VERSION ""

NS_ :

BS_:

BU_:

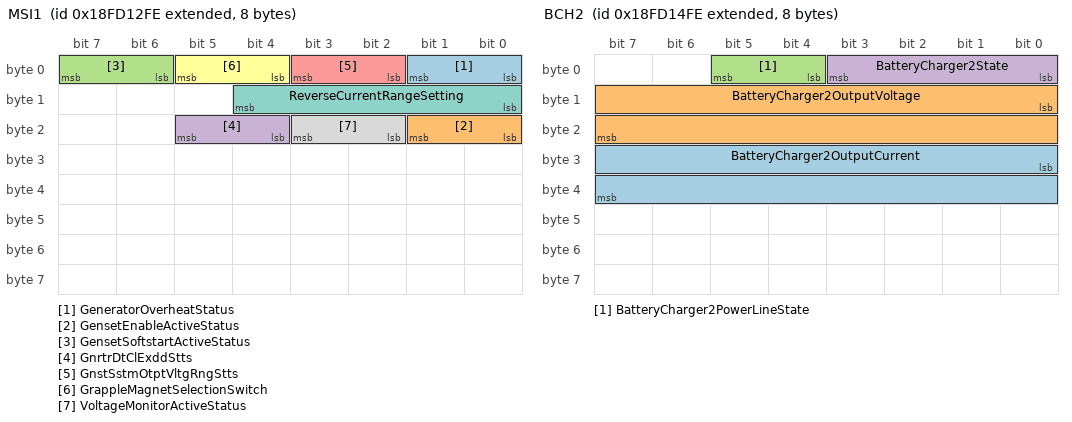
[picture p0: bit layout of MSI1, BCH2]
BO_ 2566722302 MSI1: 8 Vector__XXX
 SG_ GeneratorOverheatStatus : 0|2@1+ (1,0) [0|3] "" Vector__XXX
 SG_ GensetEnableActiveStatus : 16|2@1+ (1,0) [0|3] "" Vector__XXX
 SG_ GensetSoftstartActiveStatus : 6|2@1+ (1,0) [0|3] "" Vector__XXX
 SG_ GnrtrDtClExddStts : 20|2@1+ (1,0) [0|3] "" Vector__XXX
 SG_ GnstSstmOtptVltgRngStts : 2|2@1+ (1,0) [0|3] "" Vector__XXX
 SG_ GrappleMagnetSelectionSwitch : 4|2@1+ (1,0) [0|3] "" Vector__XXX
 SG_ ReverseCurrentRangeSetting : 8|5@1+ (1,0) [0|31] "" Vector__XXX
 SG_ VoltageMonitorActiveStatus : 18|2@1+ (1,0) [0|3] "" Vector__XXX

BO_ 2566722558 MSCI: 8 Vector__XXX
 SG_ MagnetBoostTime : 0|8@1+ (0.25,0) [0|62.5] "s" Vector__XXX
 SG_ MagnetRatedPower : 8|16@1+ (0.5,0) [0|32127.5] "kW" Vector__XXX

BO_ 2566722814 BCH2: 8 Vector__XXX
 SG_ BatteryCharger2OutputCurrent : 24|16@1+ (0.05,-1600) [-1600|1612.75] "A" Vector__XXX
 SG_ BatteryCharger2OutputVoltage : 8|16@1+ (0.05,0) [0|3212.75] "V" Vector__XXX
 SG_ BatteryCharger2PowerLineState : 4|2@1+ (1,0) [0|3] "" Vector__XXX
 SG_ BatteryCharger2State : 0|4@1+ (1,0) [0|15] "" Vector__XXX

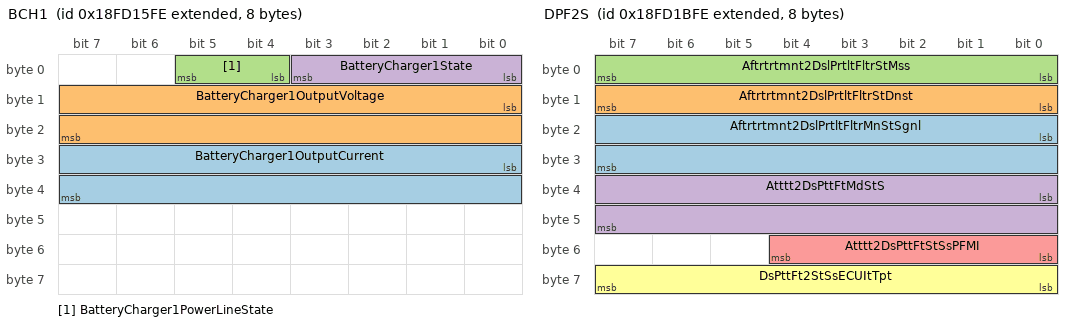
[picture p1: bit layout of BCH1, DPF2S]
BO_ 2566723070 BCH1: 8 Vector__XXX
 SG_ BatteryCharger1OutputCurrent : 24|16@1+ (0.05,-1600) [-1600|1612.75] "A" Vector__XXX
 SG_ BatteryCharger1OutputVoltage : 8|16@1+ (0.05,0) [0|3212.75] "V" Vector__XXX
 SG_ BatteryCharger1PowerLineState : 4|2@1+ (1,0) [0|3] "" Vector__XXX
 SG_ BatteryCharger1State : 0|4@1+ (1,0) [0|15] "" Vector__XXX

BO_ 2566724350 AT1WUDOC: 8 Vector__XXX
 SG_ Atttt1WUpDsOxdtCtstItTpt : 0|16@1+ (0.03125,-273) [-273|1734.96875] "degC" Vector__XXX
 SG_ Atttt1WUpDsOxdtCtstOttTpt : 16|16@1+ (0.03125,-273) [-273|1734.96875] "degC" Vector__XXX

BO_ 2566724606 DPF2S: 8 Vector__XXX
 SG_ Aftrtrtmnt2DslPrtltFltrMnStSgnl : 16|16@1+ (0.0025,0) [0|160.6375] "%" Vector__XXX
 SG_ Aftrtrtmnt2DslPrtltFltrStDnst : 8|8@1+ (0.08,0) [0|20] "g/L" Vector__XXX
 SG_ Aftrtrtmnt2DslPrtltFltrStMss : 0|8@1+ (4,0) [0|1000] "g" Vector__XXX
 SG_ Atttt2DsPttFtMdStS : 32|16@1+ (0.0025,0) [0|160.6375] "%" Vector__XXX
 SG_ Atttt2DsPttFtStSsPFMI : 48|5@1+ (1,0) [0|31] "binary" Vector__XXX
 SG_ DsPttFt2StSsECUItTpt : 56|8@1+ (1,-40) [-40|210] "degC" Vector__XXX

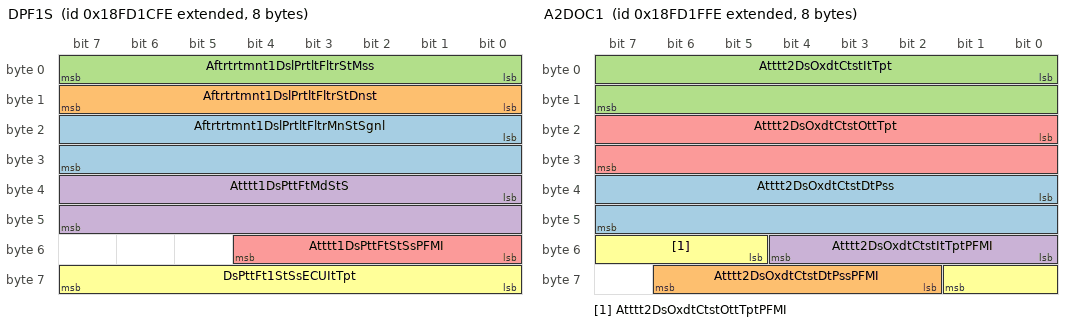
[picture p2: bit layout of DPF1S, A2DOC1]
BO_ 2566724862 DPF1S: 8 Vector__XXX
 SG_ Aftrtrtmnt1DslPrtltFltrMnStSgnl : 16|16@1+ (0.0025,0) [0|160.6375] "%" Vector__XXX
 SG_ Aftrtrtmnt1DslPrtltFltrStDnst : 8|8@1+ (0.08,0) [0|20] "g/L" Vector__XXX
 SG_ Aftrtrtmnt1DslPrtltFltrStMss : 0|8@1+ (4,0) [0|1000] "g" Vector__XXX
 SG_ Atttt1DsPttFtMdStS : 32|16@1+ (0.0025,0) [0|160.6375] "%" Vector__XXX
 SG_ Atttt1DsPttFtStSsPFMI : 48|5@1+ (1,0) [0|31] "binary" Vector__XXX
 SG_ DsPttFt1StSsECUItTpt : 56|8@1+ (1,-40) [-40|210] "degC" Vector__XXX

BO_ 2566725118 ATDT2: 8 Vector__XXX
 SG_ Atttt1TWCtstDtTpt : 0|16@1+ (0.03125,-273) [-273|1734.96875] "degC" Vector__XXX
 SG_ Atttt2TWCtstDtTpt : 16|16@1+ (0.03125,-273) [-273|1734.96875] "degC" Vector__XXX

BO_ 2566725374 ATDT1: 8 Vector__XXX
 SG_ Atttt1GsOxdtCtstDtTpt : 0|16@1+ (0.03125,-273) [-273|1734.96875] "degC" Vector__XXX
 SG_ Atttt2GsOxdtCtstDtTpt : 16|16@1+ (0.03125,-273) [-273|1734.96875] "degC" Vector__XXX

BO_ 2566725630 A2DOC1: 8 Vector__XXX
 SG_ Atttt2DsOxdtCtstDtPss : 32|16@1+ (0.5,0) [0|32127.5] "kPa" Vector__XXX
 SG_ Atttt2DsOxdtCtstDtPssPFMI : 58|5@1+ (1,0) [0|31] "binary" Vector__XXX
 SG_ Atttt2DsOxdtCtstItTpt : 0|16@1+ (0.03125,-273) [-273|1734.96875] "degC" Vector__XXX
 SG_ Atttt2DsOxdtCtstItTptPFMI : 48|5@1+ (1,0) [0|31] "binary" Vector__XXX
 SG_ Atttt2DsOxdtCtstOttTpt : 16|16@1+ (0.03125,-273) [-273|1734.96875] "degC" Vector__XXX
 SG_ Atttt2DsOxdtCtstOttTptPFMI : 53|5@1+ (1,0) [0|31] "binary" Vector__XXX

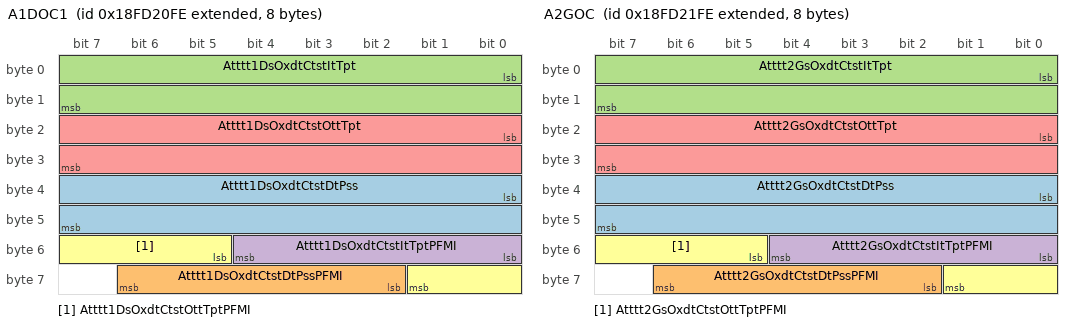
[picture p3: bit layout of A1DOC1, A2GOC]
BO_ 2566725886 A1DOC1: 8 Vector__XXX
 SG_ Atttt1DsOxdtCtstDtPss : 32|16@1+ (0.1,0) [0|6425.5] "kPa" Vector__XXX
 SG_ Atttt1DsOxdtCtstDtPssPFMI : 58|5@1+ (1,0) [0|31] "binary" Vector__XXX
 SG_ Atttt1DsOxdtCtstItTpt : 0|16@1+ (0.03125,-273) [-273|1734.96875] "degC" Vector__XXX
 SG_ Atttt1DsOxdtCtstItTptPFMI : 48|5@1+ (1,0) [0|31] "binary" Vector__XXX
 SG_ Atttt1DsOxdtCtstOttTpt : 16|16@1+ (0.03125,-273) [-273|1734.96875] "degC" Vector__XXX
 SG_ Atttt1DsOxdtCtstOttTptPFMI : 53|5@1+ (1,0) [0|31] "binary" Vector__XXX

BO_ 2566726142 A2GOC: 8 Vector__XXX
 SG_ Atttt2GsOxdtCtstDtPss : 32|16@1+ (0.1,0) [0|6425.5] "kPa" Vector__XXX
 SG_ Atttt2GsOxdtCtstDtPssPFMI : 58|5@1+ (1,0) [0|31] "binary" Vector__XXX
 SG_ Atttt2GsOxdtCtstItTpt : 0|16@1+ (0.03125,-273) [-273|1734.96875] "degC" Vector__XXX
 SG_ Atttt2GsOxdtCtstItTptPFMI : 48|5@1+ (1,0) [0|31] "binary" Vector__XXX
 SG_ Atttt2GsOxdtCtstOttTpt : 16|16@1+ (0.03125,-273) [-273|1734.96875] "degC" Vector__XXX
 SG_ Atttt2GsOxdtCtstOttTptPFMI : 53|5@1+ (1,0) [0|31] "binary" Vector__XXX

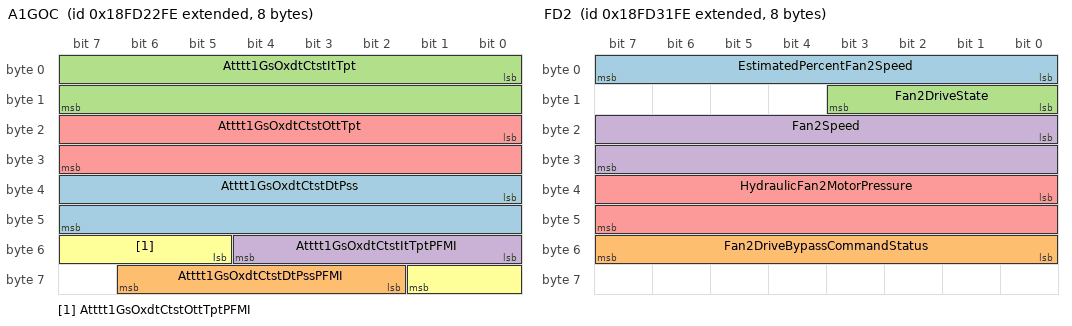
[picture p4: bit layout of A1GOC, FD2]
BO_ 2566726398 A1GOC: 8 Vector__XXX
 SG_ Atttt1GsOxdtCtstDtPss : 32|16@1+ (0.1,0) [0|6425.5] "kPa" Vector__XXX
 SG_ Atttt1GsOxdtCtstDtPssPFMI : 58|5@1+ (1,0) [0|31] "binary" Vector__XXX
 SG_ Atttt1GsOxdtCtstItTpt : 0|16@1+ (0.03125,-273) [-273|1734.96875] "degC" Vector__XXX
 SG_ Atttt1GsOxdtCtstItTptPFMI : 48|5@1+ (1,0) [0|31] "binary" Vector__XXX
 SG_ Atttt1GsOxdtCtstOttTpt : 16|16@1+ (0.03125,-273) [-273|1734.96875] "degC" Vector__XXX
 SG_ Atttt1GsOxdtCtstOttTptPFMI : 53|5@1+ (1,0) [0|31] "binary" Vector__XXX

BO_ 2566730238 FD2: 8 Vector__XXX
 SG_ EstimatedPercentFan2Speed : 0|8@1+ (0.4,0) [0|100] "%" Vector__XXX
 SG_ Fan2DriveBypassCommandStatus : 48|8@1+ (0.4,0) [0|100] "%" Vector__XXX
 SG_ Fan2DriveState : 8|4@1+ (1,0) [0|15] "" Vector__XXX
 SG_ Fan2Speed : 16|16@1+ (0.125,0) [0|8031.875] "rpm" Vector__XXX
 SG_ HydraulicFan2MotorPressure : 32|16@1+ (0.5,0) [0|32127.5] "kPa" Vector__XXX

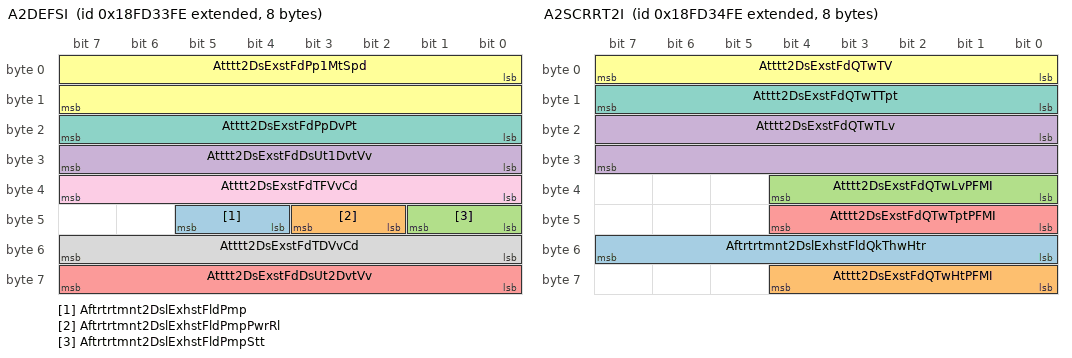
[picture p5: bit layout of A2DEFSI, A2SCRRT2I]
BO_ 2566730750 A2DEFSI: 8 Vector__XXX
 SG_ Aftrtrtmnt2DslExhstFldPmp : 44|2@1+ (1,0) [0|3] "" Vector__XXX
 SG_ Aftrtrtmnt2DslExhstFldPmpPwrRl : 42|2@1+ (1,0) [0|3] "" Vector__XXX
 SG_ Aftrtrtmnt2DslExhstFldPmpStt : 40|2@1+ (1,0) [0|3] "" Vector__XXX
 SG_ Atttt2DsExstFdDsUt1DvtVv : 24|8@1+ (0.4,0) [0|100] "%" Vector__XXX
 SG_ Atttt2DsExstFdDsUt2DvtVv : 56|8@1+ (0.4,0) [0|100] "%" Vector__XXX
 SG_ Atttt2DsExstFdPp1MtSpd : 0|16@1+ (0.5,0) [0|32127.5] "rpm" Vector__XXX
 SG_ Atttt2DsExstFdPpDvPt : 16|8@1+ (0.4,0) [0|100] "%" Vector__XXX
 SG_ Atttt2DsExstFdTDVvCd : 48|8@1+ (0.4,0) [0|100] "%" Vector__XXX
 SG_ Atttt2DsExstFdTFVvCd : 32|8@1+ (0.4,0) [0|100] "%" Vector__XXX

BO_ 2566731006 A2SCRRT2I: 8 Vector__XXX
 SG_ Aftrtrtmnt2DslExhstFldQkThwHtr : 48|8@1+ (0.4,0) [0|100] "%" Vector__XXX
 SG_ Atttt2DsExstFdQTwHtPFMI : 56|5@1+ (1,0) [0|31] "binary" Vector__XXX
 SG_ Atttt2DsExstFdQTwLvPFMI : 32|5@1+ (1,0) [0|31] "binary" Vector__XXX
 SG_ Atttt2DsExstFdQTwTLv : 16|16@1+ (0.1,0) [0|6425.5] "mm" Vector__XXX
 SG_ Atttt2DsExstFdQTwTptPFMI : 40|5@1+ (1,0) [0|31] "binary" Vector__XXX
 SG_ Atttt2DsExstFdQTwTV : 0|8@1+ (0.4,0) [0|100] "%" Vector__XXX
 SG_ Atttt2DsExstFdQTwTTpt : 8|8@1+ (1,-40) [-40|210] "degC" Vector__XXX

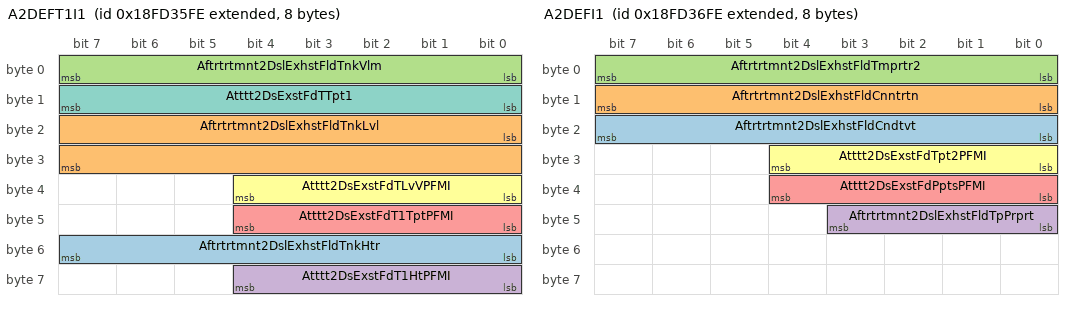
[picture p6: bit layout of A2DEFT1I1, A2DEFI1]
BO_ 2566731262 A2DEFT1I1: 8 Vector__XXX
 SG_ Aftrtrtmnt2DslExhstFldTnkHtr : 48|8@1+ (0.4,0) [0|100] "%" Vector__XXX
 SG_ Aftrtrtmnt2DslExhstFldTnkLvl : 16|16@1+ (0.1,0) [0|6425.5] "mm" Vector__XXX
 SG_ Aftrtrtmnt2DslExhstFldTnkVlm : 0|8@1+ (0.4,0) [0|100] "%" Vector__XXX
 SG_ Atttt2DsExstFdT1HtPFMI : 56|5@1+ (1,0) [0|31] "binary" Vector__XXX
 SG_ Atttt2DsExstFdT1TptPFMI : 40|5@1+ (1,0) [0|31] "binary" Vector__XXX
 SG_ Atttt2DsExstFdTLvVPFMI : 32|5@1+ (1,0) [0|31] "binary" Vector__XXX
 SG_ Atttt2DsExstFdTTpt1 : 8|8@1+ (1,-40) [-40|210] "degC" Vector__XXX

BO_ 2566731518 A2DEFI1: 8 Vector__XXX
 SG_ Aftrtrtmnt2DslExhstFldCndtvt : 16|8@1+ (5,0) [0|1250] "µSiemens/mm" Vector__XXX
 SG_ Aftrtrtmnt2DslExhstFldCnntrtn : 8|8@1+ (0.25,0) [0|62.5] "%" Vector__XXX
 SG_ Aftrtrtmnt2DslExhstFldTmprtr2 : 0|8@1+ (1,-40) [-40|210] "degC" Vector__XXX
 SG_ Aftrtrtmnt2DslExhstFldTpPrprt : 40|4@1+ (1,0) [0|15] "" Vector__XXX
 SG_ Atttt2DsExstFdPptsPFMI : 32|5@1+ (1,0) [0|31] "binary" Vector__XXX
 SG_ Atttt2DsExstFdTpt2PFMI : 24|5@1+ (1,0) [0|31] "binary" Vector__XXX

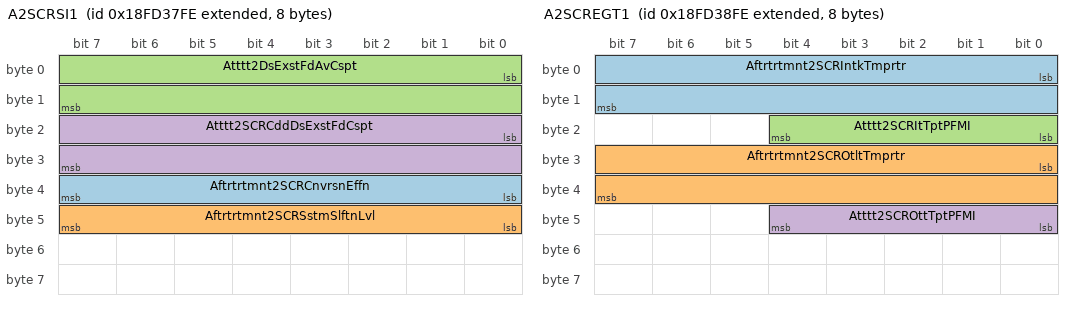
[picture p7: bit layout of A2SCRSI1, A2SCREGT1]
BO_ 2566731774 A2SCRSI1: 8 Vector__XXX
 SG_ Aftrtrtmnt2SCRCnvrsnEffn : 32|8@1+ (0.4,0) [0|100] "%" Vector__XXX
 SG_ Aftrtrtmnt2SCRSstmSlftnLvl : 40|8@1+ (1,0) [0|250] "%" Vector__XXX
 SG_ Atttt2DsExstFdAvCspt : 0|16@1+ (0.05,0) [0|3212.75] "l/h" Vector__XXX
 SG_ Atttt2SCRCddDsExstFdCspt : 16|16@1+ (0.05,0) [0|3212.75] "l/h" Vector__XXX

BO_ 2566732030 A2SCREGT1: 8 Vector__XXX
 SG_ Aftrtrtmnt2SCRIntkTmprtr : 0|16@1+ (0.03125,-273) [-273|1734.96875] "degC" Vector__XXX
 SG_ Aftrtrtmnt2SCROtltTmprtr : 24|16@1+ (0.03125,-273) [-273|1734.96875] "degC" Vector__XXX
 SG_ Atttt2SCRItTptPFMI : 16|5@1+ (1,0) [0|31] "" Vector__XXX
 SG_ Atttt2SCROttTptPFMI : 40|5@1+ (1,0) [0|31] "" Vector__XXX

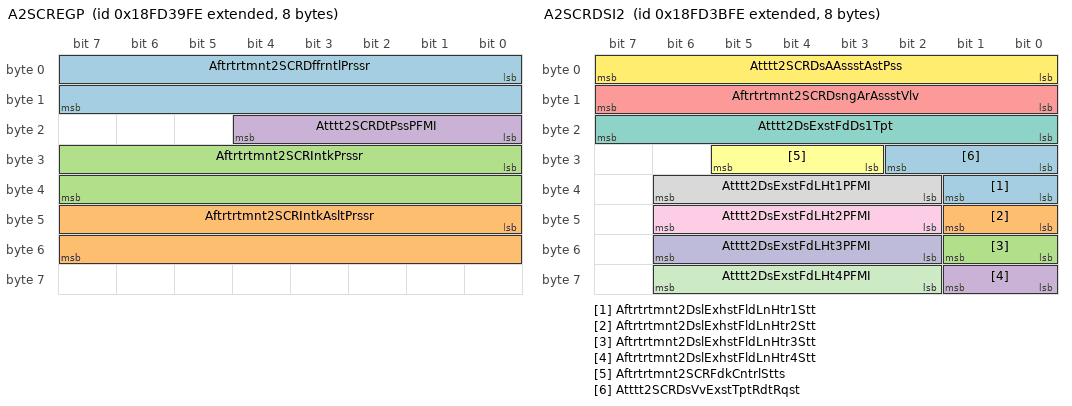
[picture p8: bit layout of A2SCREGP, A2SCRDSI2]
BO_ 2566732286 A2SCREGP: 8 Vector__XXX
 SG_ Aftrtrtmnt2SCRDffrntlPrssr : 0|16@1+ (0.1,0) [0|6425.5] "kPa" Vector__XXX
 SG_ Aftrtrtmnt2SCRIntkAsltPrssr : 40|16@1+ (0.1,0) [0|6425.5] "kPa" Vector__XXX
 SG_ Aftrtrtmnt2SCRIntkPrssr : 24|16@1+ (0.1,-3212.7) [-3212.7|3212.8] "kPa" Vector__XXX
 SG_ Atttt2SCRDtPssPFMI : 16|5@1+ (1,0) [0|31] "" Vector__XXX

BO_ 2566732542 A2SCRDSR2: 8 Vector__XXX
 SG_ Aftrtrtmnt2DslExhstFldLnHtr1 : 8|2@1+ (1,0) [0|3] "" Vector__XXX
 SG_ Aftrtrtmnt2DslExhstFldLnHtr10 : 48|2@1+ (1,0) [0|3] "" Vector__XXX
 SG_ Aftrtrtmnt2DslExhstFldLnHtr2 : 10|2@1+ (1,0) [0|3] "" Vector__XXX
 SG_ Aftrtrtmnt2DslExhstFldLnHtr3 : 12|2@1+ (1,0) [0|3] "" Vector__XXX
 SG_ Aftrtrtmnt2DslExhstFldLnHtr4 : 14|2@1+ (1,0) [0|3] "" Vector__XXX
 SG_ Aftrtrtmnt2DslExhstFldLnHtr5 : 38|2@1+ (1,0) [0|3] "" Vector__XXX
 SG_ Aftrtrtmnt2DslExhstFldLnHtr6 : 40|2@1+ (1,0) [0|3] "" Vector__XXX
 SG_ Aftrtrtmnt2DslExhstFldLnHtr7 : 42|2@1+ (1,0) [0|3] "" Vector__XXX
 SG_ Aftrtrtmnt2DslExhstFldLnHtr8 : 44|2@1+ (1,0) [0|3] "" Vector__XXX
 SG_ Aftrtrtmnt2DslExhstFldLnHtr9 : 46|2@1+ (1,0) [0|3] "" Vector__XXX
 SG_ Aftrtrtmnt2DslExhstFldLnHtrRl1 : 32|2@1+ (1,0) [0|3] "" Vector__XXX
 SG_ Aftrtrtmnt2DslExhstFldLnHtrRl2 : 34|2@1+ (1,0) [0|3] "" Vector__XXX
 SG_ Aftrtrtmnt2DslExhstFldLnHtrRl3 : 36|2@1+ (1,0) [0|3] "" Vector__XXX
 SG_ Atttt2DsExstFdDsFtSppssRqst : 2|2@1+ (1,0) [0|3] "" Vector__XXX
 SG_ Atttt2DsExstFdDsHtMdRqst : 4|3@1+ (1,0) [0|7] "" Vector__XXX
 SG_ Atttt2DsExstFdQTwHtCd : 24|8@1+ (0.4,0) [0|100] "%" Vector__XXX
 SG_ Atttt2DsExstFdTHtCd : 16|8@1+ (0.4,0) [0|100] "%" Vector__XXX

BO_ 2566732798 A2SCRDSI2: 8 Vector__XXX
 SG_ Aftrtrtmnt2DslExhstFldLnHtr1Stt : 32|2@1+ (1,0) [0|3] "" Vector__XXX
 SG_ Aftrtrtmnt2DslExhstFldLnHtr2Stt : 40|2@1+ (1,0) [0|3] "" Vector__XXX
 SG_ Aftrtrtmnt2DslExhstFldLnHtr3Stt : 48|2@1+ (1,0) [0|3] "" Vector__XXX
 SG_ Aftrtrtmnt2DslExhstFldLnHtr4Stt : 56|2@1+ (1,0) [0|3] "" Vector__XXX
 SG_ Aftrtrtmnt2SCRDsngArAssstVlv : 8|8@1+ (0.4,0) [0|100] "%" Vector__XXX
 SG_ Aftrtrtmnt2SCRFdkCntrlStts : 27|3@1+ (1,0) [0|7] "" Vector__XXX
 SG_ Atttt2DsExstFdDs1Tpt : 16|8@1+ (1,-40) [-40|210] "degC" Vector__XXX
 SG_ Atttt2DsExstFdLHt1PFMI : 34|5@1+ (1,0) [0|31] "binary" Vector__XXX
 SG_ Atttt2DsExstFdLHt2PFMI : 42|5@1+ (1,0) [0|31] "binary" Vector__XXX
 SG_ Atttt2DsExstFdLHt3PFMI : 50|5@1+ (1,0) [0|31] "binary" Vector__XXX
 SG_ Atttt2DsExstFdLHt4PFMI : 58|5@1+ (1,0) [0|31] "binary" Vector__XXX
 SG_ Atttt2SCRDsAAssstAstPss : 0|8@1+ (8,0) [0|2000] "kPa" Vector__XXX
 SG_ Atttt2SCRDsVvExstTptRdtRqst : 24|3@1+ (1,0) [0|7] "" Vector__XXX

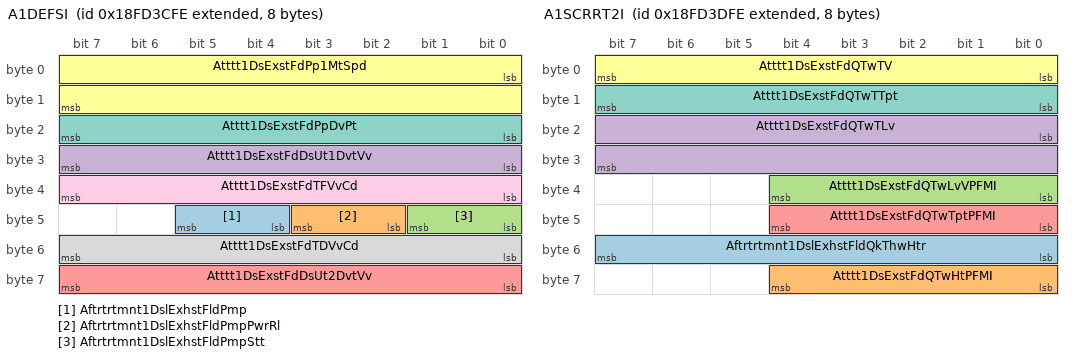
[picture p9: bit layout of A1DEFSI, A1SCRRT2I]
BO_ 2566733054 A1DEFSI: 8 Vector__XXX
 SG_ Aftrtrtmnt1DslExhstFldPmp : 44|2@1+ (1,0) [0|3] "" Vector__XXX
 SG_ Aftrtrtmnt1DslExhstFldPmpPwrRl : 42|2@1+ (1,0) [0|3] "" Vector__XXX
 SG_ Aftrtrtmnt1DslExhstFldPmpStt : 40|2@1+ (1,0) [0|3] "" Vector__XXX
 SG_ Atttt1DsExstFdDsUt1DvtVv : 24|8@1+ (0.4,0) [0|100] "%" Vector__XXX
 SG_ Atttt1DsExstFdDsUt2DvtVv : 56|8@1+ (0.4,0) [0|100] "%" Vector__XXX
 SG_ Atttt1DsExstFdPp1MtSpd : 0|16@1+ (0.5,0) [0|32127.5] "rpm" Vector__XXX
 SG_ Atttt1DsExstFdPpDvPt : 16|8@1+ (0.4,0) [0|100] "%" Vector__XXX
 SG_ Atttt1DsExstFdTDVvCd : 48|8@1+ (0.4,0) [0|100] "%" Vector__XXX
 SG_ Atttt1DsExstFdTFVvCd : 32|8@1+ (0.4,0) [0|100] "%" Vector__XXX

BO_ 2566733310 A1SCRRT2I: 8 Vector__XXX
 SG_ Aftrtrtmnt1DslExhstFldQkThwHtr : 48|8@1+ (0.4,0) [0|100] "%" Vector__XXX
 SG_ Atttt1DsExstFdQTwHtPFMI : 56|5@1+ (1,0) [0|31] "binary" Vector__XXX
 SG_ Atttt1DsExstFdQTwLvVPFMI : 32|5@1+ (1,0) [0|31] "binary" Vector__XXX
 SG_ Atttt1DsExstFdQTwTLv : 16|16@1+ (0.1,0) [0|6425.5] "mm" Vector__XXX
 SG_ Atttt1DsExstFdQTwTptPFMI : 40|5@1+ (1,0) [0|31] "binary" Vector__XXX
 SG_ Atttt1DsExstFdQTwTV : 0|8@1+ (0.4,0) [0|100] "%" Vector__XXX
 SG_ Atttt1DsExstFdQTwTTpt : 8|8@1+ (1,-40) [-40|210] "degC" Vector__XXX

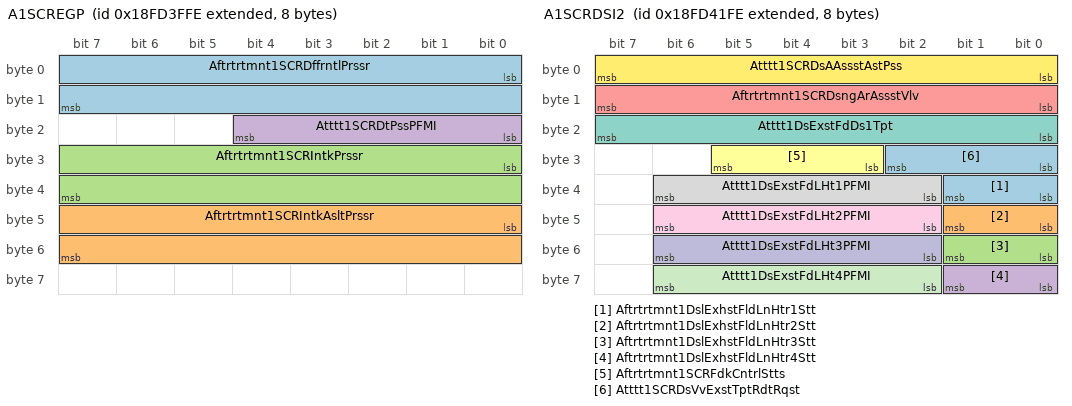
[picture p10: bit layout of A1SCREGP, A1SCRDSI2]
BO_ 2566733822 A1SCREGP: 8 Vector__XXX
 SG_ Aftrtrtmnt1SCRDffrntlPrssr : 0|16@1+ (0.1,0) [0|6425.5] "kPa" Vector__XXX
 SG_ Aftrtrtmnt1SCRIntkAsltPrssr : 40|16@1+ (0.1,0) [0|6425.5] "kPa" Vector__XXX
 SG_ Aftrtrtmnt1SCRIntkPrssr : 24|16@1+ (0.1,-3212.7) [-3212.7|3212.8] "kPa" Vector__XXX
 SG_ Atttt1SCRDtPssPFMI : 16|5@1+ (1,0) [0|31] "" Vector__XXX

BO_ 2566734078 A1SCRDSR2: 8 Vector__XXX
 SG_ Aftrtrtmnt1DslExhstFldLnHtr1 : 8|2@1+ (1,0) [0|3] "" Vector__XXX
 SG_ Aftrtrtmnt1DslExhstFldLnHtr10 : 56|2@1+ (1,0) [0|3] "" Vector__XXX
 SG_ Aftrtrtmnt1DslExhstFldLnHtr2 : 10|2@1+ (1,0) [0|3] "" Vector__XXX
 SG_ Aftrtrtmnt1DslExhstFldLnHtr3 : 12|2@1+ (1,0) [0|3] "" Vector__XXX
 SG_ Aftrtrtmnt1DslExhstFldLnHtr4 : 14|2@1+ (1,0) [0|3] "" Vector__XXX
 SG_ Aftrtrtmnt1DslExhstFldLnHtr5 : 46|2@1+ (1,0) [0|3] "" Vector__XXX
 SG_ Aftrtrtmnt1DslExhstFldLnHtr6 : 48|2@1+ (1,0) [0|3] "" Vector__XXX
 SG_ Aftrtrtmnt1DslExhstFldLnHtr7 : 50|2@1+ (1,0) [0|3] "" Vector__XXX
 SG_ Aftrtrtmnt1DslExhstFldLnHtr8 : 52|2@1+ (1,0) [0|3] "" Vector__XXX
 SG_ Aftrtrtmnt1DslExhstFldLnHtr9 : 54|2@1+ (1,0) [0|3] "" Vector__XXX
 SG_ Aftrtrtmnt1DslExhstFldLnHtrRl1 : 40|2@1+ (1,0) [0|3] "" Vector__XXX
 SG_ Aftrtrtmnt1DslExhstFldLnHtrRl2 : 42|2@1+ (1,0) [0|3] "" Vector__XXX
 SG_ Aftrtrtmnt1DslExhstFldLnHtrRl3 : 44|2@1+ (1,0) [0|3] "" Vector__XXX
 SG_ Atttt1DsExstFdDsFtSppssRqst : 2|2@1+ (1,0) [0|3] "" Vector__XXX
 SG_ Atttt1DsExstFdDsHtMdRqst : 4|3@1+ (1,0) [0|7] "" Vector__XXX
 SG_ Atttt1DsExstFdPpHtCd : 32|8@1+ (0.4,0) [0|100] "%" Vector__XXX
 SG_ Atttt1DsExstFdQTwHtCd : 24|8@1+ (0.4,0) [0|100] "%" Vector__XXX
 SG_ Atttt1DsExstFdTHtCd : 16|8@1+ (0.4,0) [0|100] "%" Vector__XXX

BO_ 2566734334 A1SCRDSI2: 8 Vector__XXX
 SG_ Aftrtrtmnt1DslExhstFldLnHtr1Stt : 32|2@1+ (1,0) [0|3] "" Vector__XXX
 SG_ Aftrtrtmnt1DslExhstFldLnHtr2Stt : 40|2@1+ (1,0) [0|3] "" Vector__XXX
 SG_ Aftrtrtmnt1DslExhstFldLnHtr3Stt : 48|2@1+ (1,0) [0|3] "" Vector__XXX
 SG_ Aftrtrtmnt1DslExhstFldLnHtr4Stt : 56|2@1+ (1,0) [0|3] "" Vector__XXX
 SG_ Aftrtrtmnt1SCRDsngArAssstVlv : 8|8@1+ (0.4,0) [0|100] "%" Vector__XXX
 SG_ Aftrtrtmnt1SCRFdkCntrlStts : 27|3@1+ (1,0) [0|7] "" Vector__XXX
 SG_ Atttt1DsExstFdDs1Tpt : 16|8@1+ (1,-40) [-40|210] "degC" Vector__XXX
 SG_ Atttt1DsExstFdLHt1PFMI : 34|5@1+ (1,0) [0|31] "binary" Vector__XXX
 SG_ Atttt1DsExstFdLHt2PFMI : 42|5@1+ (1,0) [0|31] "binary" Vector__XXX
 SG_ Atttt1DsExstFdLHt3PFMI : 50|5@1+ (1,0) [0|31] "binary" Vector__XXX
 SG_ Atttt1DsExstFdLHt4PFMI : 58|5@1+ (1,0) [0|31] "binary" Vector__XXX
 SG_ Atttt1SCRDsAAssstAstPss : 0|8@1+ (8,0) [0|2000] "kPa" Vector__XXX
 SG_ Atttt1SCRDsVvExstTptRdtRqst : 24|3@1+ (1,0) [0|7] "" Vector__XXX

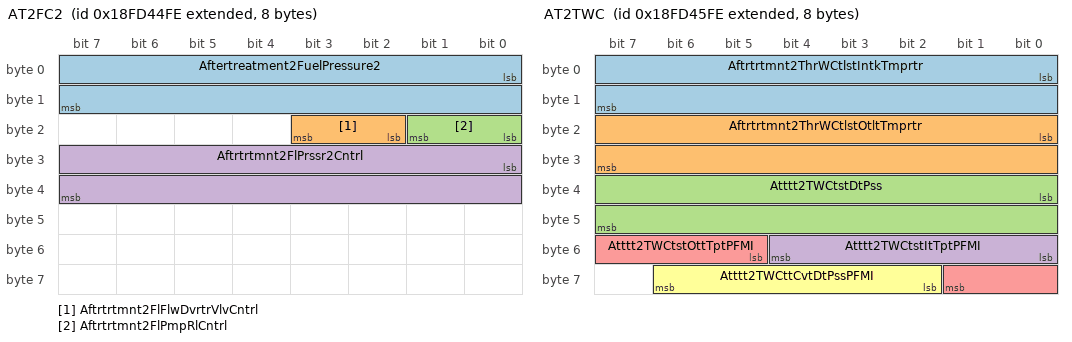
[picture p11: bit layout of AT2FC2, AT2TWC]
BO_ 2566735102 AT2FC2: 8 Vector__XXX
 SG_ Aftertreatment2FuelPressure2 : 0|16@1+ (0.1,0) [0|6425.5] "kPa" Vector__XXX
 SG_ Aftrtrtmnt2FlFlwDvrtrVlvCntrl : 18|2@1+ (1,0) [0|3] "" Vector__XXX
 SG_ Aftrtrtmnt2FlPmpRlCntrl : 16|2@1+ (1,0) [0|3] "" Vector__XXX
 SG_ Aftrtrtmnt2FlPrssr2Cntrl : 24|16@1+ (0.0025,0) [0|160.6375] "%" Vector__XXX

BO_ 2566735358 AT2TWC: 8 Vector__XXX
 SG_ Aftrtrtmnt2ThrWCtlstIntkTmprtr : 0|16@1+ (0.03125,-273) [-273|1734.96875] "degC" Vector__XXX
 SG_ Aftrtrtmnt2ThrWCtlstOtltTmprtr : 16|16@1+ (0.03125,-273) [-273|1734.96875] "degC" Vector__XXX
 SG_ Atttt2TWCtstDtPss : 32|16@1+ (0.1,0) [0|6425.5] "kPa" Vector__XXX
 SG_ Atttt2TWCtstItTptPFMI : 48|5@1+ (1,0) [0|31] "binary" Vector__XXX
 SG_ Atttt2TWCtstOttTptPFMI : 53|5@1+ (1,0) [0|31] "binary" Vector__XXX
 SG_ Atttt2TWCttCvtDtPssPFMI : 58|5@1+ (1,0) [0|31] "binary" Vector__XXX

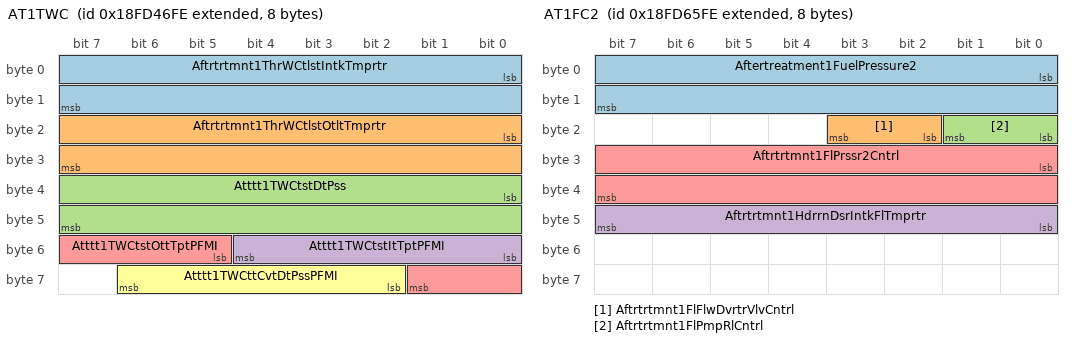
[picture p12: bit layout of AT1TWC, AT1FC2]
BO_ 2566735614 AT1TWC: 8 Vector__XXX
 SG_ Aftrtrtmnt1ThrWCtlstIntkTmprtr : 0|16@1+ (0.03125,-273) [-273|1734.96875] "degC" Vector__XXX
 SG_ Aftrtrtmnt1ThrWCtlstOtltTmprtr : 16|16@1+ (0.03125,-273) [-273|1734.96875] "degC" Vector__XXX
 SG_ Atttt1TWCtstDtPss : 32|16@1+ (0.1,0) [0|6425.5] "kPa" Vector__XXX
 SG_ Atttt1TWCtstItTptPFMI : 48|5@1+ (1,0) [0|31] "binary" Vector__XXX
 SG_ Atttt1TWCtstOttTptPFMI : 53|5@1+ (1,0) [0|31] "binary" Vector__XXX
 SG_ Atttt1TWCttCvtDtPssPFMI : 58|5@1+ (1,0) [0|31] "binary" Vector__XXX

BO_ 2566736126 O2FT2: 8 Vector__XXX
 SG_ EngnExhstBnk2O2SnsrClsdLpOprtn : 32|4@1+ (1,0) [0|15] "" Vector__XXX
 SG_ LongtermFuelTrimBank2 : 0|16@1+ (0.1,-100) [-100|6325.5] "%" Vector__XXX
 SG_ ShorttermFuelTrimBank2 : 16|16@1+ (0.1,-100) [-100|6325.5] "%" Vector__XXX

BO_ 2566736382 O2FT1: 8 Vector__XXX
 SG_ EngnExhstBnk1O2SnsrClsdLpOprtn : 32|4@1+ (1,0) [0|15] "" Vector__XXX
 SG_ LongtermFuelTrimBank1 : 0|16@1+ (0.1,-100) [-100|6325.5] "%" Vector__XXX
 SG_ ShorttermFuelTrimBank1 : 16|16@1+ (0.1,-100) [-100|6325.5] "%" Vector__XXX

BO_ 2566743550 AT1FC2: 8 Vector__XXX
 SG_ Aftertreatment1FuelPressure2 : 0|16@1+ (0.1,0) [0|6425.5] "kPa" Vector__XXX
 SG_ Aftrtrtmnt1FlFlwDvrtrVlvCntrl : 18|2@1+ (1,0) [0|3] "" Vector__XXX
 SG_ Aftrtrtmnt1FlPmpRlCntrl : 16|2@1+ (1,0) [0|3] "" Vector__XXX
 SG_ Aftrtrtmnt1HdrrnDsrIntkFlTmprtr : 40|8@1+ (1,-40) [-40|210] "degC" Vector__XXX
 SG_ Aftrtrtmnt1FlPrssr2Cntrl : 24|16@1+ (0.0025,0) [0|160.6375] "%" Vector__XXX

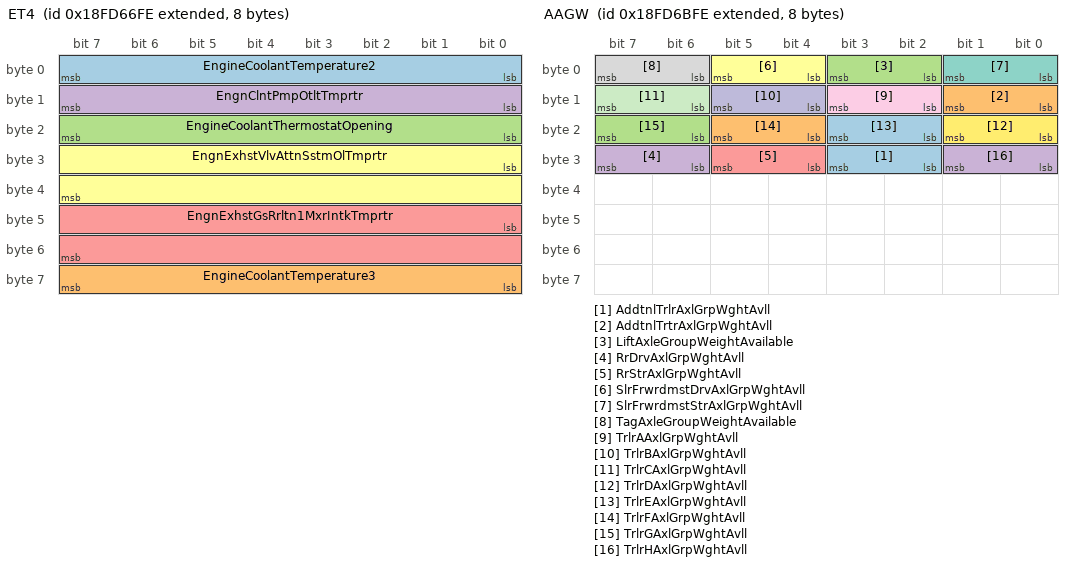
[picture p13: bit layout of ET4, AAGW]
BO_ 2566743806 ET4: 8 Vector__XXX
 SG_ EngineCoolantTemperature2 : 0|8@1+ (1,-40) [-40|210] "degC" Vector__XXX
 SG_ EngineCoolantTemperature3 : 56|8@1+ (1,-40) [-40|210] "degC" Vector__XXX
 SG_ EngineCoolantThermostatOpening : 16|8@1+ (0.4,0) [0|100] "%" Vector__XXX
 SG_ EngnClntPmpOtltTmprtr : 8|8@1+ (1,-40) [-40|210] "degC" Vector__XXX
 SG_ EngnExhstGsRrltn1MxrIntkTmprtr : 40|16@1+ (0.03125,-273) [-273|1734.96875] "degC" Vector__XXX
 SG_ EngnExhstVlvAttnSstmOlTmprtr : 24|16@1+ (0.03125,-273) [-273|1734.96875] "degC" Vector__XXX

BO_ 2566744062 ZNVW: 8 Vector__XXX
 SG_ ZeroNetVehicleWeightChange : 0|2@1+ (1,0) [0|3] "" Vector__XXX

BO_ 2566745086 AAGW: 8 Vector__XXX
 SG_ AddtnlTrlrAxlGrpWghtAvll : 26|2@1+ (1,0) [0|3] "" Vector__XXX
 SG_ AddtnlTrtrAxlGrpWghtAvll : 8|2@1+ (1,0) [0|3] "" Vector__XXX
 SG_ LiftAxleGroupWeightAvailable : 2|2@1+ (1,0) [0|3] "" Vector__XXX
 SG_ RrDrvAxlGrpWghtAvll : 30|2@1+ (1,0) [0|3] "" Vector__XXX
 SG_ RrStrAxlGrpWghtAvll : 28|2@1+ (1,0) [0|3] "" Vector__XXX
 SG_ SlrFrwrdmstDrvAxlGrpWghtAvll : 4|2@1+ (1,0) [0|3] "" Vector__XXX
 SG_ SlrFrwrdmstStrAxlGrpWghtAvll : 0|2@1+ (1,0) [0|3] "" Vector__XXX
 SG_ TagAxleGroupWeightAvailable : 6|2@1+ (1,0) [0|3] "" Vector__XXX
 SG_ TrlrAAxlGrpWghtAvll : 10|2@1+ (1,0) [0|3] "" Vector__XXX
 SG_ TrlrBAxlGrpWghtAvll : 12|2@1+ (1,0) [0|3] "" Vector__XXX
 SG_ TrlrCAxlGrpWghtAvll : 14|2@1+ (1,0) [0|3] "" Vector__XXX
 SG_ TrlrDAxlGrpWghtAvll : 16|2@1+ (1,0) [0|3] "" Vector__XXX
 SG_ TrlrEAxlGrpWghtAvll : 18|2@1+ (1,0) [0|3] "" Vector__XXX
 SG_ TrlrFAxlGrpWghtAvll : 20|2@1+ (1,0) [0|3] "" Vector__XXX
 SG_ TrlrGAxlGrpWghtAvll : 22|2@1+ (1,0) [0|3] "" Vector__XXX
 SG_ TrlrHAxlGrpWghtAvll : 24|2@1+ (1,0) [0|3] "" Vector__XXX

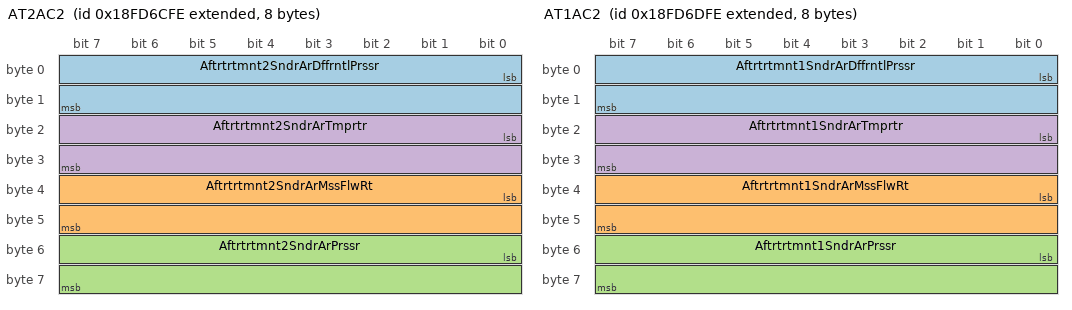
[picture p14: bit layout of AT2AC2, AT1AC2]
BO_ 2566745342 AT2AC2: 8 Vector__XXX
 SG_ Aftrtrtmnt2SndrArDffrntlPrssr : 0|16@1+ (0.0078125,-250) [-250|251.99] "kPa" Vector__XXX
 SG_ Aftrtrtmnt2SndrArMssFlwRt : 32|16@1+ (0.2,0) [0|12851] "kg/h" Vector__XXX
 SG_ Aftrtrtmnt2SndrArPrssr : 48|16@1+ (0.1,0) [0|6425.5] "kPa" Vector__XXX
 SG_ Aftrtrtmnt2SndrArTmprtr : 16|16@1+ (0.03125,-273) [-273|1734.96875] "degC" Vector__XXX

BO_ 2566745598 AT1AC2: 8 Vector__XXX
 SG_ Aftrtrtmnt1SndrArDffrntlPrssr : 0|16@1+ (0.0078125,-250) [-250|251.99] "kPa" Vector__XXX
 SG_ Aftrtrtmnt1SndrArMssFlwRt : 32|16@1+ (0.2,0) [0|12851] "kg/h" Vector__XXX
 SG_ Aftrtrtmnt1SndrArPrssr : 48|16@1+ (0.1,0) [0|6425.5] "kPa" Vector__XXX
 SG_ Aftrtrtmnt1SndrArTmprtr : 16|16@1+ (0.03125,-273) [-273|1734.96875] "degC" Vector__XXX

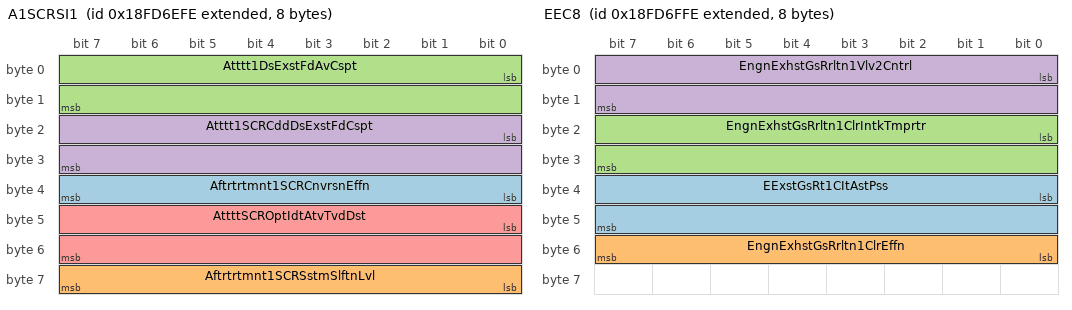
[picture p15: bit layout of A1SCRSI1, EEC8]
BO_ 2566745854 A1SCRSI1: 8 Vector__XXX
 SG_ Aftrtrtmnt1SCRCnvrsnEffn : 32|8@1+ (0.4,0) [0|100] "%" Vector__XXX
 SG_ Aftrtrtmnt1SCRSstmSlftnLvl : 56|8@1+ (1,0) [0|250] "%" Vector__XXX
 SG_ Atttt1DsExstFdAvCspt : 0|16@1+ (0.05,0) [0|3212.75] "l/h" Vector__XXX
 SG_ Atttt1SCRCddDsExstFdCspt : 16|16@1+ (0.05,0) [0|3212.75] "l/h" Vector__XXX
 SG_ AttttSCROptIdtAtvTvdDst : 40|16@1+ (1,0) [0|64255] "km" Vector__XXX

BO_ 2566746110 EEC8: 8 Vector__XXX
 SG_ EExstGsRt1CItAstPss : 32|16@1+ (0.5,0) [0|32127.5] "kPa" Vector__XXX
 SG_ EngnExhstGsRrltn1ClrEffn : 48|8@1+ (0.4,0) [0|100] "%" Vector__XXX
 SG_ EngnExhstGsRrltn1ClrIntkTmprtr : 16|16@1+ (0.03125,-273) [-273|1734.96875] "degC" Vector__XXX
 SG_ EngnExhstGsRrltn1Vlv2Cntrl : 0|16@1+ (0.0025,0) [0|160.6375] "%" Vector__XXX

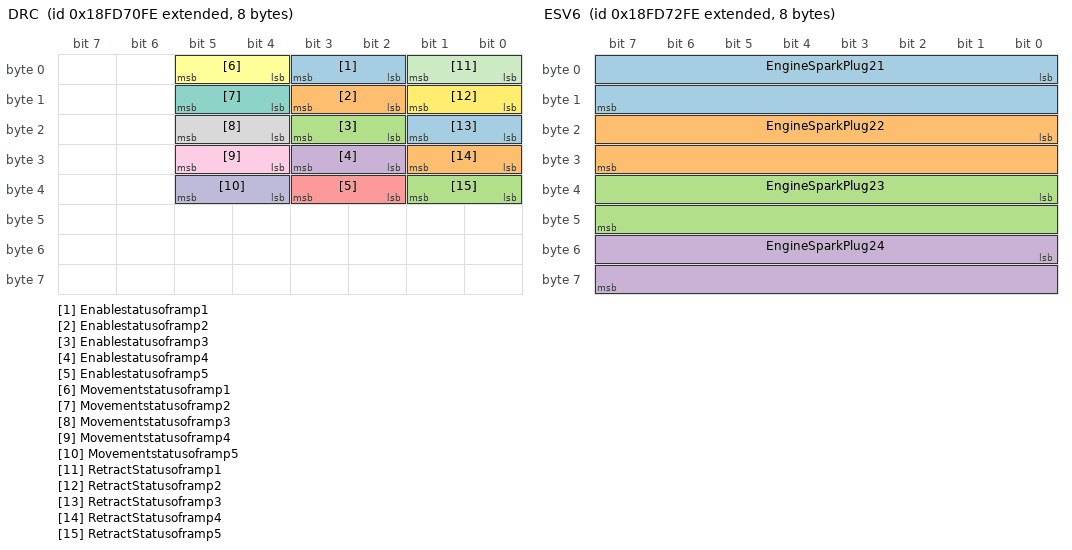
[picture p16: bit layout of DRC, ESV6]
BO_ 2566746366 DRC: 8 Vector__XXX
 SG_ Enablestatusoframp1 : 2|2@1+ (1,0) [0|3] "" Vector__XXX
 SG_ Enablestatusoframp2 : 10|2@1+ (1,0) [0|3] "" Vector__XXX
 SG_ Enablestatusoframp3 : 18|2@1+ (1,0) [0|3] "" Vector__XXX
 SG_ Enablestatusoframp4 : 26|2@1+ (1,0) [0|3] "" Vector__XXX
 SG_ Enablestatusoframp5 : 34|2@1+ (1,0) [0|3] "" Vector__XXX
 SG_ Movementstatusoframp1 : 4|2@1+ (1,0) [0|3] "" Vector__XXX
 SG_ Movementstatusoframp2 : 12|2@1+ (1,0) [0|3] "" Vector__XXX
 SG_ Movementstatusoframp3 : 20|2@1+ (1,0) [0|3] "" Vector__XXX
 SG_ Movementstatusoframp4 : 28|2@1+ (1,0) [0|3] "" Vector__XXX
 SG_ Movementstatusoframp5 : 36|2@1+ (1,0) [0|3] "" Vector__XXX
 SG_ RetractStatusoframp1 : 0|2@1+ (1,0) [0|3] "" Vector__XXX
 SG_ RetractStatusoframp2 : 8|2@1+ (1,0) [0|3] "" Vector__XXX
 SG_ RetractStatusoframp3 : 16|2@1+ (1,0) [0|3] "" Vector__XXX
 SG_ RetractStatusoframp4 : 24|2@1+ (1,0) [0|3] "" Vector__XXX
 SG_ RetractStatusoframp5 : 32|2@1+ (1,0) [0|3] "" Vector__XXX

BO_ 2566746622 BSA: 8 Vector__XXX
 SG_ TractorBrakeStrokeAxle1Left : 0|3@1+ (1,0) [0|7] "" Vector__XXX
 SG_ TractorBrakeStrokeAxle1Right : 3|3@1+ (1,0) [0|7] "" Vector__XXX
 SG_ TractorBrakeStrokeAxle2Left : 6|3@1+ (1,0) [0|7] "" Vector__XXX
 SG_ TractorBrakeStrokeAxle2Right : 9|3@1+ (1,0) [0|7] "" Vector__XXX
 SG_ TractorBrakeStrokeAxle3Left : 12|3@1+ (1,0) [0|7] "" Vector__XXX
 SG_ TractorBrakeStrokeAxle3Right : 15|3@1+ (1,0) [0|7] "" Vector__XXX
 SG_ TractorBrakeStrokeAxle4Left : 18|3@1+ (1,0) [0|7] "" Vector__XXX
 SG_ TractorBrakeStrokeAxle4Right : 21|3@1+ (1,0) [0|7] "" Vector__XXX
 SG_ TractorBrakeStrokeAxle5Left : 24|3@1+ (1,0) [0|7] "" Vector__XXX
 SG_ TractorBrakeStrokeAxle5Right : 27|3@1+ (1,0) [0|7] "" Vector__XXX
 SG_ TrailerBrakeStrokeAxle1Left : 30|3@1+ (1,0) [0|7] "" Vector__XXX
 SG_ TrailerBrakeStrokeAxle1Right : 33|3@1+ (1,0) [0|7] "" Vector__XXX
 SG_ TrailerBrakeStrokeAxle2Left : 36|3@1+ (1,0) [0|7] "" Vector__XXX
 SG_ TrailerBrakeStrokeAxle2Right : 39|3@1+ (1,0) [0|7] "" Vector__XXX
 SG_ TrailerBrakeStrokeAxle3Left : 42|3@1+ (1,0) [0|7] "" Vector__XXX
 SG_ TrailerBrakeStrokeAxle3Right : 45|3@1+ (1,0) [0|7] "" Vector__XXX
 SG_ TrailerBrakeStrokeAxle4Left : 48|3@1+ (1,0) [0|7] "" Vector__XXX
 SG_ TrailerBrakeStrokeAxle4Right : 51|3@1+ (1,0) [0|7] "" Vector__XXX
 SG_ TrailerBrakeStrokeAxle5Left : 54|3@1+ (1,0) [0|7] "" Vector__XXX
 SG_ TrailerBrakeStrokeAxle5Right : 57|3@1+ (1,0) [0|7] "" Vector__XXX

BO_ 2566746878 ESV6: 8 Vector__XXX
 SG_ EngineSparkPlug21 : 0|16@1+ (1,0) [0|64255] "V" Vector__XXX
 SG_ EngineSparkPlug22 : 16|16@1+ (1,0) [0|64255] "V" Vector__XXX
 SG_ EngineSparkPlug23 : 32|16@1+ (1,0) [0|64255] "V" Vector__XXX
 SG_ EngineSparkPlug24 : 48|16@1+ (1,0) [0|64255] "V" Vector__XXX

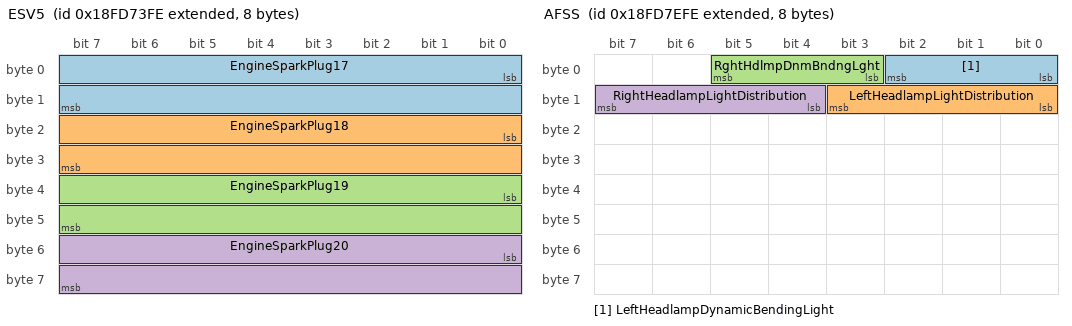
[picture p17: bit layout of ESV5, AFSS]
BO_ 2566747134 ESV5: 8 Vector__XXX
 SG_ EngineSparkPlug17 : 0|16@1+ (1,0) [0|64255] "V" Vector__XXX
 SG_ EngineSparkPlug18 : 16|16@1+ (1,0) [0|64255] "V" Vector__XXX
 SG_ EngineSparkPlug19 : 32|16@1+ (1,0) [0|64255] "V" Vector__XXX
 SG_ EngineSparkPlug20 : 48|16@1+ (1,0) [0|64255] "V" Vector__XXX

BO_ 2566747390 ESV4: 8 Vector__XXX
 SG_ EngineSparkPlug13 : 0|16@1+ (1,0) [0|64255] "V" Vector__XXX
 SG_ EngineSparkPlug14 : 16|16@1+ (1,0) [0|64255] "V" Vector__XXX
 SG_ EngineSparkPlug15 : 32|16@1+ (1,0) [0|64255] "V" Vector__XXX
 SG_ EngineSparkPlug16 : 48|16@1+ (1,0) [0|64255] "V" Vector__XXX

BO_ 2566747646 ESV3: 8 Vector__XXX
 SG_ EngineSparkPlug10 : 16|16@1+ (1,0) [0|64255] "V" Vector__XXX
 SG_ EngineSparkPlug11 : 32|16@1+ (1,0) [0|64255] "V" Vector__XXX
 SG_ EngineSparkPlug12 : 48|16@1+ (1,0) [0|64255] "V" Vector__XXX
 SG_ EngineSparkPlug9 : 0|16@1+ (1,0) [0|64255] "V" Vector__XXX

BO_ 2566747902 ESV2: 8 Vector__XXX
 SG_ EngineSparkPlug5 : 0|16@1+ (1,0) [0|64255] "V" Vector__XXX
 SG_ EngineSparkPlug6 : 16|16@1+ (1,0) [0|64255] "V" Vector__XXX
 SG_ EngineSparkPlug7 : 32|16@1+ (1,0) [0|64255] "V" Vector__XXX
 SG_ EngineSparkPlug8 : 48|16@1+ (1,0) [0|64255] "V" Vector__XXX

BO_ 2566748158 ESV1: 8 Vector__XXX
 SG_ EngineSparkPlug1 : 0|16@1+ (1,0) [0|64255] "V" Vector__XXX
 SG_ EngineSparkPlug2 : 16|16@1+ (1,0) [0|64255] "V" Vector__XXX
 SG_ EngineSparkPlug3 : 32|16@1+ (1,0) [0|64255] "V" Vector__XXX
 SG_ EngineSparkPlug4 : 48|16@1+ (1,0) [0|64255] "V" Vector__XXX

BO_ 2566748414 AT2TI: 32 Vector__XXX
 SG_ Aftrtrtmnt2DslPrtltFltrTrpFlUsd : 0|32@1+ (0.5,0) [0|2105540607.5] "l" Vector__XXX
 SG_ Atttt2DsPttFtTpAtvRtT : 32|32@1+ (1,0) [0|4211081215] "s" Vector__XXX
 SG_ Atttt2DsPttFtTpDsdT : 64|32@1+ (1,0) [0|4211081215] "s" Vector__XXX
 SG_ Atttt2DsPttFtTpNAtvRtItRqsts : 192|32@1+ (1,0) [0|4211081215] "count" Vector__XXX
 SG_ Atttt2DsPttFtTpNAtvRtMRqsts : 224|32@1+ (1,0) [0|4211081215] "count" Vector__XXX
 SG_ Atttt2DsPttFtTpNAtvRts : 96|32@1+ (1,0) [0|4211081215] "count" Vector__XXX
 SG_ Atttt2DsPttFtTpNPssvRts : 160|32@1+ (1,0) [0|4211081215] "count" Vector__XXX
 SG_ Atttt2DsPttFtTpPssvRtT : 128|32@1+ (1,0) [0|4211081215] "s" Vector__XXX

BO_ 2566748670 AT1TI: 32 Vector__XXX
 SG_ Aftrtrtmnt1DslPrtltFltrTrpFlUsd : 0|32@1+ (0.5,0) [0|2105540607.5] "l" Vector__XXX
 SG_ Atttt1DsPttFtTpAtvRtT : 32|32@1+ (1,0) [0|4211081215] "s" Vector__XXX
 SG_ Atttt1DsPttFtTpDsdT : 64|32@1+ (1,0) [0|4211081215] "s" Vector__XXX
 SG_ Atttt1DsPttFtTpNAtvRtItRqsts : 192|32@1+ (1,0) [0|4211081215] "count" Vector__XXX
 SG_ Atttt1DsPttFtTpNAtvRtMRqsts : 224|32@1+ (1,0) [0|4211081215] "count" Vector__XXX
 SG_ Atttt1DsPttFtTpNAtvRts : 96|32@1+ (1,0) [0|4211081215] "count" Vector__XXX
 SG_ Atttt1DsPttFtTpNPssvRts : 160|32@1+ (1,0) [0|4211081215] "count" Vector__XXX
 SG_ Atttt1DsPttFtTpPssvRtT : 128|32@1+ (1,0) [0|4211081215] "s" Vector__XXX

BO_ 2566748926 AT2S1: 8 Vector__XXX
 SG_ Aftrtrtmnt2DslPrtltFltrStLdPrnt : 0|8@1+ (1,0) [0|250] "%" Vector__XXX
 SG_ Atttt2DsPttFtAsLdPt : 8|8@1+ (1,0) [0|250] "%" Vector__XXX
 SG_ Atttt2DsPttFtStLdRtTsd : 48|16@1+ (0.0025,0) [0|160.6375] "%" Vector__XXX
 SG_ Atttt2DsPttFtTSLstAtvRt : 16|32@1+ (1,0) [0|4211081215] "s" Vector__XXX

BO_ 2566749182 AT1S1: 8 Vector__XXX
 SG_ Aftrtrtmnt1DslPrtltFltrStLdPrnt : 0|8@1+ (1,0) [0|250] "%" Vector__XXX
 SG_ Atttt1DsPttFtAsLdPt : 8|8@1+ (1,0) [0|250] "%" Vector__XXX
 SG_ Atttt1DsPttFtStLdRtTsd : 48|16@1+ (0.0025,0) [0|160.6375] "%" Vector__XXX
 SG_ Atttt1DsPttFtTSLstAtvRt : 16|32@1+ (1,0) [0|4211081215] "s" Vector__XXX

BO_ 2566749438 DPFC1: 8 Vector__XXX
 SG_ AftrtrtmntDslPrtltFltrStts : 12|3@1+ (1,0) [0|7] "" Vector__XXX
 SG_ Atttt1DsPttFtCdtsNtMtAtvRt : 60|2@1+ (1,0) [0|3] "" Vector__XXX
 SG_ AttttDsPttFtAtvRtStts : 10|2@1+ (1,0) [0|3] "" Vector__XXX
 SG_ AttttDsPttFtPssvRtStts : 8|2@1+ (1,0) [0|3] "" Vector__XXX
 SG_ DslPrtltFltrAtvRgnrtnAvlltStts : 3|2@1+ (1,0) [0|3] "" Vector__XXX
 SG_ DslPrtltFltrAtvRgnrtnFrdStts : 53|3@1+ (1,0) [0|7] "" Vector__XXX
 SG_ DslPrtltFltrAtvRgnrtnInhtdStts : 16|2@1+ (1,0) [0|3] "" Vector__XXX
 SG_ DslPrtltFltrLmpCmmnd : 0|3@1+ (1,0) [0|7] "" Vector__XXX
 SG_ DsPttFtAttAtvRtIttCt : 48|2@1+ (1,0) [0|3] "" Vector__XXX
 SG_ DsPttFtAtvRtItdDtAtPdOId : 26|2@1+ (1,0) [0|3] "" Vector__XXX
 SG_ DsPttFtAtvRtItdDtCtDsd : 20|2@1+ (1,0) [0|3] "" Vector__XXX
 SG_ DsPttFtAtvRtItdDtENtWdUp : 44|2@1+ (1,0) [0|3] "" Vector__XXX
 SG_ DsPttFtAtvRtItdDtItSwt : 18|2@1+ (1,0) [0|3] "" Vector__XXX
 SG_ DsPttFtAtvRtItdDtLwExstPss : 58|2@1+ (1,0) [0|3] "" Vector__XXX
 SG_ DsPttFtAtvRtItdDtLwExstTpt : 34|2@1+ (1,0) [0|3] "" Vector__XXX
 SG_ DsPttFtAtvRtItdDtOtNt : 28|2@1+ (1,0) [0|3] "" Vector__XXX
 SG_ DsPttFtAtvRtItdDtPBNtSt : 32|2@1+ (1,0) [0|3] "" Vector__XXX
 SG_ DsPttFtAtvRtItdDtPTOAtv : 24|2@1+ (1,0) [0|3] "" Vector__XXX
 SG_ DsPttFtAtvRtItdDtPtSstLt : 42|2@1+ (1,0) [0|3] "" Vector__XXX
 SG_ DsPttFtAtvRtItdDtSstFtAtv : 36|2@1+ (1,0) [0|3] "" Vector__XXX
 SG_ DsPttFtAtvRtItdDtSstTt : 38|2@1+ (1,0) [0|3] "" Vector__XXX
 SG_ DsPttFtAtvRtItdDtSvBAtv : 22|2@1+ (1,0) [0|3] "" Vector__XXX
 SG_ DsPttFtAtvRtItdDtTpSstLt : 40|2@1+ (1,0) [0|3] "" Vector__XXX
 SG_ DsPttFtAtvRtItdDtVSpdAvAwdSpd : 30|2@1+ (1,0) [0|3] "" Vector__XXX
 SG_ DsPttFtAtvRtItdDtVSpdBwAwdSpd : 46|2@1+ (1,0) [0|3] "" Vector__XXX
 SG_ ExhstSstmHghTmprtrLmpCmmnd : 50|3@1+ (1,0) [0|7] "" Vector__XXX
 SG_ HydrocarbonDoserPurgingEnable : 56|2@1+ (1,0) [0|3] "" Vector__XXX
 SG_ DsPttFtAtvRtItdDtTs : 62|2@1+ (1,0) [0|3] "" Vector__XXX

BO_ 2566749950 AFSS: 8 Vector__XXX
 SG_ LeftHeadlampDynamicBendingLight : 0|3@1+ (1,0) [0|7] "" Vector__XXX
 SG_ LeftHeadlampLightDistribution : 8|4@1+ (1,0) [0|15] "" Vector__XXX
 SG_ RghtHdlmpDnmBndngLght : 3|3@1+ (1,0) [0|7] "" Vector__XXX
 SG_ RightHeadlampLightDistribution : 12|4@1+ (1,0) [0|15] "" Vector__XXX

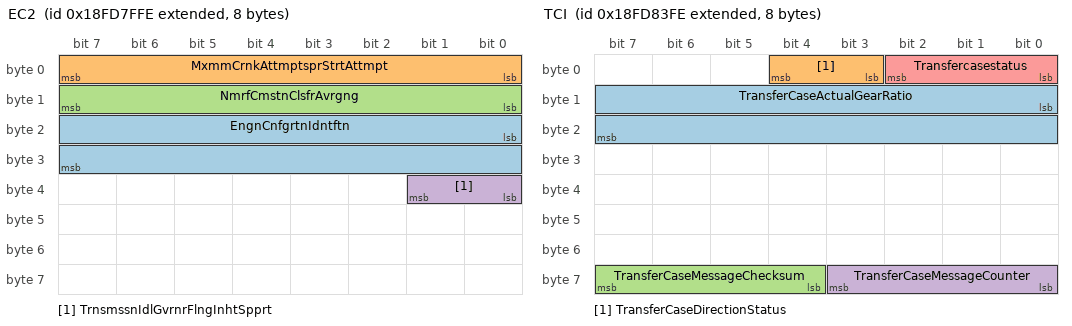
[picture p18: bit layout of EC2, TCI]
BO_ 2566750206 EC2: 8 Vector__XXX
 SG_ EngnCnfgrtnIdntftn : 16|16@1+ (1,0) [0|64255] "ID" Vector__XXX
 SG_ MxmmCrnkAttmptsprStrtAttmpt : 0|8@1+ (1,0) [0|250] "count" Vector__XXX
 SG_ NmrfCmstnClsfrAvrgng : 8|8@1+ (1,0) [0|250] "count" Vector__XXX
 SG_ TrnsmssnIdlGvrnrFlngInhtSpprt : 32|2@1+ (1,0) [0|3] "" Vector__XXX

BO_ 2566751230 TCI: 8 Vector__XXX
 SG_ TransferCaseActualGearRatio : 8|16@1+ (0.01,0) [0|642.55] "" Vector__XXX
 SG_ TransferCaseDirectionStatus : 3|2@1+ (1,0) [0|3] "" Vector__XXX
 SG_ TransferCaseMessageChecksum : 60|4@1+ (1,0) [0|15] "count" Vector__XXX
 SG_ TransferCaseMessageCounter : 56|4@1+ (1,0) [0|15] "count" Vector__XXX
 SG_ Transfercasestatus : 0|3@1+ (1,0) [0|7] "" Vector__XXX

BO_ 2566751486 EFLP9: 8 Vector__XXX
 SG_ EngnIntkVlvAttnOlPrssrfrClndr17 : 0|16@1+ (0.1,0) [0|6425.5] "kPa" Vector__XXX
 SG_ EngnIntkVlvAttnOlPrssrfrClndr18 : 16|16@1+ (0.1,0) [0|6425.5] "kPa" Vector__XXX
 SG_ EngnIntkVlvAttnOlPrssrfrClndr19 : 32|16@1+ (0.1,0) [0|6425.5] "kPa" Vector__XXX
 SG_ EngnIntkVlvAttnOlPrssrfrClndr20 : 48|16@1+ (0.1,0) [0|6425.5] "kPa" Vector__XXX

BO_ 2566751742 EFLP8: 8 Vector__XXX
 SG_ EngnIntkVlvAttnOlPrssrfrClndr13 : 0|16@1+ (0.1,0) [0|6425.5] "kPa" Vector__XXX
 SG_ EngnIntkVlvAttnOlPrssrfrClndr14 : 16|16@1+ (0.1,0) [0|6425.5] "kPa" Vector__XXX
 SG_ EngnIntkVlvAttnOlPrssrfrClndr15 : 32|16@1+ (0.1,0) [0|6425.5] "kPa" Vector__XXX
 SG_ EngnIntkVlvAttnOlPrssrfrClndr16 : 48|16@1+ (0.1,0) [0|6425.5] "kPa" Vector__XXX

BO_ 2566751998 EFLP7: 8 Vector__XXX
 SG_ EngnIntkVlvAttnOlPrssrfrClndr10 : 16|16@1+ (0.1,0) [0|6425.5] "kPa" Vector__XXX
 SG_ EngnIntkVlvAttnOlPrssrfrClndr11 : 32|16@1+ (0.1,0) [0|6425.5] "kPa" Vector__XXX
 SG_ EngnIntkVlvAttnOlPrssrfrClndr12 : 48|16@1+ (0.1,0) [0|6425.5] "kPa" Vector__XXX
 SG_ EngnIntkVlvAttnOlPrssrfrClndr9 : 0|16@1+ (0.1,0) [0|6425.5] "kPa" Vector__XXX

BO_ 2566752254 EFLP6: 8 Vector__XXX
 SG_ EngnIntkVlvAttnOlPrssrfrClndr5 : 0|16@1+ (0.1,0) [0|6425.5] "kPa" Vector__XXX
 SG_ EngnIntkVlvAttnOlPrssrfrClndr6 : 16|16@1+ (0.1,0) [0|6425.5] "kPa" Vector__XXX
 SG_ EngnIntkVlvAttnOlPrssrfrClndr7 : 32|16@1+ (0.1,0) [0|6425.5] "kPa" Vector__XXX
 SG_ EngnIntkVlvAttnOlPrssrfrClndr8 : 48|16@1+ (0.1,0) [0|6425.5] "kPa" Vector__XXX

BO_ 2566752510 EFLP5: 8 Vector__XXX
 SG_ EngnIntkVlvAttnOlPrssrfrClndr1 : 0|16@1+ (0.1,0) [0|6425.5] "kPa" Vector__XXX
 SG_ EngnIntkVlvAttnOlPrssrfrClndr2 : 16|16@1+ (0.1,0) [0|6425.5] "kPa" Vector__XXX
 SG_ EngnIntkVlvAttnOlPrssrfrClndr3 : 32|16@1+ (0.1,0) [0|6425.5] "kPa" Vector__XXX
 SG_ EngnIntkVlvAttnOlPrssrfrClndr4 : 48|16@1+ (0.1,0) [0|6425.5] "kPa" Vector__XXX

BO_ 2566752766 VDS2: 8 Vector__XXX
 SG_ VehicleRoll : 0|16@1+ (0.0078125,-200) [-200|301.99] "deg" Vector__XXX

BO_ 2566753278 AT2GP: 8 Vector__XXX
 SG_ Atttt2DsPttFtItPss : 0|16@1+ (0.1,0) [0|6425.5] "kPa" Vector__XXX
 SG_ Atttt2DsPttFtOttPss : 16|16@1+ (0.1,0) [0|6425.5] "kPa" Vector__XXX

BO_ 2566753534 AT1GP: 8 Vector__XXX
 SG_ Atttt1DsPttFtItPss : 0|16@1+ (0.1,0) [0|6425.5] "kPa" Vector__XXX
 SG_ Atttt1DsPttFtOttPss : 16|16@1+ (0.1,0) [0|6425.5] "kPa" Vector__XXX

BO_ 2566753790 UTACER: 8 Vector__XXX
 SG_ UtilityTotalkVArHoursExport : 0|32@1+ (1,0) [0|4211081215] "kVArh" Vector__XXX
 SG_ UtilityTotalkVArHoursImport : 32|32@1+ (1,0) [0|4211081215] "kVArh" Vector__XXX

BO_ 2566754046 GTACER: 8 Vector__XXX
 SG_ GeneratorTotalkVArHoursExport : 0|32@1+ (1,0) [0|4211081215] "kVArh" Vector__XXX
 SG_ GeneratorTotalkVArHoursImport : 32|32@1+ (1,0) [0|4211081215] "kVArh" Vector__XXX

BO_ 2566754302 GTACPP: 8 Vector__XXX
 SG_ GeneratorTotalPercentkVA : 16|16@1+ (0.0078125,-251) [-251|250.99] "%" Vector__XXX
 SG_ GeneratorTotalPercentkVAr : 32|16@1+ (0.0078125,-251) [-251|250.99] "%" Vector__XXX
 SG_ GeneratorTotalPercentkW : 0|16@1+ (0.0078125,-251) [-251|250.99] "%" Vector__XXX

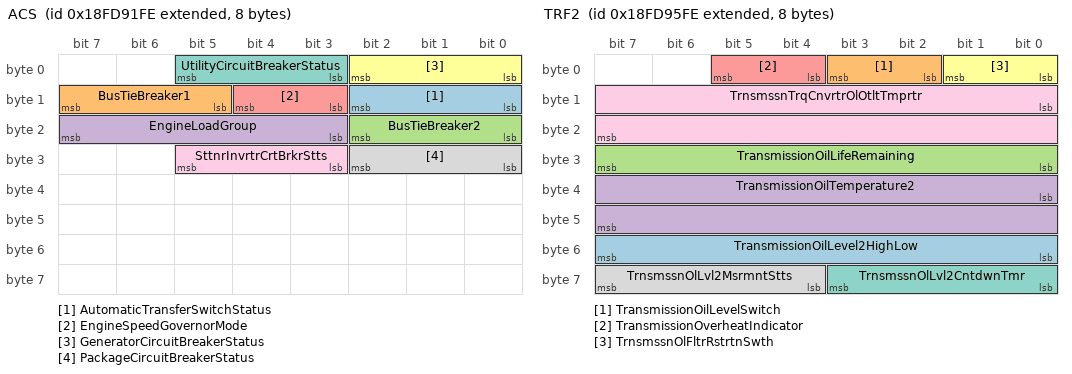
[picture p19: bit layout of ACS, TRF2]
BO_ 2566754814 ACS: 8 Vector__XXX
 SG_ AutomaticTransferSwitchStatus : 8|3@1+ (1,0) [0|7] "" Vector__XXX
 SG_ BusTieBreaker1 : 13|3@1+ (1,0) [0|7] "" Vector__XXX
 SG_ BusTieBreaker2 : 16|3@1+ (1,0) [0|7] "" Vector__XXX
 SG_ EngineLoadGroup : 19|5@1+ (1,0) [0|31] "count" Vector__XXX
 SG_ EngineSpeedGovernorMode : 11|2@1+ (1,0) [0|3] "" Vector__XXX
 SG_ GeneratorCircuitBreakerStatus : 0|3@1+ (1,0) [0|7] "" Vector__XXX
 SG_ UtilityCircuitBreakerStatus : 3|3@1+ (1,0) [0|7] "" Vector__XXX
 SG_ PackageCircuitBreakerStatus : 24|3@1+ (1,0) [0|7] "" Vector__XXX
 SG_ SttnrInvrtrCrtBrkrStts : 27|3@1+ (1,0) [0|7] "" Vector__XXX

BO_ 2566755582 EEC7: 8 Vector__XXX
 SG_ EngnCrnksBrthrOlSprtrSpd : 32|16@1+ (1,0) [0|64255] "rpm" Vector__XXX
 SG_ EngnExhstGsRrltn1Vlv2Pstn : 16|16@1+ (0.0025,0) [0|160.6375] "%" Vector__XXX
 SG_ EngnExhstGsRrltn1VlvPstn : 0|16@1+ (0.0025,0) [0|160.6375] "%" Vector__XXX
 SG_ EngnIntkMnfldCmmnddPrssr : 48|16@1+ (0.125,0) [0|8031.875] "kPa" Vector__XXX

BO_ 2566755838 TRF2: 8 Vector__XXX
 SG_ TransmissionOilLevel2HighLow : 48|8@1+ (0.5,-62.5) [-62.5|62.5] "l" Vector__XXX
 SG_ TransmissionOilLevelSwitch : 2|2@1+ (1,0) [0|3] "" Vector__XXX
 SG_ TransmissionOilLifeRemaining : 24|8@1+ (0.4,0) [0|100] "%" Vector__XXX
 SG_ TransmissionOilTemperature2 : 32|16@1+ (0.03125,-273) [-273|1734.96875] "degC" Vector__XXX
 SG_ TransmissionOverheatIndicator : 4|2@1+ (1,0) [0|3] "" Vector__XXX
 SG_ TrnsmssnOlFltrRstrtnSwth : 0|2@1+ (1,0) [0|3] "" Vector__XXX
 SG_ TrnsmssnOlLvl2CntdwnTmr : 56|4@1+ (1,0) [0|15] "" Vector__XXX
 SG_ TrnsmssnOlLvl2MsrmntStts : 60|4@1+ (1,0) [0|15] "" Vector__XXX
 SG_ TrnsmssnTrqCnvrtrOlOtltTmprtr : 8|16@1+ (0.03125,-273) [-273|1734.96875] "degC" Vector__XXX

BO_ 2566756094 LFI2: 8 Vector__XXX
 SG_ EngineFuelReturnFlowRate : 32|32@1+ (0.001,0) [0|4211081.215] "l/h" Vector__XXX
 SG_ EngineFuelSupplyFlowRate : 0|32@1+ (0.001,0) [0|4211081.215] "l/h" Vector__XXX

BO_ 2566756350 LFI3: 8 Vector__XXX
 SG_ EngineFuelReturnTemperature : 8|8@1+ (1,-40) [-40|210] "degC" Vector__XXX
 SG_ EngineFuelSupplyTemperature : 0|8@1+ (1,-40) [-40|210] "degC" Vector__XXX

CM_ BO_ 2566722302 "Magnet Status Information 1";
CM_ SG_ 2566722302 GeneratorOverheatStatus "Generator Overheat Status: The Status of Generator being Overheated.00b = Not Overheat01b = Overheat10b = Error11b = Not Available";
CM_ SG_ 2566722302 GensetEnableActiveStatus "Genset Enable Active Status: Status of the Genset Enable Relay that enables or disables the Genset.00b = Not Enabled01b = Enabled10b = Error11b = Not Avaialble";
CM_ SG_ 2566722302 GensetSoftstartActiveStatus "Genset Softstart Active Status: The Genset Softstart Active Status refers to the status of the genset softstart relay. The moment the Genset System is started, this relay is activated. As a result, the hydraulic power is hold on for a short period of...";
CM_ SG_ 2566722302 GnrtrDtClExddStts "Generator Duty Cycle Exceeded Status: The status of the duty cycle of the generator usage, indicating if the generator has been on for too much time within a defined time window.  The duty cycle is the ratio of the time the generator is on and the ti...";
CM_ SG_ 2566722302 GnstSstmOtptVltgRngStts "Genset System Output Voltage Range Status: Status of generator voltage in or out of desired operating range.00b = Out of Range 01b = In Range10b = Error11b = Not Available";
CM_ SG_ 2566722302 GrappleMagnetSelectionSwitch "Grapple/Magnet Selection Switch: This is a switch that can be used to select either the Grapple or Magnet function of the material handler machine.00b = Grapple Selected01b = Magnet Selected10b = Error11b = Not Available";
CM_ SG_ 2566722302 ReverseCurrentRangeSetting "Reverse Current Range Setting: The operator setting for the Reverse Current. The setting defines the maximum reverse current. The actual current limits are specific to the application.00000b = 100001b = 200010b = 300011b = 400100b = 500101b = 600110b...";
CM_ SG_ 2566722302 VoltageMonitorActiveStatus "Voltage Monitor Active Status: Status of Voltage Monitor Relay. When it is activated, the Generator Voltage Monitor is connected to the generator output line so that the generator output voltage range could be monitored.00b = Monitor is Off01b = Moni...";
CM_ BO_ 2566722558 "Magnet System Configuration Information";
CM_ SG_ 2566722558 MagnetBoostTime "Magnet Boost Time: The duration of time after the activation of the magnet circuit that a relatively high current is sent to the magnet for material pick up operations. This time is called boost time. After the boost time expires, a lower operation c...";
CM_ SG_ 2566722558 MagnetRatedPower "Magnet Rated Power: The rated power that the magnet can accept during material holding operations.  Note that the magnet may experience more power over short intervals, such as during initial activation of the magnet circuit to pick up material.";
CM_ BO_ 2566722814 "Battery Charger 2";
CM_ SG_ 2566722814 BatteryCharger2OutputCurrent "Battery Charger 2 Output Current: Output current of the battery charger connected to the main battery. If positive, this parameter shows the charging current of the battery charger connected to the main battery.  Otherwise, if the charger hardware pe...";
CM_ SG_ 2566722814 BatteryCharger2OutputVoltage "Battery Charger 2 Output Voltage: Output voltage measured on the battery terminals of the offline battery charger connected to the auxiliary battery.";
CM_ SG_ 2566722814 BatteryCharger2PowerLineState "Battery Charger 2 Power Line State: A state of the battery charger connection to the power line for the charger connected to the auxiliary battery.0 = Disconnected. The power line is disconnected from the charger.1 = Connected. The power line is conn...";
CM_ SG_ 2566722814 BatteryCharger2State "Battery Charger 2 State: A state of the offline battery charger connected to the auxiliary battery. 0 = Idling. The power line or the battery is disconnected from the charger.1 = Charging the battery.2 = Stand-by or maintaining the battery charge.3 t...";
CM_ BO_ 2566723070 "Battery Charger 1";
CM_ SG_ 2566723070 BatteryCharger1OutputCurrent "Battery Charger 1 Output Current: Output current of the battery charger connected to the main battery. If positive, this parameter shows the charging current of the battery charger connected to the main battery.  Otherwise, if the charger hardware pe...";
CM_ SG_ 2566723070 BatteryCharger1OutputVoltage "Battery Charger 1 Output Voltage: Output voltage measured on the battery terminals of the battery charger connected to the main battery.";
CM_ SG_ 2566723070 BatteryCharger1PowerLineState "Battery Charger 1 Power Line State: A state of the battery charger connection to the power line for the charger connected to the main battery.0 = Disconnected. The power line is disconnected from the charger.1 = Connected. The power line is connected...";
CM_ SG_ 2566723070 BatteryCharger1State "Battery Charger 1 State: A state of the battery charger connected to the main battery.  0 = Idling. The power line or the battery is disconnected from the charger.1 = Charging the battery.2 = Stand-by or maintaining the battery charge.3 to 12 = Reser...";
CM_ BO_ 2566724350 "Aftertreatment 1 Warm Up Diesel Oxidation Catalyst Information";
CM_ SG_ 2566724350 Atttt1WUpDsOxdtCtstItTpt "Aftertreatment 1 Warm Up Diesel Oxidation Catalyst Intake Temperature: This is the temperature measured at the intake of the warm up oxidation catalytic converter in exhaust bank 1.";
CM_ SG_ 2566724350 Atttt1WUpDsOxdtCtstOttTpt "Aftertreatment 1 Warm Up Diesel Oxidation Catalyst Outlet Temperature: This is the temperature measured at the outlet of the warm up oxidation catalytic converter in exhaust bank 1.";
CM_ BO_ 2566724606 "Diesel Particulate Filter 2 Soot";
CM_ SG_ 2566724606 Aftrtrtmnt2DslPrtltFltrMnStSgnl "Aftertreatment 2 Diesel Particulate Filter Mean Soot Signal: Mean output signal level from diesel particulate filter 2 soot sensor.";
CM_ SG_ 2566724606 Aftrtrtmnt2DslPrtltFltrStDnst "Aftertreatment 2 Diesel Particulate Filter Soot Density: Soot density in diesel particulate filter 2.";
CM_ SG_ 2566724606 Aftrtrtmnt2DslPrtltFltrStMss "Aftertreatment 2 Diesel Particulate Filter Soot Mass: Soot mass in diesel particulate filter 2.";
CM_ SG_ 2566724606 Atttt2DsPttFtMdStS "Aftertreatment 2 Diesel Particulate Filter Median Soot Signal: Median output signal level from diesel particulate filter 2 soot sensor.";
CM_ SG_ 2566724606 Atttt2DsPttFtStSsPFMI "Aftertreatment 2 Diesel Particulate Filter Soot Sensor Preliminary FMI: Used to identify the applicable J1939-73 FMI detected in the soot sensor signal by the manufacturer’s sensor control software in diesel particulate filter 2.  In the case of mult...";
CM_ SG_ 2566724606 DsPttFt2StSsECUItTpt "Diesel Particulate Filter 2 Soot Sensor ECU Internal Temperature: Internal temperature of the diesel particulate filter 2 soot sensor ECU.";
CM_ BO_ 2566724862 "Diesel Particulate Filter 1 Soot";
CM_ SG_ 2566724862 Aftrtrtmnt1DslPrtltFltrMnStSgnl "Aftertreatment 1 Diesel Particulate Filter Mean Soot Signal: Mean output signal level from diesel particulate filter 1 soot sensor.";
CM_ SG_ 2566724862 Aftrtrtmnt1DslPrtltFltrStDnst "Aftertreatment 1 Diesel Particulate Filter Soot Density: Soot density in diesel particulate filter 1.";
CM_ SG_ 2566724862 Aftrtrtmnt1DslPrtltFltrStMss "Aftertreatment 1 Diesel Particulate Filter Soot Mass: Soot mass in diesel particulate filter 1.";
CM_ SG_ 2566724862 Atttt1DsPttFtMdStS "Aftertreatment 1 Diesel Particulate Filter Median Soot Signal: Median output signal level from diesel particulate filter 1 soot sensor.";
CM_ SG_ 2566724862 Atttt1DsPttFtStSsPFMI "Aftertreatment 1 Diesel Particulate Filter Soot Sensor Preliminary FMI: Used to identify the applicable J1939-73 FMI detected in the soot sensor signal by the manufacturer’s sensor control software in diesel particulate filter 1. In the case of multi...";
CM_ SG_ 2566724862 DsPttFt1StSsECUItTpt "Diesel Particulate Filter 1 Soot Sensor ECU Internal Temperature: Internal temperature of the diesel particulate filter 1 soot sensor ECU.";
CM_ BO_ 2566725118 "Aftertreatment Differential Temperature 2 ";
CM_ SG_ 2566725118 Atttt1TWCtstDtTpt "Aftertreatment 1 Three Way Catalyst Differential Temperature: The differential engine combustion byproducts gas temperature measured between the intake and outlet of the three way catalyst for exhaust bank 1.";
CM_ SG_ 2566725118 Atttt2TWCtstDtTpt "Aftertreatment 2 Three Way Catalyst Differential Temperature: The differential engine combustion byproducts gas temperature measured between the intake and outlet of the three way catalyst for exhaust bank 2.";
CM_ BO_ 2566725374 "Aftertreatment Differential Temperature 1 ";
CM_ SG_ 2566725374 Atttt1GsOxdtCtstDtTpt "Aftertreatment 1 Gas Oxidation Catalyst Differential Temperature: The differential engine combustion byproducts gas temperature measured between the intake and outlet of the gas oxidation catalyst for exhaust bank 1.  This parameter should be used wi...";
CM_ SG_ 2566725374 Atttt2GsOxdtCtstDtTpt "Aftertreatment 2 Gas Oxidation Catalyst Differential Temperature: The differential engine combustion byproducts gas temperature measured between the intake and outlet of the gas oxidation catalyst for exhaust bank 2.  This parameter should be used wi...";
CM_ BO_ 2566725630 "Aftertreatment 2 Diesel Oxidation Catalyst 1";
CM_ SG_ 2566725630 Atttt2DsOxdtCtstDtPss "Aftertreatment 2 Diesel Oxidation Catalyst Differential Pressure: Exhaust differential pressure measured between the intake and exhaust of a diesel oxidation catalyst in exhaust bank 2.  This parameter should be used with engines fueled by diesel fue...";
CM_ SG_ 2566725630 Atttt2DsOxdtCtstDtPssPFMI "Aftertreatment 2 Diesel Oxidation Catalyst Differential Pressure Preliminary FMI: Used to identify the applicable J1939-73 FMI detected in the diesel oxidation catalyst differential pressure sensor by the manufacturer’s sensor control software in exh...";
CM_ SG_ 2566725630 Atttt2DsOxdtCtstItTpt "Aftertreatment 2 Diesel Oxidation Catalyst Intake Temperature: Temperature of engine combustion byproducts entering the diesel oxidation catalyst in exhaust bank 2.  This parameter should be used with engines fueled by diesel fuel (not gaseous fuel l...";
CM_ SG_ 2566725630 Atttt2DsOxdtCtstItTptPFMI "Aftertreatment 2 Diesel Oxidation Catalyst Intake Temperature Preliminary FMI: Used to identify the applicable J1939-73 FMI detected in the diesel oxidation catalyst intake temperature sensor by the manufacturer’s sensor control software in exhaust b...";
CM_ SG_ 2566725630 Atttt2DsOxdtCtstOttTpt "Aftertreatment 2 Diesel Oxidation Catalyst Outlet Temperature: Temperature of engine combustion byproducts leaving the diesel oxidation catalyst exhaust in exhaust bank 2.  This parameter should be used with engines fueled by diesel fuel (not gaseous...";
CM_ SG_ 2566725630 Atttt2DsOxdtCtstOttTptPFMI "Aftertreatment 2 Diesel Oxidation Catalyst Outlet Temperature Preliminary FMI: Used to identify the applicable J1939-73 FMI detected in the diesel oxidation catalyst outlet gas temperature sensor by the manufacturer’s sensor control software in exhau...";
CM_ BO_ 2566725886 "Aftertreatment 1 Diesel Oxidation Catalyst 1";
CM_ SG_ 2566725886 Atttt1DsOxdtCtstDtPss "Aftertreatment 1 Diesel Oxidation Catalyst Differential Pressure: Exhaust differential pressure measured between the intake and exhaust of a diesel oxidation catalyst in exhaust bank 1.  This parameter should be used with engines fueled by diesel fue...";
CM_ SG_ 2566725886 Atttt1DsOxdtCtstDtPssPFMI "Aftertreatment 1 Diesel Oxidation Catalyst Differential Pressure Preliminary FMI: Used to identify the applicable J1939-73 FMI detected in the diesel oxidation catalyst differential pressure sensor by the manufacturer’s sensor control software in exh...";
CM_ SG_ 2566725886 Atttt1DsOxdtCtstItTpt "Aftertreatment 1 Diesel Oxidation Catalyst Intake Temperature: Temperature of engine combustion byproducts entering the diesel oxidation catalyst in exhaust bank 1.  This parameter should be used with engines fueled by diesel fuel (not gaseous fuel l...";
CM_ SG_ 2566725886 Atttt1DsOxdtCtstItTptPFMI "Aftertreatment 1 Diesel Oxidation Catalyst Intake Temperature Preliminary FMI: Used to identify the applicable J1939-73 FMI detected in the diesel oxidation catalyst intake temperature sensor by the manufacturer’s sensor control software in exhaust b...";
CM_ SG_ 2566725886 Atttt1DsOxdtCtstOttTpt "Aftertreatment 1 Diesel Oxidation Catalyst Outlet Temperature: Temperature of engine combustion byproducts leaving the diesel oxidation catalyst exhaust in exhaust bank 1.  This parameter should be used with engines fueled by diesel fuel (not gaseous...";
CM_ SG_ 2566725886 Atttt1DsOxdtCtstOttTptPFMI "Aftertreatment 1 Diesel Oxidation Catalyst Outlet Temperature Preliminary FMI: Used to identify the applicable J1939-73 FMI detected in the diesel oxidation catalyst outlet gas temperature sensor by the manufacturer’s sensor control software in exhau...";
CM_ BO_ 2566726142 "Aftertreatment 2 Gas Oxidation Catalyst";
CM_ SG_ 2566726142 Atttt2GsOxdtCtstDtPss "Aftertreatment 2 Gas Oxidation Catalyst Differential Pressure: Exhaust differential pressure measured between the intake and exhaust of the gas oxidation catalyst in exhaust bank 2.  This parameter should be used with engines fueled by gaseous fuel l...";
CM_ SG_ 2566726142 Atttt2GsOxdtCtstDtPssPFMI "Aftertreatment 2 Gas Oxidation Catalyst Differential Pressure Preliminary FMI: Used to identify the applicable J1939-73 FMI detected in the gas oxidation catalyst differential pressure sensor by the manufacturer’s sensor control software in exhaust b...";
CM_ SG_ 2566726142 Atttt2GsOxdtCtstItTpt "Aftertreatment 2 Gas Oxidation Catalyst Intake Temperature: Temperature of engine combustion byproducts entering the gas oxidation catalyst in exhaust bank 2.  This parameter should be used with engines fueled by gaseous fuel like natural gas or prop...";
CM_ SG_ 2566726142 Atttt2GsOxdtCtstItTptPFMI "Aftertreatment 2 Gas Oxidation Catalyst Intake Temperature Preliminary FMI: Used to identify the applicable J1939-73 FMI detected in the gas oxidation catalyst intake gas temperature sensor by the manufacturer’s sensor control software in exhaust ban...";
CM_ SG_ 2566726142 Atttt2GsOxdtCtstOttTpt "Aftertreatment 2 Gas Oxidation Catalyst Outlet Temperature: Temperature of engine combustion byproducts leaving the gas oxidation catalyst in exhaust bank 2.  This parameter should be used with engines fueled by gaseous fuel like natural gas or propa...";
CM_ SG_ 2566726142 Atttt2GsOxdtCtstOttTptPFMI "Aftertreatment 2 Gas Oxidation Catalyst Outlet Temperature Preliminary FMI: Used to identify the applicable J1939-73 FMI detected in the gas oxidation catalyst outlet gas temperature sensor by the manufacturer’s sensor control software in exhaust ban...";
CM_ BO_ 2566726398 "Aftertreatment 1 Gas Oxidation Catalyst";
CM_ SG_ 2566726398 Atttt1GsOxdtCtstDtPss "Aftertreatment 1 Gas Oxidation Catalyst Differential Pressure: Exhaust differential pressure measured between the intake and exhaust of the gas oxidation catalyst in exhaust bank 1.  This parameter should be used with engines fueled by gaseous fuel l...";
CM_ SG_ 2566726398 Atttt1GsOxdtCtstDtPssPFMI "Aftertreatment 1 Gas Oxidation Catalyst Differential Pressure Preliminary FMI: Used to identify the applicable J1939-73 FMI detected in the gas oxidation catalyst differential pressure sensor by the manufacturer’s sensor control software in exhaust b...";
CM_ SG_ 2566726398 Atttt1GsOxdtCtstItTpt "Aftertreatment 1 Gas Oxidation Catalyst Intake Temperature: Temperature of engine combustion byproducts entering the gas oxidation catalyst in exhaust bank 1.  This parameter should be used with engines fueled by gaseous fuel like natural gas or prop...";
CM_ SG_ 2566726398 Atttt1GsOxdtCtstItTptPFMI "Aftertreatment 1 Gas Oxidation Catalyst Intake Temperature Preliminary FMI: Used to identify the applicable J1939-73 FMI detected in the gas oxidation catalyst intake temperature sensor by the manufacturer’s sensor control software in exhaust bank 1....";
CM_ SG_ 2566726398 Atttt1GsOxdtCtstOttTpt "Aftertreatment 1 Gas Oxidation Catalyst Outlet Temperature: Temperature of engine combustion byproducts leaving the gas oxidation catalyst in exhaust bank 1.  This parameter should be used with engines fueled by gaseous fuel like natural gas or propa...";
CM_ SG_ 2566726398 Atttt1GsOxdtCtstOttTptPFMI "Aftertreatment 1 Gas Oxidation Catalyst Outlet Temperature Preliminary FMI: Used to identify the applicable J1939-73 FMI detected in the gas oxidation catalyst outlet temperature sensor by the manufacturer’s sensor control software in exhaust bank 1....";
CM_ BO_ 2566730238 "Fan Drive #2";
CM_ SG_ 2566730238 EstimatedPercentFan2Speed "Estimated Percent Fan 2 Speed: Estimated fan speed as a ratio of the fan drive (current speed) to the fully engaged fan drive (maximum fan speed).  A two state fan (off/on) will use 0% and 100% respectively.  A three state fan (off/intermediate/on) w...";
CM_ SG_ 2566730238 Fan2DriveBypassCommandStatus "Fan 2 Drive Bypass Command Status: Status of the Fan Drive Bypass Command for the second fan as being commanded by the ECU.  The fan drive bypass diverts pump pressure away from the hydraulic motor to maintain the fan drive pressure.  0% is defined a...";
CM_ SG_ 2566730238 Fan2DriveState "Fan 2 Drive State: This parameter is used to indicate the current state or mode of operation by the second fan drive.0000b = Fan off0001b = Engine system–General0010b = Excessive engine air temperature0011b = Excessive engine oil temperature0100b = E...";
CM_ SG_ 2566730238 Fan2Speed "Fan 2 Speed: The speed of the second fan associated with engine coolant system.";
CM_ SG_ 2566730238 HydraulicFan2MotorPressure "Hydraulic Fan 2 Motor Pressure: The hydraulic pressure used to drive the second fan system, sensed before the hydraulic fan motor.";
CM_ BO_ 2566730750 "Aftertreatment 2 Diesel Exhaust Fluid Supply Information";
CM_ SG_ 2566730750 Aftrtrtmnt2DslExhstFldPmp "Aftertreatment 2 Diesel Exhaust Fluid Pump: State of the Aftertreatment 2 Diesel Exhaust Fluid dosing pump.  Indicates if the pump is currently active (pumping).  00b = Off01b = On10b = Error11b = Not availableThe Aftertreatment 2 Diesel Exhaust Flui...";
CM_ SG_ 2566730750 Aftrtrtmnt2DslExhstFldPmpPwrRl "Aftertreatment 2 Diesel Exhaust Fluid Pump Power Relay: The state of the aftertreatment 2 diesel exhaust fluid pump power relay.00b = Not active - No power is being applied to the relay01b = Active - Power is being applied to the relay10b = Error11b ...";
CM_ SG_ 2566730750 Aftrtrtmnt2DslExhstFldPmpStt "Aftertreatment 2 Diesel Exhaust Fluid Pump State: State of Aftertreatment 2 Diesel Exhaust Fluid dosing pump.00b = pump operational01b = pump error10b = reserved for SAE assignment11b = not available";
CM_ SG_ 2566730750 Atttt2DsExstFdDsUt1DvtVv "Aftertreatment 2 Diesel Exhaust Fluid Dosing Unit 1 Diverter Valve: Command to the valve which determines whether the diesel exhaust fluid of dosing unit 1 is delivered to the injector or is routed back to the diesel exhaust fluid tank. Zero directs ...";
CM_ SG_ 2566730750 Atttt2DsExstFdDsUt2DvtVv "Aftertreatment 2 Diesel Exhaust Fluid Dosing Unit 2 Diverter Valve: Command to the valve which determines whether the diesel exhaust fluid of dosing unit 2 is delivered to the injector or is routed back to the diesel exhaust fluid tank. Zero directs ...";
CM_ SG_ 2566730750 Atttt2DsExstFdPp1MtSpd "Aftertreatment 2 Diesel Exhaust Fluid Pump 1 Motor Speed: Rotational speed of the motor driving the first or only pump for the diesel exhaust fluid used in aftertreatment system 2 (exhaust bank 2).";
CM_ SG_ 2566730750 Atttt2DsExstFdPpDvPt "Aftertreatment 2 Diesel Exhaust Fluid Pump Drive Percentage: The percent (command) sent to the motor to control the speed of  the diesel exhaust fluid pump.";
CM_ SG_ 2566730750 Atttt2DsExstFdTDVvCd "Aftertreatment 2 Diesel Exhaust Fluid Tank Drain Valve Command: Commanded percentage of maximum Aftertreatment 2 Diesel Exhaust Fluid Tank Drain Valve opening. 100% means the the drain valve is fully open providing maximum flow of diesel exhaust flui...";
CM_ SG_ 2566730750 Atttt2DsExstFdTFVvCd "Aftertreatment 2 Diesel Exhaust Fluid Tank Fill Valve Command: Commanded percentage of maximum Aftertreatment 2 Diesel Exhaust Fluid Tank Fill Valve opening. 100% means the fill valve is fully open providing maximum flow of diesel exhaust fluid into ...";
CM_ BO_ 2566731006 "Aftertreatment 2 SCR Reagant Tank 2 Information";
CM_ SG_ 2566731006 Aftrtrtmnt2DslExhstFldQkThwHtr "Aftertreatment 2 Diesel Exhaust Fluid Quick Thaw Heater: The diesel exhaust fluid quick thaw tank heater percentage for aftertreatment system 2 (exhaust bank 2). 0% is off. See SPN 5415 for the command for this tank heater.";
CM_ SG_ 2566731006 Atttt2DsExstFdQTwHtPFMI "Aftertreatment 2 Diesel Exhaust Fluid Quick Thaw Heater Preliminary FMI: Used to identify the applicable J1939-73 FMI detected for the heater of the diesel exhaust fluid quick thaw tank for aftertreatment system 2 (exhaust bank 2), as detected by the...";
CM_ SG_ 2566731006 Atttt2DsExstFdQTwLvPFMI "Aftertreatment 2 Diesel Exhaust Fluid Quick Thaw Level Preliminary FMI: Used to identify the applicable J1939-73 FMI detected for the fluid level height of the diesel exhaust fluid quick thaw tank for aftertreatment system 2 (exhaust bank 2), as dete...";
CM_ SG_ 2566731006 Atttt2DsExstFdQTwTLv "Aftertreatment 2 Diesel Exhaust Fluid Quick Thaw Tank Level: The diesel exhaust fluid level height in mm in the diesel exhaust fluid quick thaw tank for aftertreatment system 2 (exhaust bank 2).  See SPN 4433 for alternate measurement. Parameter Spec...";
CM_ SG_ 2566731006 Atttt2DsExstFdQTwTptPFMI "Aftertreatment 2 Diesel Exhaust Fluid Quick Thaw Temperature Preliminary FMI: Used to identify the applicable J1939-73 FMI detected for the diesel exhaust fluid quick thaw tank temperature for aftertreatment system 2 (exhaust bank 2), as detected by ...";
CM_ SG_ 2566731006 Atttt2DsExstFdQTwTV "Aftertreatment 2 Diesel Exhaust Fluid Quick Thaw Tank Volume: Ratio of volume of diesel exhaust fluid to the total volume of diesel exhaust fluid storage container for aftertreatment system 2 (exhaust bank 2).  0% is empty and 100% is full.  An alter...";
CM_ SG_ 2566731006 Atttt2DsExstFdQTwTTpt "Aftertreatment 2 Diesel Exhaust Fluid Quick Thaw Tank Temperature: The diesel exhaust fluid quick thaw tank temperature for aftertreatment system 2 (exhaust bank 2).";
CM_ BO_ 2566731262 "Aftertreatment 2 Diesel Exhaust Fluid Tank 1 Information 1";
CM_ SG_ 2566731262 Aftrtrtmnt2DslExhstFldTnkHtr "Aftertreatment 2 Diesel Exhaust Fluid Tank Heater: Percentage of heating applied to the aftertreatment 2 diesel exhaust fluid tank heater.  A value of 0% means no heating applied, a value of 100% means full heating applied.  The diesel exhaust fluid ...";
CM_ SG_ 2566731262 Aftrtrtmnt2DslExhstFldTnkLvl "Aftertreatment 2 Diesel Exhaust Fluid Tank Level: The diesel exhaust fluid level height in mm in the diesel exhaust fluid storage container for aftertreatment system 2 (exhaust bank 2).  See SPN 4426 and SPN 7531 for alternate measurements. Parameter...";
CM_ SG_ 2566731262 Aftrtrtmnt2DslExhstFldTnkVlm "Aftertreatment 2 Diesel Exhaust Fluid Tank Volume: Ratio of volume of diesel exhaust fluid to the total volume of the diesel exhaust fluid storage container for aftertreatment system 2 (exhaust bank 2).  0% is empty and 100% is full.  See SPN 4428 an...";
CM_ SG_ 2566731262 Atttt2DsExstFdT1HtPFMI "Aftertreatment 2 Diesel Exhaust Fluid Tank 1 Heater Preliminary FMI: Used to identify the applicable J1939-73 FMI detected for the heater of the diesel exhaust fluid tank for aftertreatment system 2 (exhaust bank 2), as detected by the manufacturer's...";
CM_ SG_ 2566731262 Atttt2DsExstFdT1TptPFMI "Aftertreatment 2 Diesel Exhaust Fluid Tank 1 Temperature Preliminary FMI: Used to identify the applicable J1939-73 FMI detected for the diesel exhaust fluid tank temperature for aftertreatment system 2 (exhaust bank 2), as detected by the manufacture...";
CM_ SG_ 2566731262 Atttt2DsExstFdTLvVPFMI "Aftertreatment 2 Diesel Exhaust Fluid Tank Level/Volume Preliminary FMI: Used to identify the applicable J1939-73 FMI detected in the diesel exhaust fluid tank level sensor by the manufacturer's sensor control software.  This FMI is applicable to eit...";
CM_ SG_ 2566731262 Atttt2DsExstFdTTpt1 "Aftertreatment 2 Diesel Exhaust Fluid Tank Temperature 1: Temperature of the diesel exhaust fluid in the storage tank.";
CM_ BO_ 2566731518 "Aftertreatment 2 Diesel Exhaust Fluid Information 1";
CM_ SG_ 2566731518 Aftrtrtmnt2DslExhstFldCndtvt "Aftertreatment 2 Diesel Exhaust Fluid Conductivity: A measure of the conductivity of the diesel exhaust fluid at the sensor.  The conductivity is an indication of the diesel exhaust fluid's chemical make up.";
CM_ SG_ 2566731518 Aftrtrtmnt2DslExhstFldCnntrtn "Aftertreatment 2 Diesel Exhaust Fluid Concentration: A measure of the concentration of urea in water.  Zero percent means that the tank contains no urea.  A 32.5% value indicates that the reagent is of the proper concentration.  The 32.5% value indic...";
CM_ SG_ 2566731518 Aftrtrtmnt2DslExhstFldTmprtr2 "Aftertreatment 2 Diesel Exhaust Fluid Temperature 2: Temperature of the diesel exhaust fluid at the device measuring diesel exhaust fluid quality";
CM_ SG_ 2566731518 Aftrtrtmnt2DslExhstFldTpPrprt "Aftertreatment 2 Diesel Exhaust Fluid Type Property: This parameter indicates the property of the fluid compound in the tank.  A value of 0011b indicates uncontaminated Diesel Exhaust Fluid.0000b = Urea concentration too high0001b = Urea concentratio...";
CM_ SG_ 2566731518 Atttt2DsExstFdPptsPFMI "Aftertreatment 2 Diesel Exhaust Fluid Properties Preliminary FMI: Used to identify the applicable J1939-73 FMI that applies to the most significant failure of the diesel exhaust fluid properties sensor.  This may be used for indicating failures of th...";
CM_ SG_ 2566731518 Atttt2DsExstFdTpt2PFMI "Aftertreatment 2 Diesel Exhaust Fluid Temperature 2 Preliminary FMI: Used to identify the applicable J1939-73 FMI that applies to the most significant failure of the diesel exhaust fluid temperature sensor. In the case of multiple failures the most s...";
CM_ BO_ 2566731774 "Aftertreatment 2 SCR Service Information 1";
CM_ SG_ 2566731774 Aftrtrtmnt2SCRCnvrsnEffn "Aftertreatment 2 SCR Conversion Efficiency: The SCR conversion efficiency percentage.  Calculated as 100 times the catalyst intake NOx minus the catalyst outlet NOx divided by the catalyst intake NOx.  The catalyst conversion efficiency number in its...";
CM_ SG_ 2566731774 Aftrtrtmnt2SCRSstmSlftnLvl "Aftertreatment 2 SCR System Sulfation Level: Indicates the sulfur level in the SCR system for aftertreatment 2.100% level could be the regeneration trigger level (and if conditions are not favorable for regeneration, sulfation loading can continue be...";
CM_ SG_ 2566731774 Atttt2DsExstFdAvCspt "Aftertreatment 2 Diesel Exhaust Fluid Average Consumption: Measured use of diesel exhaust fluid by a Selective Catalytic Reduction system for exhaust emission control, averaged over the previous 15 hours of engine operation.Used to determine whether ...";
CM_ SG_ 2566731774 Atttt2SCRCddDsExstFdCspt "Aftertreatment 2 SCR Commanded Diesel Exhaust Fluid Consumption: This parameter transmits the amount of diesel exhaust fluid that the emissions control system has requested to be used, averaged over the past 15 hours of engine operation.Used to deter...";
CM_ BO_ 2566732030 "Aftertreatment 2 SCR Exhaust Gas Temperature 1";
CM_ SG_ 2566732030 Aftrtrtmnt2SCRIntkTmprtr "Aftertreatment 2 SCR Intake Temperature: Temperature of engine combustion byproducts entering the SCR in exhaust bank 2.";
CM_ SG_ 2566732030 Aftrtrtmnt2SCROtltTmprtr "Aftertreatment 2 SCR Outlet Temperature: Temperature of engine combustion byproducts leaving the SCR exhaust in exhaust bank 2.";
CM_ SG_ 2566732030 Atttt2SCRItTptPFMI "Aftertreatment 2 SCR Intake Temperature Preliminary FMI: Used to identify the applicable J1939-73 FMI detected in the SCR intake temperature sensor by the manufacturer’s sensor control software in exhaust bank 2. In the case of multiple failures the ...";
CM_ SG_ 2566732030 Atttt2SCROttTptPFMI "Aftertreatment 2 SCR Outlet Temperature Preliminary FMI: Used to identify the applicable J1939-73 FMI detected in the SCR outlet temperature sensor by the manufacturer’s sensor control software in exhaust bank 2.  In the case of multiple failures the...";
CM_ BO_ 2566732286 "Aftertreatment 2 SCR Exhaust Gas Pressures";
CM_ SG_ 2566732286 Aftrtrtmnt2SCRDffrntlPrssr "Aftertreatment 2 SCR Differential Pressure: Differential pressure measured between the intake and exhaust of an SCR component in exhaust bank 2.";
CM_ SG_ 2566732286 Aftrtrtmnt2SCRIntkAsltPrssr "Aftertreatment 2 SCR Intake Absolute Pressure: Used to read the pressure at the catalyst intake of the selective catalytic reduction system of aftertreatment 2.";
CM_ SG_ 2566732286 Aftrtrtmnt2SCRIntkPrssr "Aftertreatment 2 SCR Intake Pressure: The gage pressure at the intake of the selective catalytic reduction system of Aftertreatment 2.";
CM_ SG_ 2566732286 Atttt2SCRDtPssPFMI "Aftertreatment 2 SCR Differential Pressure Preliminary FMI: Used to identify the applicable J1939-73 FMI detected in the SCR differential pressure sensor by the manufacturer’s sensor control software in exhaust bank 2. In the case of multiple failure...";
CM_ BO_ 2566732542 "Aftertreatment 2 SCR Dosing System Requests 2";
CM_ SG_ 2566732542 Aftrtrtmnt2DslExhstFldLnHtr1 "Aftertreatment 2 Diesel Exhaust Fluid Line Heater 1: The diesel exhaust fluid line heater 1 request for aftertreatment system 2 (exhaust bank 2). 00b = request for heater to be inactive 01b = request for heater to be active 10b = reserved for future ...";
CM_ SG_ 2566732542 Aftrtrtmnt2DslExhstFldLnHtr10 "Aftertreatment 2 Diesel Exhaust Fluid Line Heater 10: The diesel exhaust fluid line heater 10 request for aftertreatment system 2 (exhaust bank 2).00b = request for heater to be inactive01b = request for heater to be active10b = reserved for future a...";
CM_ SG_ 2566732542 Aftrtrtmnt2DslExhstFldLnHtr2 "Aftertreatment 2 Diesel Exhaust Fluid Line Heater 2: The diesel exhaust fluid line heater 2 request for aftertreatment system 2 (exhaust bank 2). 00b = request for heater to be inactive 01b = request for heater to be active 10b = reserved for future ...";
CM_ SG_ 2566732542 Aftrtrtmnt2DslExhstFldLnHtr3 "Aftertreatment 2 Diesel Exhaust Fluid Line Heater 3: The diesel exhaust fluid line heater 3 request for aftertreatment system 2 (exhaust bank 2). 00b = request for heater to be inactive 01b = request for heater to be active 10b = reserved for future ...";
CM_ SG_ 2566732542 Aftrtrtmnt2DslExhstFldLnHtr4 "Aftertreatment 2 Diesel Exhaust Fluid Line Heater 4: The diesel exhaust fluid line heater 4 request for aftertreatment system 2 (exhaust bank 2). 00b = request for heater to be inactive 01b = request for heater to be active 10b = reserved for future ...";
CM_ SG_ 2566732542 Aftrtrtmnt2DslExhstFldLnHtr5 "Aftertreatment 2 Diesel Exhaust Fluid Line Heater 5: Identifies the diesel exhaust fluid line heater 5 request for aftertreatment system 2 (exhaust bank 2).00b = request for heater to be inactive 01b = request for heater to be active 10b = reserved f...";
CM_ SG_ 2566732542 Aftrtrtmnt2DslExhstFldLnHtr6 "Aftertreatment 2 Diesel Exhaust Fluid Line Heater 6: The diesel exhaust fluid line heater 6 request for aftertreatment system 2 (exhaust bank 2).00b = request for heater to be inactive01b = request for heater to be active10b = reserved for future ass...";
CM_ SG_ 2566732542 Aftrtrtmnt2DslExhstFldLnHtr7 "Aftertreatment 2 Diesel Exhaust Fluid Line Heater 7: The diesel exhaust fluid line heater 7 request for aftertreatment system 2 (exhaust bank 2).00b = request for heater to be inactive01b = request for heater to be active10b = reserved for future ass...";
CM_ SG_ 2566732542 Aftrtrtmnt2DslExhstFldLnHtr8 "Aftertreatment 2 Diesel Exhaust Fluid Line Heater 8: The diesel exhaust fluid line heater 8 request for aftertreatment system 2 (exhaust bank 2).00b = request for heater to be inactive01b = request for heater to be active10b = reserved for future ass...";
CM_ SG_ 2566732542 Aftrtrtmnt2DslExhstFldLnHtr9 "Aftertreatment 2 Diesel Exhaust Fluid Line Heater 9: The diesel exhaust fluid line heater 9 request for aftertreatment system 2 (exhaust bank 2).00b = request for heater to be inactive01b = request for heater to be active10b = reserved for future ass...";
CM_ SG_ 2566732542 Aftrtrtmnt2DslExhstFldLnHtrRl1 "Aftertreatment 2 Diesel Exhaust Fluid Line Heater Relay 1: The aftertreatment system 2 diesel exhaust fluid line heater relay 1 is used to energize one or more DEF line heaters.00b = Off01b = On10b = Error11b = Not available";
CM_ SG_ 2566732542 Aftrtrtmnt2DslExhstFldLnHtrRl2 "Aftertreatment 2 Diesel Exhaust Fluid Line Heater Relay 2: The aftertreatment system 2 diesel exhaust fluid line heater relay 2 is used to energize one or more DEF line heaters.00b = Off01b = On10b = Error11b = Not available";
CM_ SG_ 2566732542 Aftrtrtmnt2DslExhstFldLnHtrRl3 "Aftertreatment 2 Diesel Exhaust Fluid Line Heater Relay 3: The aftertreatment system 2 diesel exhaust fluid line heater relay 3 is used to energize one or more DEF line heaters.00b = Off01b = On10b = Error11b = Not available";
CM_ SG_ 2566732542 Atttt2DsExstFdDsFtSppssRqst "Aftertreatment 2 Diesel Exhaust Fluid  Doser Fault Suppression Request: Used if external devices can warn of conditions that require suppression of potential faults in the doser due to environmental conditions.00b = Error suppression off01b = Error s...";
CM_ SG_ 2566732542 Atttt2DsExstFdDsHtMdRqst "Aftertreatment 2 Diesel Exhaust Fluid Doser Heating Mode Request: Used if multiple heater modes are available in the Doser.000b = Heater off001b = Heater economy mode010b = Heater automatic mode011b = Heater on100b to 110b = Reserved111b = Not availa...";
CM_ SG_ 2566732542 Atttt2DsExstFdQTwHtCd "Aftertreatment 2 Diesel Exhaust Fluid Quick Thaw Heater Command: The command for the heater of the diesel exhaust fluid quick thaw tank for aftertreatment system 2 (exhaust bank 2).  See SPN 4438 for the measured heater percentage for the heater of t...";
CM_ SG_ 2566732542 Atttt2DsExstFdTHtCd "Aftertreatment 2 Diesel Exhaust Fluid Tank Heater Command: Command for the Aftertreatment 2 Diesel Exhaust Fluid Tank Heater.  A value of 0% means no heating applied, a value of 100% means full heating applied.  See SPN 4431 for the measured value of...";
CM_ BO_ 2566732798 "Aftertreatment 2 SCR Dosing System Information 2";
CM_ SG_ 2566732798 Aftrtrtmnt2DslExhstFldLnHtr1Stt "Aftertreatment 2 Diesel Exhaust Fluid Line Heater 1 State: The diesel exhaust fluid line heater 1 state for aftertreatment system 2 (exhaust bank 2).00b = heater inactive 01b = heater active 10b = error 11b = not available";
CM_ SG_ 2566732798 Aftrtrtmnt2DslExhstFldLnHtr2Stt "Aftertreatment 2 Diesel Exhaust Fluid Line Heater 2 State: The diesel exhaust fluid line heater 2 state for aftertreatment system 2 (exhaust bank 2).00b = heater inactive 01b = heater active 10b = error 11b = not available";
CM_ SG_ 2566732798 Aftrtrtmnt2DslExhstFldLnHtr3Stt "Aftertreatment 2 Diesel Exhaust Fluid Line Heater 3 State: The diesel exhaust fluid line heater 3 state for aftertreatment system 2 (exhaust bank 2).00b = heater inactive 01b = heater active 10b = error 11b = not available";
CM_ SG_ 2566732798 Aftrtrtmnt2DslExhstFldLnHtr4Stt "Aftertreatment 2 Diesel Exhaust Fluid Line Heater 4 State: The diesel exhaust fluid line heater 4 state for aftertreatment system 2 (exhaust bank 2).00b = heater inactive 01b = heater active 10b = error 11b = not available";
CM_ SG_ 2566732798 Aftrtrtmnt2SCRDsngArAssstVlv "Aftertreatment 2 SCR Dosing Air Assist Valve: The position of the valve used to regulate the air supply of an air assist SCR dosing system for an engine. 0% represents no supply and 100% is full supply.";
CM_ SG_ 2566732798 Aftrtrtmnt2SCRFdkCntrlStts "Aftertreatment 2 SCR Feedback Control Status: The SCR feedback control status (open/closed loop) for aftertreatment system 2 (exhaust bank 2).000b = open loop control active 001b = closed loop control active 010b = reserved for future assignment by S...";
CM_ SG_ 2566732798 Atttt2DsExstFdDs1Tpt "Aftertreatment 2 Diesel Exhaust Fluid Doser 1 Temperature: The temperature (measured closest to dosing valve) of the first or only DEF doser for aftertreatment system 2 (exhaust bank 2).";
CM_ SG_ 2566732798 Atttt2DsExstFdLHt1PFMI "Aftertreatment 2 Diesel Exhaust Fluid Line Heater 1 Preliminary FMI: Used to identify the applicable J1939-73 FMI detected in the diesel exhaust fluid line heater 1, by the manufacturer’s control software in exhaust bank 2.  In the case of multiple f...";
CM_ SG_ 2566732798 Atttt2DsExstFdLHt2PFMI "Aftertreatment 2 Diesel Exhaust Fluid Line Heater 2 Preliminary FMI: Used to identify the applicable J1939-73 FMI detected in the diesel exhaust fluid line heater 2, by the manufacturer’s control software in exhaust bank 2.  In the case of multiple f...";
CM_ SG_ 2566732798 Atttt2DsExstFdLHt3PFMI "Aftertreatment 2 Diesel Exhaust Fluid Line Heater 3 Preliminary FMI: Used to identify the applicable J1939-73 FMI detected in the diesel exhaust fluid line heater 3, by the manufacturer’s control software in exhaust bank 2.  In the case of multiple f...";
CM_ SG_ 2566732798 Atttt2DsExstFdLHt4PFMI "Aftertreatment 2 Diesel Exhaust Fluid Line Heater 4 Preliminary FMI: Used to identify the applicable J1939-73 FMI detected in the diesel exhaust fluid line heater 4, by the manufacturer’s control software in exhaust bank 2.  In the case of multiple f...";
CM_ SG_ 2566732798 Atttt2SCRDsAAssstAstPss "Aftertreatment 2 SCR Dosing Air Assist Absolute Pressure: The SCR dosing system air assist absolute pressure for aftertreatment system 2 (exhaust bank 2).  The air assist system is used to improve the dosed reagent atomization.";
CM_ SG_ 2566732798 Atttt2SCRDsVvExstTptRdtRqst "Aftertreatment 2 SCR Doser Valve Exhaust Temperature Reduction Request: Protection request for the doser valve of the SCR system to prevent overheating000b = no request 001b = reduction request stage 1010b = reduction request stage 2011b = reserved f...";
CM_ BO_ 2566733054 "Aftertreatment 1 Diesel Exhaust Fluid Supply Information";
CM_ SG_ 2566733054 Aftrtrtmnt1DslExhstFldPmp "Aftertreatment 1 Diesel Exhaust Fluid Pump: State of the aftertreatment 1 Diesel Exhaust Fluid dosing pump.  Indicates if the pump is currently active (pumping).  00b = Off01b = On10b = Error11b = Not availableThe aftertreatment 1 Diesel Exhaust Flui...";
CM_ SG_ 2566733054 Aftrtrtmnt1DslExhstFldPmpPwrRl "Aftertreatment 1 Diesel Exhaust Fluid Pump Power Relay: The state of the aftertreatment 1 diesel exhaust fluid pump power relay.00b = not active - no power is being applied to the relay01b = active - power is being applied to the relay10b = error11b ...";
CM_ SG_ 2566733054 Aftrtrtmnt1DslExhstFldPmpStt "Aftertreatment 1 Diesel Exhaust Fluid Pump State: State of the aftertreatment 1 Diesel Exhaust Fluid dosing pump.  Indicates whether or not the pump is operational.00b = pump operational01b = pump error10b = reserved for SAE assignment11b = not avail...";
CM_ SG_ 2566733054 Atttt1DsExstFdDsUt1DvtVv "Aftertreatment 1 Diesel Exhaust Fluid Dosing Unit 1 Diverter Valve: Command to the valve which determines whether the diesel exhaust fluid on dosing unit 1 is delivered to the injector or is routed back to the diesel exhaust fluid tank. Zero directs ...";
CM_ SG_ 2566733054 Atttt1DsExstFdDsUt2DvtVv "Aftertreatment 1 Diesel Exhaust Fluid Dosing Unit 2 Diverter Valve: Command to the valve which determines whether the diesel exhaust fluid on dosing unit 2 is delivered to the injector or is routed back to the diesel exhaust fluid tank. Zero directs ...";
CM_ SG_ 2566733054 Atttt1DsExstFdPp1MtSpd "Aftertreatment 1 Diesel Exhaust Fluid Pump 1 Motor Speed: Rotational speed of the motor driving the first or only pump for the diesel exhaust fluid used in aftertreatment system 1 (exhaust bank 1).";
CM_ SG_ 2566733054 Atttt1DsExstFdPpDvPt "Aftertreatment 1 Diesel Exhaust Fluid Pump Drive Percentage: The percent (command) sent to the motor to control the speed of the diesel exhaust fluid pump.";
CM_ SG_ 2566733054 Atttt1DsExstFdTDVvCd "Aftertreatment 1 Diesel Exhaust Fluid Tank Drain Valve Command: Commanded percentage of maximum Aftertreatment 1 Diesel Exhaust Fluid Tank Drain Valve opening. 100% means the drain valve is fully open providing maximum flow of diesel exhaust fluid ou...";
CM_ SG_ 2566733054 Atttt1DsExstFdTFVvCd "Aftertreatment 1 Diesel Exhaust Fluid Tank Fill Valve Command: Commanded percentage of maximum Aftertreatment 1 Diesel Exhaust Fluid Tank Fill Valve opening. 100% means the fill valve is fully open providing maximum flow of diesel exhaust fluid into ...";
CM_ BO_ 2566733310 "Aftertreatment 1 SCR Reagant Tank 2 Information";
CM_ SG_ 2566733310 Aftrtrtmnt1DslExhstFldQkThwHtr "Aftertreatment 1 Diesel Exhaust Fluid Quick Thaw Heater: The diesel exhaust fluid quick thaw tank heater percentage for aftertreatment system 1 (exhaust bank 1). 0% is off. See SPN 5414 for the command for this tank heater.";
CM_ SG_ 2566733310 Atttt1DsExstFdQTwHtPFMI "Aftertreatment 1 Diesel Exhaust Fluid Quick Thaw Heater Preliminary FMI: Used to identify the applicable J1939-73 FMI detected for the heater of the diesel exhaust fluid quick thaw tank for aftertreatment system 1 (exhaust bank 1), as detected by the...";
CM_ SG_ 2566733310 Atttt1DsExstFdQTwLvVPFMI "Aftertreatment 1 Diesel Exhaust Fluid Quick Thaw Level/Volume Preliminary FMI: Used to identify the applicable J1939-73 FMI detected for the fluid level height of the diesel exhaust fluid quick thaw tank for aftertreatment system 1 (exhaust bank 1), ...";
CM_ SG_ 2566733310 Atttt1DsExstFdQTwTLv "Aftertreatment 1 Diesel Exhaust Fluid Quick Thaw Tank Level: The diesel exhaust fluid level height in mm in the diesel exhaust fluid quick thaw tank for aftertreatment system 1 (exhaust bank 1). See SPN 4367 for alternate measurement. Parameter Speci...";
CM_ SG_ 2566733310 Atttt1DsExstFdQTwTptPFMI "Aftertreatment 1 Diesel Exhaust Fluid Quick Thaw Temperature Preliminary FMI: Used to identify the applicable J1939-73 FMI detected for the diesel exhaust fluid quick thaw tank temperature for aftertreatment system 1 (exhaust bank 1), as detected by ...";
CM_ SG_ 2566733310 Atttt1DsExstFdQTwTV "Aftertreatment 1 Diesel Exhaust Fluid Quick Thaw Tank Volume: Ratio of volume of diesel exhaust fluid to the total volume of the diesel exhaust fluid quick thaw tank for aftertreatment system 1 (exhaust bank 1).  0% is empty and 100% is full.  See SP...";
CM_ SG_ 2566733310 Atttt1DsExstFdQTwTTpt "Aftertreatment 1 Diesel Exhaust Fluid Quick Thaw Tank Temperature: The diesel exhaust fluid quick thaw tank temperature for aftertreatment system 1 (exhaust bank 1).";
CM_ BO_ 2566733822 "Aftertreatment 1 SCR Exhaust Gas Pressures";
CM_ SG_ 2566733822 Aftrtrtmnt1SCRDffrntlPrssr "Aftertreatment 1 SCR Differential Pressure: Differential pressure measured between the intake and outlet of an SCR component in exhaust bank 1.";
CM_ SG_ 2566733822 Aftrtrtmnt1SCRIntkAsltPrssr "Aftertreatment 1 SCR Intake Absolute Pressure: Used to read the pressure at the catalyst intake of the selective catalytic reduction system of aftertreatment 1.";
CM_ SG_ 2566733822 Aftrtrtmnt1SCRIntkPrssr "Aftertreatment 1 SCR Intake Pressure: The gage pressure at the intake of the selective catalytic reduction system of Aftertreatment 1.";
CM_ SG_ 2566733822 Atttt1SCRDtPssPFMI "Aftertreatment 1 SCR Differential Pressure Preliminary FMI: Used to identify the applicable J1939-73 FMI detected in the SCR differential pressure sensor by the manufacturer’s sensor control software in exhaust bank 1.  In the case of multiple failur...";
CM_ BO_ 2566734078 "Aftertreatment 1 SCR Dosing System Requests 2";
CM_ SG_ 2566734078 Aftrtrtmnt1DslExhstFldLnHtr1 "Aftertreatment 1 Diesel Exhaust Fluid Line Heater 1: The diesel exhaust fluid line heater 1 request for aftertreatment system 1 (exhaust bank 1).00b = request for heater to be inactive 01b = request for heater to be active 10b = reserved for future a...";
CM_ SG_ 2566734078 Aftrtrtmnt1DslExhstFldLnHtr10 "Aftertreatment 1 Diesel Exhaust Fluid Line Heater 10: The diesel exhaust fluid line heater 10 request for aftertreatment system 1 (exhaust bank 1).00b = request for heater to be inactive01b = request for heater to be active10b = reserved for future a...";
CM_ SG_ 2566734078 Aftrtrtmnt1DslExhstFldLnHtr2 "Aftertreatment 1 Diesel Exhaust Fluid Line Heater 2: The diesel exhaust fluid line heater 2 request for aftertreatment system 1 (exhaust bank 1).00b = request for heater to be inactive 01b = request for heater to be active 10b = reserved for future a...";
CM_ SG_ 2566734078 Aftrtrtmnt1DslExhstFldLnHtr3 "Aftertreatment 1 Diesel Exhaust Fluid Line Heater 3: The diesel exhaust fluid line heater 3 request for aftertreatment system 1 (exhaust bank 1).00b = request for heater to be inactive 01b = request for heater to be active 10b = reserved for future a...";
CM_ SG_ 2566734078 Aftrtrtmnt1DslExhstFldLnHtr4 "Aftertreatment 1 Diesel Exhaust Fluid Line Heater 4: The diesel exhaust fluid line heater 4 request for aftertreatment system 1 (exhaust bank 1).00b = request for heater to be inactive 01b = request for heater to be active 10b = reserved for future a...";
CM_ SG_ 2566734078 Aftrtrtmnt1DslExhstFldLnHtr5 "Aftertreatment 1 Diesel Exhaust Fluid Line Heater 5: The diesel exhaust fluid line heater 5 request for aftertreatment system 1 (exhaust bank 1).00b = request for heater to be inactive01b = request for heater to be active10b = reserved for future ass...";
CM_ SG_ 2566734078 Aftrtrtmnt1DslExhstFldLnHtr6 "Aftertreatment 1 Diesel Exhaust Fluid Line Heater 6: The diesel exhaust fluid line heater 6 request for aftertreatment system 1 (exhaust bank 1).00b = request for heater to be inactive01b = request for heater to be active10b = reserved for future ass...";
CM_ SG_ 2566734078 Aftrtrtmnt1DslExhstFldLnHtr7 "Aftertreatment 1 Diesel Exhaust Fluid Line Heater 7: The diesel exhaust fluid line heater 7 request for aftertreatment system 1 (exhaust bank 1).00b = request for heater to be inactive01b = request for heater to be active10b = reserved for future ass...";
CM_ SG_ 2566734078 Aftrtrtmnt1DslExhstFldLnHtr8 "Aftertreatment 1 Diesel Exhaust Fluid Line Heater 8: The diesel exhaust fluid line heater 8 request for aftertreatment system 1 (exhaust bank 1).00b = request for heater to be inactive01b = request for heater to be active10b = reserved for future ass...";
CM_ SG_ 2566734078 Aftrtrtmnt1DslExhstFldLnHtr9 "Aftertreatment 1 Diesel Exhaust Fluid Line Heater 9: The diesel exhaust fluid line heater 9 request for aftertreatment system 1 (exhaust bank 1).00b = request for heater to be inactive01b = request for heater to be active10b = reserved for future ass...";
CM_ SG_ 2566734078 Aftrtrtmnt1DslExhstFldLnHtrRl1 "Aftertreatment 1 Diesel Exhaust Fluid Line Heater Relay 1: The Aftertreatment Diesel Exhaust Fluid Line Heater Relay 1 is used to energize one or more DEF line heaters.00b = Off01b = On10b = Error11b = Not available";
CM_ SG_ 2566734078 Aftrtrtmnt1DslExhstFldLnHtrRl2 "Aftertreatment 1 Diesel Exhaust Fluid Line Heater Relay 2: The Aftertreatment Diesel Exhaust Fluid Line Heater Relay 2 is used to energize one or more DEF line heaters.00b = Off01b = On10b = Error11b = Not available";
CM_ SG_ 2566734078 Aftrtrtmnt1DslExhstFldLnHtrRl3 "Aftertreatment 1 Diesel Exhaust Fluid Line Heater Relay 3: The aftertreatment diesel exhaust fluid line heater relay 3 is used to energize one or more DEF line heaters.00b = Off01b = On10b = Error11b = Not available";
CM_ SG_ 2566734078 Atttt1DsExstFdDsFtSppssRqst "Aftertreatment 1 Diesel Exhaust Fluid Doser Fault Suppression Request: Used if external devices can warn of conditions that require suppression of potential faults in the doser due to environmental conditions.00b = Error suppression off01b = Error su...";
CM_ SG_ 2566734078 Atttt1DsExstFdDsHtMdRqst "Aftertreatment 1 Diesel Exhaust Fluid Doser Heating Mode Request: Used if multiple heater modes are available in the Doser.000b = Heater off001b = Heater economy mode010b = Heater automatic mode011b = Heater on100b to 110b = Reserved111b = Not availa...";
CM_ SG_ 2566734078 Atttt1DsExstFdPpHtCd "Aftertreatment 1 Diesel Exhaust Fluid Pump Heater Command: Command for the Aftertreatment 1 Diesel Exhaust Fluid Pump Heater. A value of 0% means no heating commanded, a value of 100% means full heating commanded. See SPN 5706 for the measured value ...";
CM_ SG_ 2566734078 Atttt1DsExstFdQTwHtCd "Aftertreatment 1 Diesel Exhaust Fluid Quick Thaw Heater Command: The command for the heater of the diesel exhaust fluid quick thaw tank for aftertreatment system 1 (exhaust bank 1).  See SPN 4372 for the measured heater percentage for the heater of t...";
CM_ SG_ 2566734078 Atttt1DsExstFdTHtCd "Aftertreatment 1 Diesel Exhaust Fluid Tank Heater Command: Command for the Aftertreatment 1 Diesel Exhaust Fluid Tank Heater.  A value of 0% means no heating applied, a value of 100% means full heating applied.  See SPN 3363 for the measured value of...";
CM_ BO_ 2566734334 "Aftertreatment 1 SCR Dosing System Information 2";
CM_ SG_ 2566734334 Aftrtrtmnt1DslExhstFldLnHtr1Stt "Aftertreatment 1 Diesel Exhaust Fluid Line Heater 1 State: The diesel exhaust fluid line heater 1 state for aftertreatment system 1 (exhaust bank 1). 00b = heater inactive 01b = heater active 10b = error 11b = not available";
CM_ SG_ 2566734334 Aftrtrtmnt1DslExhstFldLnHtr2Stt "Aftertreatment 1 Diesel Exhaust Fluid Line Heater 2 State: The diesel exhaust fluid line heater 2 state for aftertreatment system 1 (exhaust bank 1). 00b = heater inactive 01b = heater active 10b = error 11b = not available";
CM_ SG_ 2566734334 Aftrtrtmnt1DslExhstFldLnHtr3Stt "Aftertreatment 1 Diesel Exhaust Fluid Line Heater 3 State: The diesel exhaust fluid line heater 3 state for aftertreatment system 1 (exhaust bank 1). 00b = heater inactive 01b = heater active 10b = error 11b = not available";
CM_ SG_ 2566734334 Aftrtrtmnt1DslExhstFldLnHtr4Stt "Aftertreatment 1 Diesel Exhaust Fluid Line Heater 4 State: The diesel exhaust fluid line heater 4 state for aftertreatment system 1 (exhaust bank 1). 00b = heater inactive 01b = heater active 10b = error 11b = not available";
CM_ SG_ 2566734334 Aftrtrtmnt1SCRDsngArAssstVlv "Aftertreatment 1 SCR Dosing Air Assist Valve: The position of the valve used to regulate the air supply of an air assist SCR dosing system for an engine. 0% represents no supply and 100% is full supply.";
CM_ SG_ 2566734334 Aftrtrtmnt1SCRFdkCntrlStts "Aftertreatment 1 SCR Feedback Control Status: The SCR feedback control status (open/closed loop) for aftertreatment system 1 (exhaust bank 1).000b = open loop control active 001b = closed loop control active 010b = reserved for future assignment by S...";
CM_ SG_ 2566734334 Atttt1DsExstFdDs1Tpt "Aftertreatment 1 Diesel Exhaust Fluid Doser 1 Temperature: The temperature (measured closest to dosing valve) of the first or only DEF dosing unit for aftertreatment system 1 (exhaust bank 1).";
CM_ SG_ 2566734334 Atttt1DsExstFdLHt1PFMI "Aftertreatment 1 Diesel Exhaust Fluid Line Heater 1 Preliminary FMI: Used to identify the applicable J1939-73 FMI detected in the diesel exhaust fluid line heater 1, by the manufacturer’s control software in exhaust bank 1.  In the case of multiple f...";
CM_ SG_ 2566734334 Atttt1DsExstFdLHt2PFMI "Aftertreatment 1 Diesel Exhaust Fluid Line Heater 2 Preliminary FMI: Used to identify the applicable J1939-73 FMI detected in the diesel exhaust fluid line heater 2, by the manufacturer’s control software in exhaust bank 1.  In the case of multiple f...";
CM_ SG_ 2566734334 Atttt1DsExstFdLHt3PFMI "Aftertreatment 1 Diesel Exhaust Fluid Line Heater 3 Preliminary FMI: Used to identify the applicable J1939-73 FMI detected in the diesel exhaust fluid line heater 3, by the manufacturer’s control software in exhaust bank 1.  In the case of multiple f...";
CM_ SG_ 2566734334 Atttt1DsExstFdLHt4PFMI "Aftertreatment 1 Diesel Exhaust Fluid Line Heater 4 Preliminary FMI: Used to identify the applicable J1939-73 FMI detected in the diesel exhaust fluid line heater 4, by the manufacturer’s control software in exhaust bank 1.  In the case of multiple f...";
CM_ SG_ 2566734334 Atttt1SCRDsAAssstAstPss "Aftertreatment 1 SCR Dosing Air Assist Absolute Pressure: The SCR dosing system air assist absolute pressure for aftertreatment system 1 (exhaust bank 1).  The air assist system is used to improve the dosed reagent atomization.";
CM_ SG_ 2566734334 Atttt1SCRDsVvExstTptRdtRqst "Aftertreatment 1 SCR Doser Valve Exhaust Temperature Reduction Request: Protection request for the doser valve of the SCR system to prevent overheating000b = no request 001b = reduction request stage 1010b = reduction request stage 2011b = reserved f...";
CM_ BO_ 2566735102 "Aftertreatment 2 Fuel Control 2";
CM_ SG_ 2566735102 Aftertreatment2FuelPressure2 "Aftertreatment 2 Fuel Pressure 2: Second fuel pressure measurement for the aftertreatment 2 system.";
CM_ SG_ 2566735102 Aftrtrtmnt2FlFlwDvrtrVlvCntrl "Aftertreatment 2 Fuel Flow Diverter Valve Control: Indicates how the device is controlling the aftertreatment 2 fuel flow diverter valve. When this valve is on it diverts fuel flow from the Aftertreatment 2 Regeneration Device.00b = off01b = on10b = ...";
CM_ SG_ 2566735102 Aftrtrtmnt2FlPmpRlCntrl "Aftertreatment 2 Fuel Pump Relay Control: Indicates how the device is controlling the aftertreatment 2 fuel pump relay.00b = off01b = on10b = reserved for SAE assignment11b = not available";
CM_ SG_ 2566735102 Aftrtrtmnt2FlPrssr2Cntrl "Aftertreatment 2 Fuel Pressure 2 Control: Position that the controller is commanding the aftertreatment 2 fuel pressure 2 control to maintain.  0% = fully closed, 100% = fully open.";
CM_ BO_ 2566735358 "Aftertreatment 2 Three Way Catalyst";
CM_ SG_ 2566735358 Aftrtrtmnt2ThrWCtlstIntkTmprtr "Aftertreatment 2 Three Way Catalyst Intake Temperature: Temperature of engine combustion byproducts entering the Three Way Catalyst in exhaust bank 2.(For a single exhaust bank system, refer to parameters in PGN 64838.)";
CM_ SG_ 2566735358 Aftrtrtmnt2ThrWCtlstOtltTmprtr "Aftertreatment 2 Three Way Catalyst Outlet Temperature: Temperature of engine combustion byproducts leaving the Three Way Catalyst in exhaust bank 2.  (For a single exhaust bank system, refer to parameters in PGN 64838.)";
CM_ SG_ 2566735358 Atttt2TWCtstDtPss "Aftertreatment 2 Three Way Catalyst Differential Pressure: Exhaust differential pressure measured between the intake and exhaust of a Three Way Catalyst in exhaust bank 2.(For a single exhaust bank system, refer to parameters in PGN 64838.)";
CM_ SG_ 2566735358 Atttt2TWCtstItTptPFMI "Aftertreatment 2 Three Way Catalyst Intake Temperature Preliminary FMI: Used to identify the applicable J1939-73 FMI detected in the Three Way Catalyst intake temperature sensor by the manufacturer’s sensor control software in exhaust bank 2.  In the...";
CM_ SG_ 2566735358 Atttt2TWCtstOttTptPFMI "Aftertreatment 2 Three Way Catalyst Outlet Temperature Preliminary FMI: Used to identify the applicable J1939-73 FMI detected in the Three Way Catalyst outlet temperature sensor by the manufacturer’s sensor control software in exhaust bank 2.  In the...";
CM_ SG_ 2566735358 Atttt2TWCttCvtDtPssPFMI "Aftertreatment 2 Three Way Catalytic Converter Differential Pressure Preliminary FMI: Used to identify the applicable J1939-73 FMI detected in the Three Way Catalytic Converter differential pressure sensor by the manufacturer's sensor control softwar...";
CM_ BO_ 2566735614 "Aftertreatment 1 Three Way Catalyst";
CM_ SG_ 2566735614 Aftrtrtmnt1ThrWCtlstIntkTmprtr "Aftertreatment 1 Three Way Catalyst Intake Temperature: Temperature of engine combustion byproducts entering the Three Way Catalyst in exhaust bank 1.";
CM_ SG_ 2566735614 Aftrtrtmnt1ThrWCtlstOtltTmprtr "Aftertreatment 1 Three Way Catalyst Outlet Temperature: Temperature of engine combustion byproducts leaving the Three Way Catalyst in exhaust bank 1.";
CM_ SG_ 2566735614 Atttt1TWCtstDtPss "Aftertreatment 1 Three Way Catalyst Differential Pressure: Exhaust differential pressure measured between the intake and exhaust of a Three Way Catalyst in exhaust bank 1.";
CM_ SG_ 2566735614 Atttt1TWCtstItTptPFMI "Aftertreatment 1 Three Way Catalyst Intake Temperature Preliminary FMI: Used to identify the applicable J1939-73 FMI detected in the Three Way Catalyst intake temperature sensor by the manufacturer’s sensor control software in exhaust bank 1. In the ...";
CM_ SG_ 2566735614 Atttt1TWCtstOttTptPFMI "Aftertreatment 1 Three Way Catalyst Outlet Temperature Preliminary FMI: Used to identify the applicable J1939-73 FMI detected in the Three Way Catalyst outlet temperature sensor by the manufacturer’s sensor control software in exhaust bank 1. In the ...";
CM_ SG_ 2566735614 Atttt1TWCttCvtDtPssPFMI "Aftertreatment 1 Three Way Catalytic Converter Differential Pressure Preliminary FMI: Used to identify the applicable J1939-73 FMI detected in the Three Way Catalytic Converter differential pressure sensor by the manufacturer’s sensor control softwar...";
CM_ BO_ 2566736126 "Engine Exhaust Bank 2 O2 Fuel Trim";
CM_ SG_ 2566736126 EngnExhstBnk2O2SnsrClsdLpOprtn "Engine Exhaust Bank 2 O2 Sensor Closed Loop Operation: This parameter indicates the status of the bank 2 O2 sensor feedback closed loop operation0000b = Open loop - has not yet satisfied conditions to go closed loop0001b = Closed loop - using oxygen ...";
CM_ SG_ 2566736126 LongtermFuelTrimBank2 "Long-term Fuel Trim - Bank 2: This parameter is the long-term percent change in fueling based on the O2 sensor feedback for cylinder bank 2, based on the operating point in the nominal fuel map.";
CM_ SG_ 2566736126 ShorttermFuelTrimBank2 "Short-term Fuel Trim - Bank 2: This parameter is the short-term percent change in fueling based on the O2 sensor feedback for cylinder bank 2, based on the operating point in the nominal fuel map.";
CM_ BO_ 2566736382 "Engine Exhaust Bank 1 O2 Fuel Trim";
CM_ SG_ 2566736382 EngnExhstBnk1O2SnsrClsdLpOprtn "Engine Exhaust Bank 1 O2 Sensor Closed Loop Operation: This parameter indicates the status of the bank 1 O2 sensor feedback closed loop operation0000b = Open loop - has not yet satisfied conditions to go closed loop0001b = Closed loop - using oxygen ...";
CM_ SG_ 2566736382 LongtermFuelTrimBank1 "Long-term Fuel Trim - Bank 1: This parameter is the long-term percent change in fueling based on the O2 sensor feedback for cylinder bank 1, based on the operating point in the nominal fuel map.";
CM_ SG_ 2566736382 ShorttermFuelTrimBank1 "Short-term Fuel Trim - Bank 1: This parameter is the short-term percent change in fueling based on the O2 sensor feedback for cylinder bank 1, based on the operating point in the nominal fuel map.Note:  This is similar to SPN 1695, but with higher re...";
CM_ BO_ 2566743550 "Aftertreatment 1 Fuel Control 2";
CM_ SG_ 2566743550 Aftertreatment1FuelPressure2 "Aftertreatment 1 Fuel Pressure 2: Second fuel pressure measurement for the aftertreatment 1 system";
CM_ SG_ 2566743550 Aftrtrtmnt1FlFlwDvrtrVlvCntrl "Aftertreatment 1 Fuel Flow Diverter Valve Control: Indicates how the device is controlling the aftertreatment 1 fuel flow diverter valve. When this valve is on it diverts fuel flow from the Aftertreatment 1 Regeneration Device.00b = off01b = on10b = ...";
CM_ SG_ 2566743550 Aftrtrtmnt1FlPmpRlCntrl "Aftertreatment 1 Fuel Pump Relay Control: Indicates how the device is controlling the aftertreatment 1 fuel pump relay.00b = off01b = on10b = reserved for SAE assignment11b = not available";
CM_ SG_ 2566743550 Aftrtrtmnt1HdrrnDsrIntkFlTmprtr "Aftertreatment 1 Hydrocarbon Doser Intake Fuel Temperature: Measured temperature of the intake fuel to the hydrocarbon dosing device.";
CM_ SG_ 2566743550 Aftrtrtmnt1FlPrssr2Cntrl "Aftertreatment 1 Fuel Pressure 2 Control: Position that the controller is commanding the aftertreatment 1 fuel pressure 2 control to maintain.  0% = fully closed, 100% = fully open.";
CM_ BO_ 2566743806 "Engine Temperature 4";
CM_ SG_ 2566743806 EngineCoolantTemperature2 "Engine Coolant Temperature 2: Second temperature of liquid found in the engine cooling system.   See also SPNs 110, 4193 and 6209.";
CM_ SG_ 2566743806 EngineCoolantTemperature3 "Engine Coolant Temperature 3: Third temperature of liquid found in the engine cooling system. See also SPNs 110, 4076 and 4193.";
CM_ SG_ 2566743806 EngineCoolantThermostatOpening "Engine Coolant Thermostat Opening: The current position of the Thermostat used to regulate the temperature of the engine coolant.  0% represents the thermostat allows flow to completely bypass the radiator and 100% represents the flow is fully throug...";
CM_ SG_ 2566743806 EngnClntPmpOtltTmprtr "Engine Coolant Pump Outlet Temperature: The actual value of engine coolant temperature at the coolant pump outlet.  See also SPNs 110, 4076 and 6209 for additional coolant temperature parameters.";
CM_ SG_ 2566743806 EngnExhstGsRrltn1MxrIntkTmprtr "Engine Exhaust Gas Recirculation 1 Mixer Intake Temperature: The temperature of the EGR gas entering the intake mixer, measured after the intake throttle when provided.";
CM_ SG_ 2566743806 EngnExhstVlvAttnSstmOlTmprtr "Engine Exhaust Valve Actuation System Oil Temperature: The temperature of the oil in the hydraulic system that powers the engine exhaust valve actuation system";
CM_ BO_ 2566744062 "Zero Net Vehicle Weight Change";
CM_ SG_ 2566744062 ZeroNetVehicleWeightChange "Zero Net Vehicle Weight Change: Zero Net Vehicle Weight Change command.  A controller receiving this command will record the current Gross Combination Weight as the new Zero, and future requests for Net Vehicle Weight Change will be answered with the...";
CM_ BO_ 2566745086 "Available Axle Group Weights";
CM_ SG_ 2566745086 AddtnlTrlrAxlGrpWghtAvll "Additional Trailer Axle Group Weight Available: Indicates the availability of the additional trailer axle group for purposes of weight measurement00b = Additional trailer axle group not present01b = Additional trailer axle group present10b = Reserved...";
CM_ SG_ 2566745086 AddtnlTrtrAxlGrpWghtAvll "Additional Tractor Axle Group Weight Available: Indicates the availability of the additional tractor axle group for purposes of weight measurement00b = Additional tractor axle group not present01b = Additional tractor axle group present10b = Reserved...";
CM_ SG_ 2566745086 LiftAxleGroupWeightAvailable "Lift Axle Group Weight Available: Indicates the availability of the lift axle group for purposes of weight measurement00b = Lift axle group not present01b = Lift axle group present10b = Reserved11b = Not available / not applicable";
CM_ SG_ 2566745086 RrDrvAxlGrpWghtAvll "Rear Drive Axle Group Weight Available: Indicates if a second (or rear) drive axle group weight is available.00b = Rear drive axle group not present01b = Rear drive axle group present10b = Reserved11b = Not available / not applicableNote:  If there i...";
CM_ SG_ 2566745086 RrStrAxlGrpWghtAvll "Rear Steer Axle Group Weight Available: Indicates if a second (or rear) steer axle group weight is available.00b = Rear Steer axle group not present01b = Rear Steer axle group present10b = Reserved11b = Not available / not applicableNote:  If there i...";
CM_ SG_ 2566745086 SlrFrwrdmstDrvAxlGrpWghtAvll "Sole or Forward-most Drive Axle Group Weight Available: Indicates the availability of the sole or forward-most drive axle group for purposes of weight measurement00b = Drive axle group not present01b = Drive axle group present10b = Reserved11b = Not ...";
CM_ SG_ 2566745086 SlrFrwrdmstStrAxlGrpWghtAvll "Sole or Forward-most Steer Axle Group Weight Available: Indicates the availability of the sole or forward-most steer axle group for purposes of weight measurement00b = Steer axle group not present01b = Steer axle group present10b = Reserved11b = Not ...";
CM_ SG_ 2566745086 TagAxleGroupWeightAvailable "Tag Axle Group Weight Available: Indicates the availability of the tag axle group for purposes of weight measurement00b = Tag axle group not present01b = Tag axle group present10b = Reserved11b = Not available / not applicable";
CM_ SG_ 2566745086 TrlrAAxlGrpWghtAvll "Trailer A Axle Group Weight Available: Indicates the availability of the trailer A axle group for purposes of weight measurement00b = Trailer A axle group not present01b = Trailer A axle group present10b = Reserved11b = Not available / not applicable...";
CM_ SG_ 2566745086 TrlrBAxlGrpWghtAvll "Trailer B Axle Group Weight Available: Indicates the availability of the trailer B axle group for purposes of weight measurement00b = Trailer B axle group not present01b = Trailer B axle group present10b = Reserved11b = Not available / not applicable...";
CM_ SG_ 2566745086 TrlrCAxlGrpWghtAvll "Trailer C Axle Group Weight Available: Indicates the availability of the trailer C axle group for purposes of weight measurement00b = Trailer C axle group not present01b = Trailer C axle group present10b = Reserved11b = Not available / not applicable...";
CM_ SG_ 2566745086 TrlrDAxlGrpWghtAvll "Trailer D Axle Group Weight Available: Indicates the availability of the trailer D axle group for purposes of weight measurement00b = Trailer D axle group not present01b = Trailer D axle group present10b = Reserved11b = Not available / not applicable...";
CM_ SG_ 2566745086 TrlrEAxlGrpWghtAvll "Trailer E Axle Group Weight Available: Indicates the availability of the trailer E axle group for purposes of weight measurement00b = Trailer E axle group not present01b = Trailer E axle group present10b = Reserved11b = Not available / not applicable...";
CM_ SG_ 2566745086 TrlrFAxlGrpWghtAvll "Trailer F Axle Group Weight Available: Indicates the availability of the trailer F axle group for purposes of weight measurement00b = Trailer F axle group not present01b = Trailer F axle group present10b = Reserved11b = Not available / not applicable...";
CM_ SG_ 2566745086 TrlrGAxlGrpWghtAvll "Trailer G Axle Group Weight Available: Indicates the availability of the trailer G axle group for purposes of weight measurement00b = Trailer G axle group not present01b = Trailer G axle group present10b = Reserved11b = Not available / not applicable...";
CM_ SG_ 2566745086 TrlrHAxlGrpWghtAvll "Trailer H Axle Group Weight Available: Indicates the availability of the trailer H axle group for purposes of weight measurement00b = Trailer H axle group not present01b = Trailer H axle group present10b = Reserved11b = Not available / not applicable...";
CM_ BO_ 2566745342 "Aftertreatment 2 Air Control 2";
CM_ SG_ 2566745342 Aftrtrtmnt2SndrArDffrntlPrssr "Aftertreatment 2 Secondary Air Differential Pressure: Indicates the secondary air differential pressure for aftertreatment 2.  Secondary air is air provided to the exhaust system (per SAE J2403).";
CM_ SG_ 2566745342 Aftrtrtmnt2SndrArMssFlwRt "Aftertreatment 2 Secondary Air Mass Flow Rate: Indicates the secondary air mass flow for aftertreatment 2.  Secondary air is the air provided to the exhaust system (per SAE J2403).";
CM_ SG_ 2566745342 Aftrtrtmnt2SndrArPrssr "Aftertreatment 2 Secondary Air Pressure: Pressure of the secondary air for aftertreatment 2.  Secondary air is air provided to the exhaust system (per SAE J2403).For absolute pressure, see SPN 5590.";
CM_ SG_ 2566745342 Aftrtrtmnt2SndrArTmprtr "Aftertreatment 2 Secondary Air Temperature: Indicates the secondary air temperature for aftertreatment 2.  Secondary air is air provided to the exhaust system (per SAE J2403).";
CM_ BO_ 2566745598 "Aftertreatment 1 Air Control 2";
CM_ SG_ 2566745598 Aftrtrtmnt1SndrArDffrntlPrssr "Aftertreatment 1 Secondary Air Differential Pressure: Indicates the secondary air differential pressure for aftertreatment 1.  Secondary air is air provided to the exhaust system (per SAE J2403).";
CM_ SG_ 2566745598 Aftrtrtmnt1SndrArMssFlwRt "Aftertreatment 1 Secondary Air Mass Flow Rate: Indicates the secondary air mass flow for aftertreatment 1.  Secondary air is the air provided to the exhaust system (per SAE J2403).";
CM_ SG_ 2566745598 Aftrtrtmnt1SndrArPrssr "Aftertreatment 1 Secondary Air Pressure: Pressure of the secondary air for aftertreatment 1.  Secondary air is air provided to the exhaust system (per SAE J2403).For absolute pressure, see SPN 5589.";
CM_ SG_ 2566745598 Aftrtrtmnt1SndrArTmprtr "Aftertreatment 1 Secondary Air Temperature: Indicates the secondary air temperature for aftertreatment 1.  Secondary air is air provided to the exhaust system (per SAE J2403).";
CM_ BO_ 2566745854 "Aftertreatment 1 SCR Service Information 1";
CM_ SG_ 2566745854 Aftrtrtmnt1SCRCnvrsnEffn "Aftertreatment 1 SCR Conversion Efficiency: The SCR conversion efficiency percentage.  Calculated as 100 times the catalyst intake NOx minus the catalyst outlet NOx divided by the catalyst intake NOx.  The catalyst conversion efficiency number in its...";
CM_ SG_ 2566745854 Aftrtrtmnt1SCRSstmSlftnLvl "Aftertreatment 1 SCR System Sulfation Level: Indicates the sulfur level in the SCR system for aftertreatment 1..100% level could be the regeneration trigger level (and if conditions are not favorable for regeneration, sulfation loading can continue b...";
CM_ SG_ 2566745854 Atttt1DsExstFdAvCspt "Aftertreatment 1 Diesel Exhaust Fluid Average Consumption: Measured use of diesel exhaust fluid by a Selective Catalytic Reduction system for exhaust emission control, averaged over the previous 15 hours of engine operation.Used to determine whether ...";
CM_ SG_ 2566745854 Atttt1SCRCddDsExstFdCspt "Aftertreatment 1 SCR Commanded Diesel Exhaust Fluid Consumption: This parameter transmits the amount of diesel exhaust fluid that the emissions control system has requested to be used, averaged over the past 15 hours of engine operation.Used to deter...";
CM_ SG_ 2566745854 AttttSCROptIdtAtvTvdDst "Aftertreatment SCR Operator Inducement Active Traveled Distance: The distance traveled while SCR inducement (SPN 5246 is equal to level 1 to 5) is active.  Distance is reset once inducement is no longer active for SCR (SPN 5246 = 0).Emission Control ...";
CM_ BO_ 2566746110 "Electronic Engine Controller 8";
CM_ SG_ 2566746110 EExstGsRt1CItAstPss "Engine Exhaust Gas Recirculation 1 Cooler Intake Absolute Pressure: Exhaust gas recirculation absolute pressure is measured at the EGR cooler intake. See SPN 3358 for EGR pressure measured at the EGR cooler outlet before the valve.";
CM_ SG_ 2566746110 EngnExhstGsRrltn1ClrEffn "Engine Exhaust Gas Recirculation 1 Cooler Efficiency: Exhaust Gas Recirculation cooler efficiency is an indication of the cooler’s ability to reduce the temperature of the exhaust gas that is being recirculated back to the intake. 0% = no reduction i...";
CM_ SG_ 2566746110 EngnExhstGsRrltn1ClrIntkTmprtr "Engine Exhaust Gas Recirculation 1 Cooler Intake Temperature: Exhaust Gas Recirculation (EGR) Temperature measured at the EGR cooler intake.  See SPN 412 for Engine EGR temperature which is typically measured at the EGR cooler outlet.";
CM_ SG_ 2566746110 EngnExhstGsRrltn1Vlv2Cntrl "Engine Exhaust Gas Recirculation 1  Valve 2 Control: Desired percentage of maximum Exhaust Gas Recirculation (EGR) valve opening for valve 2.  0% means valve is closed. 100% means maximum valve opening (full gas flow).";
CM_ BO_ 2566746366 "Door ramp control";
CM_ SG_ 2566746366 Enablestatusoframp1 "Enable status of ramp 1: Enable status of ramp at doorway 1, counting from front to back on the vehicle.00b = ramp disabled01b = ramp enabled 10b = error 11b = not available";
CM_ SG_ 2566746366 Enablestatusoframp2 "Enable status of ramp 2: Enable status of ramp at doorway 2, counting from front to back on the vehicle.00b = ramp disabled01b = ramp enabled 10b = error 11b = not available";
CM_ SG_ 2566746366 Enablestatusoframp3 "Enable status of ramp 3: Enable status of ramp at doorway 3, counting from front to back on the vehicle.00b = ramp disabled01b = ramp enabled 10b = error 11b = not available";
CM_ SG_ 2566746366 Enablestatusoframp4 "Enable status of ramp 4: Enable status of ramp at doorway 4, counting from front to back on the vehicle.00b = ramp disabled01b = ramp enabled 10b = error 11b = not available";
CM_ SG_ 2566746366 Enablestatusoframp5 "Enable status of ramp 5: Enable status of ramp at doorway 5, counting from front to back on the vehicle.00b = ramp disabled01b = ramp enabled 10b = error 11b = not available";
CM_ SG_ 2566746366 Movementstatusoframp1 "Movement status of ramp 1: Movement status of ramp at doorway 1, counting from front to back on the vehicle.00b = ramp not being moved01b = ramp being moved10b = error11b = not available";
CM_ SG_ 2566746366 Movementstatusoframp2 "Movement status of ramp 2: Movement status of ramp at doorway 2, counting from front to back on the vehicle.00b = ramp not being moved01b = ramp being moved10b = error11b = not available";
CM_ SG_ 2566746366 Movementstatusoframp3 "Movement status of ramp 3: Movement status of ramp at doorway 3, counting from front to back on the vehicle.00b = ramp not being moved01b = ramp being moved10b = error11b = not available";
CM_ SG_ 2566746366 Movementstatusoframp4 "Movement status of ramp 4: Movement status of ramp at doorway 4, counting from front to back on the vehicle.00b = ramp not being moved01b = ramp being moved10b = error11b = not available";
CM_ SG_ 2566746366 Movementstatusoframp5 "Movement status of ramp 5: Movement status of ramp at doorway 5, counting from front to back on the vehicle.00b = ramp not being moved01b = ramp being moved10b = error11b = not available";
CM_ SG_ 2566746366 RetractStatusoframp1 "Retract Status of ramp 1: Retract status of ramp at doorway 1, counting from front to back on the vehicle.00b = ramp retracted01b = ramp extended10b = error11b = not available";
CM_ SG_ 2566746366 RetractStatusoframp2 "Retract Status of ramp 2: Retract status of ramp at doorway 2, counting from front to back on the vehicle.00b = ramp retracted01b = ramp extended10b = error11b = not available";
CM_ SG_ 2566746366 RetractStatusoframp3 "Retract Status of ramp 3: Retract status of ramp at doorway 3, counting from front to back on the vehicle.00b = ramp retracted01b = ramp extended10b = error11b = not available";
CM_ SG_ 2566746366 RetractStatusoframp4 "Retract Status of ramp 4: Retract status of ramp at doorway 4, counting from front to back on the vehicle.00b = ramp retracted01b = ramp extended10b = error11b = not available";
CM_ SG_ 2566746366 RetractStatusoframp5 "Retract Status of ramp 5: Retract status of ramp at doorway 5, counting from front to back on the vehicle.00b = ramp retracted01b = ramp extended10b = error11b = not available";
CM_ BO_ 2566746622 "Brake actuator stroke status";
CM_ SG_ 2566746622 TractorBrakeStrokeAxle1Left "Tractor Brake Stroke Axle 1 Left: Brake stroke status for left brake actuator on tractor axle 1. 000b = OK (Normal operation)  001b = Non-functioning010b = Overstroke 011b = Dragging brake100b = Reserved101b = Reserved110b = Sensor error111b = Not av...";
CM_ SG_ 2566746622 TractorBrakeStrokeAxle1Right "Tractor Brake Stroke Axle 1 Right: Brake stroke status for right brake actuator on tractor axle 1. 000b = OK (Normal operation)001b = Non-functioning010b = Overstroke011b = Dragging brake100b = Reserved101b = Reserved110b = Sensor error111b = Not ava...";
CM_ SG_ 2566746622 TractorBrakeStrokeAxle2Left "Tractor Brake Stroke Axle 2 Left: Brake stroke status for left brake actuator on tractor axle 2. 000b = OK (Normal operation)001b = Non-functioning010b = Overstroke011b = Dragging brake100b = Reserved101b = Reserved110b = Sensor error111b = Not avail...";
CM_ SG_ 2566746622 TractorBrakeStrokeAxle2Right "Tractor Brake Stroke Axle 2 Right: Brake stroke status for right brake actuator on tractor axle 2.000b = OK (Normal operation)001b = Non-functioning010b = Overstroke011b = Dragging brake100b = Reserved101b = Reserved110b = Sensor error111b = Not avai...";
CM_ SG_ 2566746622 TractorBrakeStrokeAxle3Left "Tractor Brake Stroke Axle 3 Left: Brake stroke status for left brake actuator on tractor axle 3.000b = OK (Normal operation)001b = Non-functioning010b = Overstroke011b = Dragging brake100b = Reserved101b = Reserved110b = Sensor error111b = Not availa...";
CM_ SG_ 2566746622 TractorBrakeStrokeAxle3Right "Tractor Brake Stroke Axle 3 Right: Brake stroke status for right brake actuator on tractor axle 3.000b = OK (Normal operation)001b = Non-functioning010b = Overstroke011b = Dragging brake100b = Reserved101b = Reserved110b = Sensor error111b = Not avai...";
CM_ SG_ 2566746622 TractorBrakeStrokeAxle4Left "Tractor Brake Stroke Axle 4 Left: Brake stroke status for left brake actuator on tractor axle 4.000b = OK (Normal operation)001b = Non-functioning010b = Overstroke011b = Dragging brake100b = Reserved101b = Reserved110b = Sensor error111b = Not availa...";
CM_ SG_ 2566746622 TractorBrakeStrokeAxle4Right "Tractor Brake Stroke Axle 4 Right: Brake stroke status for right brake actuator on tractor axle 4.000b = OK (Normal operation)001b = Non-functioning010b = Overstroke011b = Dragging brake100b = Reserved101b = Reserved110b = Sensor error111b = Not avai...";
CM_ SG_ 2566746622 TractorBrakeStrokeAxle5Left "Tractor Brake Stroke Axle 5 Left: Brake stroke status for left brake actuator on tractor axle 5.000b = OK (Normal operation)001b = Non-functioning010b = Overstroke011b = Dragging brake100b = Reserved101b = Reserved110b = Sensor error111b = Not availa...";
CM_ SG_ 2566746622 TractorBrakeStrokeAxle5Right "Tractor Brake Stroke Axle 5 Right: Brake stroke status for right brake actuator on tractor axle 5.000b = OK (Normal operation)001b = Non-functioning010b = Overstroke011b = Dragging brake100b = Reserved101b = Reserved110b = Sensor error111b = Not avai...";
CM_ SG_ 2566746622 TrailerBrakeStrokeAxle1Left "Trailer Brake Stroke Axle 1 Left: Brake stroke status for left brake actuator on trailerr axle 1.000b = OK (Normal operation)001b = Non-functioning010b = Overstroke011b = Dragging brake100b = Reserved101b = Reserved110b = Sensor error111b = Not avail...";
CM_ SG_ 2566746622 TrailerBrakeStrokeAxle1Right "Trailer Brake Stroke Axle 1 Right: Brake stroke status for right brake actuator on trailer axle 1.000b = OK (Normal operation)001b = Non-functioning010b = Overstroke011b = Dragging brake100b = Reserved101b = Reserved110b = Sensor error111b = Not avai...";
CM_ SG_ 2566746622 TrailerBrakeStrokeAxle2Left "Trailer Brake Stroke Axle 2 Left: Brake stroke status for left brake actuator on trailer axle 2.000b = OK (Normal operation)001b = Non-functioning010b = Overstroke011b = Dragging brake100b = Reserved101b = Reserved110b = Sensor error111b = Not availa...";
CM_ SG_ 2566746622 TrailerBrakeStrokeAxle2Right "Trailer Brake Stroke Axle 2 Right: Brake stroke status for right brake actuator on trailer axle 2.000b = OK (Normal operation)001b = Non-functioning010b = Overstroke011b = Dragging brake100b = Reserved101b = Reserved110b = Sensor error111b = Not avai...";
CM_ SG_ 2566746622 TrailerBrakeStrokeAxle3Left "Trailer Brake Stroke Axle 3 Left: Brake stroke status for left brake actuator on trailer axle 3.000b = OK (Normal operation)001b = Non-functioning010b = Overstroke011b = Dragging brake100b = Reserved101b = Reserved110b = Sensor error111b = Not availa...";
CM_ SG_ 2566746622 TrailerBrakeStrokeAxle3Right "Trailer Brake Stroke Axle 3 Right: Brake stroke status for right brake actuator on trailer axle 3.000b = OK (Normal operation)001b = Non-functioning010b = Overstroke011b = Dragging brake100b = Reserved101b = Reserved110b = Sensor error111b = Not avai...";
CM_ SG_ 2566746622 TrailerBrakeStrokeAxle4Left "Trailer Brake Stroke Axle 4 Left: Brake stroke status for left brake actuator on trailer axle 4.000b = OK (Normal operation)001b = Non-functioning010b = Overstroke011b = Dragging brake100b = Reserved101b = Reserved110b = Sensor error111b = Not availa...";
CM_ SG_ 2566746622 TrailerBrakeStrokeAxle4Right "Trailer Brake Stroke Axle 4 Right: Brake stroke status for right brake actuator on trailer axle 4.000b = OK (Normal operation)001b = Non-functioning010b = Overstroke011b = Dragging brake100b = Reserved101b = Reserved110b = Sensor error111b = Not avai...";
CM_ SG_ 2566746622 TrailerBrakeStrokeAxle5Left "Trailer Brake Stroke Axle 5 Left: Brake stroke status for left brake actuator on trailer axle 5.000b = OK (Normal operation)001b = Non-functioning010b = Overstroke011b = Dragging brake100b = Reserved101b = Reserved110b = Sensor error111b = Not availa...";
CM_ SG_ 2566746622 TrailerBrakeStrokeAxle5Right "Trailer Brake Stroke Axle 5 Right: Brake stroke status for right brake actuator on trailer axle 5.000b = OK (Normal operation)001b = Non-functioning010b = Overstroke011b = Dragging brake100b = Reserved101b = Reserved110b = Sensor error111b = Not avai...";
CM_ BO_ 2566746878 "Engine Spark Voltage 6";
CM_ SG_ 2566746878 EngineSparkPlug21 "Engine Spark Plug 21: The measured voltage of the spark event on Cylinder #21";
CM_ SG_ 2566746878 EngineSparkPlug22 "Engine Spark Plug 22: The measured voltage of the spark event on Cylinder #22";
CM_ SG_ 2566746878 EngineSparkPlug23 "Engine Spark Plug 23: The measured voltage of the spark event on Cylinder #23";
CM_ SG_ 2566746878 EngineSparkPlug24 "Engine Spark Plug 24: The measured voltage of the spark event on Cylinder #24";
CM_ BO_ 2566747134 "Engine Spark Voltage 5";
CM_ SG_ 2566747134 EngineSparkPlug17 "Engine Spark Plug 17: The measured voltage of the spark event on Cylinder #17";
CM_ SG_ 2566747134 EngineSparkPlug18 "Engine Spark Plug 18: The measured voltage of the spark event on Cylinder #18";
CM_ SG_ 2566747134 EngineSparkPlug19 "Engine Spark Plug 19: The measured voltage of the spark event on Cylinder #19";
CM_ SG_ 2566747134 EngineSparkPlug20 "Engine Spark Plug 20: The measured voltage of the spark event on Cylinder #20";
CM_ BO_ 2566747390 "Engine Spark Voltage 4";
CM_ SG_ 2566747390 EngineSparkPlug13 "Engine Spark Plug 13: The measured voltage of the spark event on Cylinder #13";
CM_ SG_ 2566747390 EngineSparkPlug14 "Engine Spark Plug 14: The measured voltage of the spark event on Cylinder #14";
CM_ SG_ 2566747390 EngineSparkPlug15 "Engine Spark Plug 15: The measured voltage of the spark event on Cylinder #15";
CM_ SG_ 2566747390 EngineSparkPlug16 "Engine Spark Plug 16: The measured voltage of the spark event on Cylinder #16";
CM_ BO_ 2566747646 "Engine Spark Voltage 3";
CM_ SG_ 2566747646 EngineSparkPlug10 "Engine Spark Plug 10: The measured voltage of the spark event on Cylinder #10";
CM_ SG_ 2566747646 EngineSparkPlug11 "Engine Spark Plug 11: The measured voltage of the spark event on Cylinder #11";
CM_ SG_ 2566747646 EngineSparkPlug12 "Engine Spark Plug 12: The measured voltage of the spark event on Cylinder #12";
CM_ SG_ 2566747646 EngineSparkPlug9 "Engine Spark Plug 9: The measured voltage of the spark event on Cylinder #9";
CM_ BO_ 2566747902 "Engine Spark Voltage 2";
CM_ SG_ 2566747902 EngineSparkPlug5 "Engine Spark Plug 5: The measured voltage of the spark event on Cylinder #5";
CM_ SG_ 2566747902 EngineSparkPlug6 "Engine Spark Plug 6: The measured voltage of the spark event on Cylinder #6";
CM_ SG_ 2566747902 EngineSparkPlug7 "Engine Spark Plug 7: The measured voltage of the spark event on Cylinder #7";
CM_ SG_ 2566747902 EngineSparkPlug8 "Engine Spark Plug 8: The measured voltage of the spark event on Cylinder #8";
CM_ BO_ 2566748158 "Engine Spark Voltage 1";
CM_ SG_ 2566748158 EngineSparkPlug1 "Engine Spark Plug 1: The measured voltage of the spark event on Cylinder #1";
CM_ SG_ 2566748158 EngineSparkPlug2 "Engine Spark Plug 2: The measured voltage of the spark event on Cylinder #2";
CM_ SG_ 2566748158 EngineSparkPlug3 "Engine Spark Plug 3: The measured voltage of the spark event on Cylinder #3";
CM_ SG_ 2566748158 EngineSparkPlug4 "Engine Spark Plug 4: The measured voltage of the spark event on Cylinder #4";
CM_ BO_ 2566748414 "Aftertreatment 2 Trip Information";
CM_ SG_ 2566748414 Aftrtrtmnt2DslPrtltFltrTrpFlUsd "Aftertreatment 2 Diesel Particulate Filter Trip Fuel Used: Total amount of fuel used by the aftertreatment 2 diesel particulate filter during the current trip period.NOTE: This SP needs to be reset by the Reset PG (PGN 56832).";
CM_ SG_ 2566748414 Atttt2DsPttFtTpAtvRtT "Aftertreatment 2 Diesel Particulate Filter Trip Active Regeneration Time: Total amount of time that the aftertreatment 2 diesel particulate filter has been in active regeneration during the current trip period.NOTE: This SP needs to be reset by the R...";
CM_ SG_ 2566748414 Atttt2DsPttFtTpDsdT "Aftertreatment 2 Diesel Particulate Filter Trip Disabled Time: Total amount of time that aftertreatment 2 diesel particulate filter regeneration has been manually disabled during the current trip period.NOTE: This SP needs to be reset by the Reset PG...";
CM_ SG_ 2566748414 Atttt2DsPttFtTpNAtvRtItRqsts "Aftertreatment 2 Diesel Particulate Filter Trip Number of Active Regeneration Inhibit Requests: Total number of aftertreatment 2 diesel particulate filter active regeneration inhibit requests by the operator during the current trip period.NOTE: This ...";
CM_ SG_ 2566748414 Atttt2DsPttFtTpNAtvRtMRqsts "Aftertreatment 2 Diesel Particulate Filter Trip Number of Active Regeneration Manual Requests: Total number of aftertreatment 2 diesel particulate filter active regeneration manual requests by the operator during the current trip period.NOTE: This SP...";
CM_ SG_ 2566748414 Atttt2DsPttFtTpNAtvRts "Aftertreatment 2 Diesel Particulate Filter Trip Number of Active Regenerations: Total number of active regenerations of the aftertreatment 2 diesel particulate filter during the current trip period.NOTE: This SP needs to be reset by the Reset PG (PGN...";
CM_ SG_ 2566748414 Atttt2DsPttFtTpNPssvRts "Aftertreatment 2 Diesel Particulate Filter Trip Number of Passive Regenerations: Total number of passive regenerations of the aftertreatment 2 diesel particulate filter during the current trip period.NOTE: This SP needs to be reset by the Reset PG (P...";
CM_ SG_ 2566748414 Atttt2DsPttFtTpPssvRtT "Aftertreatment 2 Diesel Particulate Filter Trip Passive Regeneration Time: Total amount of time that the aftertreatment 2 diesel particulate filter has been in passive regeneration during the current trip period.NOTE: This SP needs to be reset by the...";
CM_ BO_ 2566748670 "Aftertreatment 1 Trip Information";
CM_ SG_ 2566748670 Aftrtrtmnt1DslPrtltFltrTrpFlUsd "Aftertreatment 1 Diesel Particulate Filter Trip Fuel Used: Total amount of fuel used by the aftertreatment 1 diesel particulate filter during the current trip period.NOTE: This SP needs to be reset by the Reset PG (PGN 56832).";
CM_ SG_ 2566748670 Atttt1DsPttFtTpAtvRtT "Aftertreatment 1 Diesel Particulate Filter Trip Active Regeneration Time: Total amount of time that the aftertreatment 1 diesel particulate filter has been in active regeneration during the current trip period.NOTE: This SP needs to be reset by the R...";
CM_ SG_ 2566748670 Atttt1DsPttFtTpDsdT "Aftertreatment 1 Diesel Particulate Filter Trip Disabled Time: Total amount of time that aftertreatment 1 diesel particulate filter regeneration has been manually disabled during the current trip period.NOTE: This SP needs to be reset by the Reset PG...";
CM_ SG_ 2566748670 Atttt1DsPttFtTpNAtvRtItRqsts "Aftertreatment 1 Diesel Particulate Filter Trip Number of Active Regeneration Inhibit Requests: Total number of aftertreatment 1 diesel particulate filter active regeneration inhibit requests by the operator during the current trip period.NOTE: This ...";
CM_ SG_ 2566748670 Atttt1DsPttFtTpNAtvRtMRqsts "Aftertreatment 1 Diesel Particulate Filter Trip Number of Active Regeneration Manual Requests: Total number of aftertreatment 1 diesel particulate filter active regeneration manual requests by the operator during the current trip period.NOTE: This SP...";
CM_ SG_ 2566748670 Atttt1DsPttFtTpNAtvRts "Aftertreatment 1 Diesel Particulate Filter Trip Number of Active Regenerations: Total number of active regenerations of the aftertreatment 1 diesel particulate filter during the current trip period.NOTE: This SP needs to be reset by the Reset PG (PGN...";
CM_ SG_ 2566748670 Atttt1DsPttFtTpNPssvRts "Aftertreatment 1 Diesel Particulate Filter Trip Number of Passive Regenerations: Total number of passive regenerations of the aftertreatment 1 diesel particulate filter during the current trip period.NOTE: This SP needs to be reset by the Reset PG (P...";
CM_ SG_ 2566748670 Atttt1DsPttFtTpPssvRtT "Aftertreatment 1 Diesel Particulate Filter Trip Passive Regeneration Time: Total amount of time that the aftertreatment 1 diesel particulate filter has been in passive regeneration during the current trip period.NOTE: This SP needs to be reset by the...";
CM_ BO_ 2566748926 "Aftertreatment 2 Service 1";
CM_ SG_ 2566748926 Aftrtrtmnt2DslPrtltFltrStLdPrnt "Aftertreatment 2 Diesel Particulate Filter Soot Load Percent: Indicates the soot load percent of diesel particulate filter 2.  100% is the level at which active diesel particulate filter regeneration should be triggered.100% level is the active regen...";
CM_ SG_ 2566748926 Atttt2DsPttFtAsLdPt "Aftertreatment 2 Diesel Particulate Filter Ash Load Percent: Indicates the ash load percent of diesel particulate filter 2.  100% is the level at which diesel particulate filter ash service should be performed.100% level is the target ash service int...";
CM_ SG_ 2566748926 Atttt2DsPttFtStLdRtTsd "Aftertreatment 2 Diesel Particulate Filter Soot Load Regeneration Threshold: This parameter indicates the value that will first cause DPF regeneration in aftertreatment 2. There may be multiple parameters that cause DPF regeneration (e.g. Percent Soo...";
CM_ SG_ 2566748926 Atttt2DsPttFtTSLstAtvRt "Aftertreatment 2 Diesel Particulate Filter Time Since Last Active Regeneration: Indicates the time since the last active regeneration event of diesel particulate filter 2.";
CM_ BO_ 2566749182 "Aftertreatment 1 Service 1";
CM_ SG_ 2566749182 Aftrtrtmnt1DslPrtltFltrStLdPrnt "Aftertreatment 1 Diesel Particulate Filter Soot Load Percent: Indicates the soot load percent of diesel particulate filter 1.  100% is the level at which active diesel particulate filter regeneration should be triggered.100% level is the active regen...";
CM_ SG_ 2566749182 Atttt1DsPttFtAsLdPt "Aftertreatment 1 Diesel Particulate Filter Ash Load Percent: Indicates the ash load percent of diesel particulate filter 1.  100% is the level at which diesel particulate filter ash service should be performed.100% level is the target ash service int...";
CM_ SG_ 2566749182 Atttt1DsPttFtStLdRtTsd "Aftertreatment 1 Diesel Particulate Filter Soot Load Regeneration Threshold: This parameter indicates the value that will first cause DPF regeneration in aftertreatment 1. There may be multiple parameters that cause DPF regeneration (e.g. Percent Soo...";
CM_ SG_ 2566749182 Atttt1DsPttFtTSLstAtvRt "Aftertreatment 1 Diesel Particulate Filter Time Since Last Active Regeneration: Indicates the time since the last active regeneration event of diesel particulate filter 1.";
CM_ BO_ 2566749438 "Diesel Particulate Filter Control 1";
CM_ SG_ 2566749438 AftrtrtmntDslPrtltFltrStts "Aftertreatment Diesel Particulate Filter Status: Indicates the state of the diesel particulate filter regeneration need and urgency.  This is an aggregate of bank 1 and bank 2.  It is a system status and not individual bank status.000b = Regeneration...";
CM_ SG_ 2566749438 Atttt1DsPttFtCdtsNtMtAtvRt "Aftertreatment 1 Diesel Particulate Filter Conditions Not Met for Active Regeneration: Indicates that diesel particulate filter 1 is not able to begin or continue an active regenerate event at the current engine operating conditions.00b = active DPF ...";
CM_ SG_ 2566749438 AttttDsPttFtAtvRtStts "Aftertreatment Diesel Particulate Filter Active Regeneration Status: Indicates the state of diesel particulate filter active regeneration.  This is an aggregate of bank 1 and bank 2.  It is a system status and not individual bank status.00b = not act...";
CM_ SG_ 2566749438 AttttDsPttFtPssvRtStts "Aftertreatment Diesel Particulate Filter Passive Regeneration Status: Indicates the state of diesel particulate filter passive regeneration.  This is an aggregate of bank 1 and bank 2.  It is a system status and not individual bank status.00b = not a...";
CM_ SG_ 2566749438 DslPrtltFltrAtvRgnrtnAvlltStts "Diesel Particulate Filter Active Regeneration Availability Status: Indicates that diesel particulate filter active regeneration is available for initiation through Aftertreatment Regeneration Force Switch (SPN 3696).00b = Not ready for initiation01b ...";
CM_ SG_ 2566749438 DslPrtltFltrAtvRgnrtnFrdStts "Diesel Particulate Filter Active Regeneration Forced Status: Indicates the forced execution status of diesel particulate filter regeneration.000b = Not Active001b = Active – Forced by Switch (See SPN 3696)010b = Active – Forced by Service Tool 011b =...";
CM_ SG_ 2566749438 DslPrtltFltrAtvRgnrtnInhtdStts "Diesel Particulate Filter Active Regeneration Inhibited Status: Indicates the state of diesel particulate filter active regeneration inhibition.00b = not inhibited01b = inhibited10b = reserved for SAE assignment11b = not availableThis SP indicates th...";
CM_ SG_ 2566749438 DslPrtltFltrLmpCmmnd "Diesel Particulate Filter Lamp Command: Command to control the diesel particulate filter lamp.000b = Off001b = On – solid010b = reserved for SAE assignment 011b = reserved for SAE assignment100b = On – fast blink (1 Hz)101b = On – very fast blink110b...";
CM_ SG_ 2566749438 DsPttFtAttAtvRtIttCt "Diesel Particulate Filter Automatic Active Regeneration Initiation Configuration: Indicates the configuration of diesel particulate filter active regeneration automatic initiation.00b = not enabled01b = enabled10b = reserved for SAE assignment11b = n...";
CM_ SG_ 2566749438 DsPttFtAtvRtItdDtAtPdOId "Diesel Particulate Filter Active Regeneration Inhibited Due to Accelerator Pedal Off Idle: Indicates the state of diesel particulate filter active regeneration inhibition due to the accelerator pedal being off idle.00b = not inhibited01b = inhibited1...";
CM_ SG_ 2566749438 DsPttFtAtvRtItdDtCtDsd "Diesel Particulate Filter Active Regeneration Inhibited Due to Clutch Disengaged: Indicates the state of diesel particulate filter active regeneration inhibition due to the clutch being disengaged.00b = not inhibited01b = inhibited10b = reserved for ...";
CM_ SG_ 2566749438 DsPttFtAtvRtItdDtENtWdUp "Diesel Particulate Filter Active Regeneration Inhibited Due to Engine Not Warmed Up: Indicates the state of diesel particulate filter active regeneration inhibition due to the engine not being warmed up.00b = not inhibited01b = inhibited10b = reserve...";
CM_ SG_ 2566749438 DsPttFtAtvRtItdDtItSwt "Diesel Particulate Filter Active Regeneration Inhibited Due to Inhibit Switch: Indicates the state of diesel particulate filter active regeneration inhibition due to the Diesel Particulate Filter Regeneration Inhibit Switch.00b = not inhibited01b = i...";
CM_ SG_ 2566749438 DsPttFtAtvRtItdDtLwExstPss "Diesel Particulate Filter Active Regeneration Inhibited Due to Low Exhaust Pressure: Indicates the state of diesel particulate filter active regeneration inhibition due to low exhaust pressure.00b = not inhibited01b = inhibited10b = reserved for SAE ...";
CM_ SG_ 2566749438 DsPttFtAtvRtItdDtLwExstTpt "Diesel Particulate Filter Active Regeneration Inhibited Due to Low Exhaust Temperature: Indicates the state of diesel particulate filter active regeneration inhibition due to the exhaust temperature being too low.  This implies that the diesel partic...";
CM_ SG_ 2566749438 DsPttFtAtvRtItdDtOtNt "Diesel Particulate Filter Active Regeneration Inhibited Due to Out of Neutral: Indicates the state of diesel particulate filter active regeneration inhibition due to the transmission being out of neutral.00b = not inhibited01b = inhibited10b = reserv...";
CM_ SG_ 2566749438 DsPttFtAtvRtItdDtPBNtSt "Diesel Particulate Filter Active Regeneration Inhibited Due to Parking Brake Not Set: Indicates the state of diesel particulate filter active regeneration inhibition due to the parking brake being not set.00b = not inhibited01b = inhibited10b = reser...";
CM_ SG_ 2566749438 DsPttFtAtvRtItdDtPTOAtv "Diesel Particulate Filter Active Regeneration Inhibited Due to PTO Active: Indicates the state of diesel particulate filter active regeneration inhibition due to the PTO being active.00b = not inhibited01b = inhibited10b = reserved for SAE assignment...";
CM_ SG_ 2566749438 DsPttFtAtvRtItdDtPtSstLt "Diesel Particulate Filter Active Regeneration Inhibited Due to Permanent System Lockout: Indicates the state of diesel particulate filter active regeneration inhibition due to a permanent system lockout.00b = not inhibited01b = inhibited10b = reserve...";
CM_ SG_ 2566749438 DsPttFtAtvRtItdDtSstFtAtv "Diesel Particulate Filter Active Regeneration Inhibited Due to System Fault Active: Indicates the state of diesel particulate filter active regeneration inhibition due to a system fault being active.00b = not inhibited01b = inhibited10b = reserved fo...";
CM_ SG_ 2566749438 DsPttFtAtvRtItdDtSstTt "Diesel Particulate Filter Active Regeneration Inhibited Due to System Timeout: Indicates the state of diesel particulate filter active regeneration inhibition due to a system timeout.00b = not inhibited01b = inhibited10b = reserved for SAE assignment...";
CM_ SG_ 2566749438 DsPttFtAtvRtItdDtSvBAtv "Diesel Particulate Filter Active Regeneration Inhibited Due to Service Brake Active: Indicates the state of diesel particulate filter active regeneration inhibition due to the service brake being active.00b = not inhibited01b = inhibited10b = reserve...";
CM_ SG_ 2566749438 DsPttFtAtvRtItdDtTpSstLt "Diesel Particulate Filter Active Regeneration Inhibited Due to Temporary System Lockout: Indicates the state of diesel particulate filter active regeneration inhibition due to a temporary system lockout.00b = not inhibited01b = inhibited10b = reserve...";
CM_ SG_ 2566749438 DsPttFtAtvRtItdDtVSpdAvAwdSpd "Diesel Particulate Filter Active Regeneration Inhibited Due to Vehicle Speed Above Allowed Speed: Indicates the state of diesel particulate filter active regeneration inhibition due to the vehicle speed being above an allowed limit.00b = not inhibite...";
CM_ SG_ 2566749438 DsPttFtAtvRtItdDtVSpdBwAwdSpd "Diesel Particulate Filter Active Regeneration Inhibited Due to Vehicle Speed Below Allowed Speed: Indicates the state of diesel particulate filter active regeneration inhibition due to vehicle speed being less than the allowed vehicle speed.00b = not...";
CM_ SG_ 2566749438 ExhstSstmHghTmprtrLmpCmmnd "Exhaust System High Temperature Lamp Command: Command to control the exhaust system high temperature lamp.  This lamp indicates that the exhaust system temperature is high.000b = Off001b = On – solid 010b = reserved for SAE assignment 011b = reserved...";
CM_ SG_ 2566749438 HydrocarbonDoserPurgingEnable "Hydrocarbon Doser Purging Enable: Purging enable of the Hydrocarbon Doser (HCD).00b = Purging not enabled01b = Purging enabled - less urgent10b = Purging enabled - urgent11b = Not available";
CM_ SG_ 2566749438 DsPttFtAtvRtItdDtTs "Diesel Particulate Filter Active Regeneration Inhibited Due to Thresher: Indicates the state of diesel particulate filter active regeneration inhibition due to a combine thresher being active/engaged.This parameter indicates the reason for the diesel...";
CM_ BO_ 2566749950 "Adaptive Front-Lighting System Status";
CM_ SG_ 2566749950 LeftHeadlampDynamicBendingLight "Left Headlamp Dynamic Bending Light: This parameter indicates whether the dynamic bending light of the left headlamp is working properly.000b = Dynamic bending light deactivated.  There is no problem but for some reasons (e.g. daylight present) the b...";
CM_ SG_ 2566749950 LeftHeadlampLightDistribution "Left Headlamp Light Distribution: This parameter indicates what kind of light distribution is set by the AFS system for the left headlamp.0000b = Light distribution town - The basic light distribution for town light is generated with a symmetrical cu...";
CM_ SG_ 2566749950 RghtHdlmpDnmBndngLght "Right Headlamp Dynamic Bending Light: This parameter indicates whether the dynamic bending light of the left headlamp is working properly.000b = Dynamic bending light deactivated.  There is no problem but for some reasons (e.g. daylight present) the ...";
CM_ SG_ 2566749950 RightHeadlampLightDistribution "Right Headlamp Light Distribution: This parameter indicates what kind of light distribution is set by the AFS system for the right headlamp.0000b = Light distribution town - The basic light distribution for town light is generated with a symmetrical ...";
CM_ BO_ 2566750206 "Engine Configuration 2";
CM_ SG_ 2566750206 EngnCnfgrtnIdntftn "Engine Configuration Identification: Used to identify the hardware configuration of engine family. Each number will have a reference to set of parameters such as, but not limited to, number of cylinders, piston displacement, bore size and firing angl...";
CM_ SG_ 2566750206 MxmmCrnkAttmptsprStrtAttmpt "Maximum Crank Attempts per Start Attempt: The number of cranking cycles that will be performed before ending the start attempt.  This is intended to be used in conjunction with Crank Attempt Count on Present Start Attempt, in order to give a FMI 0 di...";
CM_ SG_ 2566750206 NmrfCmstnClsfrAvrgng "Number of Combustion Cycles for Averaging: Defined number of combustion cycles used for calculating average parameters of combustion in each cylinder.";
CM_ SG_ 2566750206 TrnsmssnIdlGvrnrFlngInhtSpprt "Transmission Idle Governor Fueling Inhibit Support: Companion parameter to Transmission Idle Governor Fueling Inhibit (SPN 7829). This configuration parameter provides confirmation to the Transmission that the engine supports the Transmission Idle Go...";
CM_ BO_ 2566751230 "Transfer Case Information";
CM_ SG_ 2566751230 TransferCaseActualGearRatio "Transfer Case Actual Gear Ratio: Actual ratio of input shaft speed to output shaft speed of the transfer case.";
CM_ SG_ 2566751230 TransferCaseDirectionStatus "Transfer Case Direction Status: Indicates the vehicle direction capability based on the current transfer case or power shuttle state.  Such devices are typically downstream of the traditional powertrain, and simply change the rotational direction of ...";
CM_ SG_ 2566751230 TransferCaseMessageChecksum "Transfer Case Message Checksum: The message checksum is used to verify the signal path from the transmitting device to the receiving device. The message checksum is calculated using the first 7 data bytes, the message counter and the bytes of the mes...";
CM_ SG_ 2566751230 TransferCaseMessageCounter "Transfer Case Message Counter: The message counter is used to detect situations where the transmitting ECU malfunction repeats the same frame all the time.  The receiver of the information may use the counter parameter to detect this situation.  The ...";
CM_ SG_ 2566751230 Transfercasestatus "Transfer case status: This parameter describes the feedback from the  transfer case controller . Used by instrument clusters,  tachographs, PTOs , etc.000b = 2 wheel high (normal or `'On Highway' Range)001b = 4 wheel high (normal or  'On Highway' Ran...";
CM_ BO_ 2566751486 "Engine Fluid Level/Pressure 9";
CM_ SG_ 2566751486 EngnIntkVlvAttnOlPrssrfrClndr17 "Engine Intake Valve Actuation Oil Pressure for Cylinder #17: The gage pressure of the oil in the hydraulic accumulator that powers the engine intake valve for cylinder #17.";
CM_ SG_ 2566751486 EngnIntkVlvAttnOlPrssrfrClndr18 "Engine Intake Valve Actuation Oil Pressure for Cylinder #18: The gage pressure of the oil in the hydraulic accumulator that powers the engine intake valve for cylinder #18.";
CM_ SG_ 2566751486 EngnIntkVlvAttnOlPrssrfrClndr19 "Engine Intake Valve Actuation Oil Pressure for Cylinder #19: The gage pressure of the oil in the hydraulic accumulator that powers the engine intake valve for cylinder #19.";
CM_ SG_ 2566751486 EngnIntkVlvAttnOlPrssrfrClndr20 "Engine Intake Valve Actuation Oil Pressure for Cylinder #20: The gage pressure of the oil in the hydraulic accumulator that powers the engine intake valve for cylinder #20.";
CM_ BO_ 2566751742 "Engine Fluid Level/Pressure 8";
CM_ SG_ 2566751742 EngnIntkVlvAttnOlPrssrfrClndr13 "Engine Intake Valve Actuation Oil Pressure for Cylinder #13: The gage pressure of the oil in the hydraulic accumulator that powers the engine intake valve for cylinder #13.";
CM_ SG_ 2566751742 EngnIntkVlvAttnOlPrssrfrClndr14 "Engine Intake Valve Actuation Oil Pressure for Cylinder #14: The gage pressure of the oil in the hydraulic accumulator that powers the engine intake valve for cylinder #14.";
CM_ SG_ 2566751742 EngnIntkVlvAttnOlPrssrfrClndr15 "Engine Intake Valve Actuation Oil Pressure for Cylinder #15: The gage pressure of the oil in the hydraulic accumulator that powers the engine intake valve for cylinder #15.";
CM_ SG_ 2566751742 EngnIntkVlvAttnOlPrssrfrClndr16 "Engine Intake Valve Actuation Oil Pressure for Cylinder #16: The gage pressure of the oil in the hydraulic accumulator that powers the engine intake valve for cylinder #16.";
CM_ BO_ 2566751998 "Engine Fluid Level/Pressure 7";
CM_ SG_ 2566751998 EngnIntkVlvAttnOlPrssrfrClndr10 "Engine Intake Valve Actuation Oil Pressure for Cylinder #10: The gage pressure of the oil in the hydraulic accumulator that powers the engine intake valve for cylinder #10.";
CM_ SG_ 2566751998 EngnIntkVlvAttnOlPrssrfrClndr11 "Engine Intake Valve Actuation Oil Pressure for Cylinder #11: The gage pressure of the oil in the hydraulic accumulator that powers the engine intake valve for cylinder #11.";
CM_ SG_ 2566751998 EngnIntkVlvAttnOlPrssrfrClndr12 "Engine Intake Valve Actuation Oil Pressure for Cylinder #12: The gage pressure of the oil in the hydraulic accumulator that powers the engine intake valve for cylinder #12.";
CM_ SG_ 2566751998 EngnIntkVlvAttnOlPrssrfrClndr9 "Engine Intake Valve Actuation Oil Pressure for Cylinder #9: The gage pressure of the oil in the hydraulic accumulator that powers the engine intake valve for cylinder #9.";
CM_ BO_ 2566752254 "Engine Fluid Level/Pressure 6";
CM_ SG_ 2566752254 EngnIntkVlvAttnOlPrssrfrClndr5 "Engine Intake Valve Actuation Oil Pressure for Cylinder #5: The gage pressure of the oil in the hydraulic accumulator that powers the engine intake valve for cylinder #5.";
CM_ SG_ 2566752254 EngnIntkVlvAttnOlPrssrfrClndr6 "Engine Intake Valve Actuation Oil Pressure for Cylinder #6: The gage pressure of the oil in the hydraulic accumulator that powers the engine intake valve for cylinder #6.";
CM_ SG_ 2566752254 EngnIntkVlvAttnOlPrssrfrClndr7 "Engine Intake Valve Actuation Oil Pressure for Cylinder #7: The gage pressure of the oil in the hydraulic accumulator that powers the engine intake valve for cylinder #7.";
CM_ SG_ 2566752254 EngnIntkVlvAttnOlPrssrfrClndr8 "Engine Intake Valve Actuation Oil Pressure for Cylinder #8: The gage pressure of the oil in the hydraulic accumulator that powers the engine intake valve for cylinder #8.";
CM_ BO_ 2566752510 "Engine Fluid Level/Pressure 5";
CM_ SG_ 2566752510 EngnIntkVlvAttnOlPrssrfrClndr1 "Engine Intake Valve Actuation Oil Pressure for Cylinder #1: The gage pressure of the oil in the hydraulic accumulator that powers the engine intake valve for cylinder #1.  This intake valve pressure is at the first cylinder in the engine, while SPN 2...";
CM_ SG_ 2566752510 EngnIntkVlvAttnOlPrssrfrClndr2 "Engine Intake Valve Actuation Oil Pressure for Cylinder #2: The gage pressure of the oil in the hydraulic accumulator that powers the engine intake valve for cylinder #2.";
CM_ SG_ 2566752510 EngnIntkVlvAttnOlPrssrfrClndr3 "Engine Intake Valve Actuation Oil Pressure for Cylinder #3: The gage pressure of the oil in the hydraulic accumulator that powers the engine intake valve for cylinder #3.";
CM_ SG_ 2566752510 EngnIntkVlvAttnOlPrssrfrClndr4 "Engine Intake Valve Actuation Oil Pressure for Cylinder #4: The gage pressure of the oil in the hydraulic accumulator that powers the engine intake valve for cylinder #4.";
CM_ BO_ 2566752766 "Vehicle Direction/Speed 2";
CM_ SG_ 2566752766 VehicleRoll "Vehicle Roll: This parameter indicates the roll in degrees from level.  Facing the direction of travel a tip to the left would be indicated by a negative number and a tip to the right would be indicated by a positive number.";
CM_ BO_ 2566753278 "Aftertreatment 2 Gas Parameters";
CM_ SG_ 2566753278 Atttt2DsPttFtItPss "Aftertreatment 2 Diesel Particulate Filter Intake Pressure: This parameter indicates the diesel particulate filter intake gage pressure 2 (bank 2).";
CM_ SG_ 2566753278 Atttt2DsPttFtOttPss "Aftertreatment 2 Diesel Particulate Filter Outlet Pressure: This parameter indicates the diesel particulate filter outlet gage pressure 2 (bank 2).";
CM_ BO_ 2566753534 "Aftertreatment 1 Gas Parameters";
CM_ SG_ 2566753534 Atttt1DsPttFtItPss "Aftertreatment 1 Diesel Particulate Filter Intake Pressure: This parameter indicates the diesel particulate filter intake gage pressure 1 (bank 1).";
CM_ SG_ 2566753534 Atttt1DsPttFtOttPss "Aftertreatment 1 Diesel Particulate Filter Outlet Pressure: This parameter indicates the diesel particulate filter outlet gage pressure 1 (bank 1).";
CM_ BO_ 2566753790 "Utility Total AC Reactive Energy";
CM_ SG_ 2566753790 UtilityTotalkVArHoursExport "Utility Total kVAr Hours Export: This parameter reports the cumulative total AC reactive energy exported from the utility.";
CM_ SG_ 2566753790 UtilityTotalkVArHoursImport "Utility Total kVAr Hours Import: This parameter reports the cumulative total AC reactive energy imported to the utility.";
CM_ BO_ 2566754046 "Generator Total AC Reactive Energy";
CM_ SG_ 2566754046 GeneratorTotalkVArHoursExport "Generator Total kVAr Hours Export: This parameter reports the cumulative total AC reactive energy exported from the generator.";
CM_ SG_ 2566754046 GeneratorTotalkVArHoursImport "Generator Total kVAr Hours Import: This parameter reports the cumulative total AC reactive energy imported to the generator.";
CM_ BO_ 2566754302 "Generator Total AC Percent Power";
CM_ SG_ 2566754302 GeneratorTotalPercentkVA "Generator Total Percent kVA: This parameter reports the generator total AC apparent power, as a percentage of rated power.";
CM_ SG_ 2566754302 GeneratorTotalPercentkVAr "Generator Total Percent kVAr: This parameter reports the generator total AC reactive power, as a percentage of rated power.";
CM_ SG_ 2566754302 GeneratorTotalPercentkW "Generator Total Percent kW: This parameter reports the generator total AC power, as a percentage of rated power.";
CM_ BO_ 2566754814 "AC Switching Device Status";
CM_ SG_ 2566754814 AutomaticTransferSwitchStatus "Automatic Transfer Switch Status: This parameter indicates the measured state of the automatic transfer switch.000b = Normal position001b = Emergency position010b = Available for SAE assignment011b = Transitioning to Normal position100b = Transitioni...";
CM_ SG_ 2566754814 BusTieBreaker1 "Bus Tie Breaker 1: The measured state of first tie breaker on the electrical power bus.000b = Open001b = Closed010b = Locked Out011b = Transitioning to Open state100b = Transitioning to Closed state101b = Available for SAE assignment110b = Error111b ...";
CM_ SG_ 2566754814 BusTieBreaker2 "Bus Tie Breaker 2: The measured state of second tie breaker on the electrical power bus.000b = Open001b = Closed010b = Locked Out011b = Transitioning to Open state100b = Transitioning to Closed state101b = Available for SAE assignment110b = Error111b...";
CM_ SG_ 2566754814 EngineLoadGroup "Engine Load Group: The engine load group for the reporting engine. An Engine Load Group is a set of engines tied together for sharing the electrical power bus load. Load Group assignments are manufacturer specific.";
CM_ SG_ 2566754814 EngineSpeedGovernorMode "Engine Speed Governor Mode: Indicates the engine speed governor operating mode.00b = Isochronous Mode01b = Droop Mode10b = Error11b = Not Available";
CM_ SG_ 2566754814 GeneratorCircuitBreakerStatus "Generator Circuit Breaker Status: This parameter indicates the measured state of the generator circuit breaker.000b = Open001b = Closed010b = Locked Out011b = Transitioning to Open state100b = Transitioning to Closed state101b = Available for SAE ass...";
CM_ SG_ 2566754814 UtilityCircuitBreakerStatus "Utility Circuit Breaker Status: This parameter indicates the measured state of the utility circuit breaker.000b = Open001b = Closed010b = Locked Out011b = Transitioning to Open state100b = Transitioning to Closed state101b = Available for SAE assignm...";
CM_ SG_ 2566754814 PackageCircuitBreakerStatus "Package Circuit Breaker Status: The state of the package circuit breaker.Generic circuit breaker for various applications.000b = Open001b = Closed010b = Locked Out011b = Transitioning to Open state100b = Transitioning to Closed state101b = Available ...";
CM_ SG_ 2566754814 SttnrInvrtrCrtBrkrStts "Stationary Inverter Circuit Breaker Status: The state of the inverter circuit breaker.For stationary non-vehicular applications of inverters.000b = Open001b = Closed010b = Locked Out011b = Transitioning to Open state100b = Transitioning to Closed sta...";
CM_ BO_ 2566755582 "Electronic Engine Controller 7";
CM_ SG_ 2566755582 EngnCrnksBrthrOlSprtrSpd "Engine Crankcase Breather Oil Separator Speed: The speed of a rotating (centrifugal) crankcase oil separator.";
CM_ SG_ 2566755582 EngnExhstGsRrltn1Vlv2Pstn "Engine Exhaust Gas Recirculation 1 Valve 2 Position: The position of the second exhaust gas recirculation valve expressed as a percentage of full travel. Zero percent means the valve is closed and no exhaust gas is flowing into the intake air stream....";
CM_ SG_ 2566755582 EngnExhstGsRrltn1VlvPstn "Engine Exhaust Gas Recirculation 1 Valve Position: The position of the exhaust gas recirculation valve expressed as a percentage of full travel. Zero percent means the valve is closed and no exhaust gas is flowing into the intake air stream. One hund...";
CM_ SG_ 2566755582 EngnIntkMnfldCmmnddPrssr "Engine Intake Manifold Commanded Pressure: Provides the commanded set point value for the engine intake manifold pressure.";
CM_ BO_ 2566755838 "Transmission Fluids 2";
CM_ SG_ 2566755838 TransmissionOilLevel2HighLow "Transmission Oil Level 2 High / Low: Second instance of a transmission oil level indicator. Conveys the current volume of transmission sump oil compared to recommended volume. Positive values indicate overfill. Zero means the transmission fluid is fi...";
CM_ SG_ 2566755838 TransmissionOilLevelSwitch "Transmission Oil Level Switch: This switch indicates whether transmission oil level is full or empty.00b = Empty01b = Full or not empty10b = Error11b = Not available";
CM_ SG_ 2566755838 TransmissionOilLifeRemaining "Transmission Oil Life Remaining: Signal which indicates the actual oil life remaining in percent.  100% means the transmission oil is brand new, and 0% means the transmission oil is at the end of its life.";
CM_ SG_ 2566755838 TransmissionOilTemperature2 "Transmission Oil Temperature 2: Second instance of transmission lubricant temperature. This parameter may reflect the temperature of a second sump or oil supply. If only one instance of transmission lubricant temperature measurement exists, SPN 177 T...";
CM_ SG_ 2566755838 TransmissionOverheatIndicator "Transmission Overheat Indicator: Signal from transmission indicating that its fluid temperature is above normal acceptable limits, and as a result, transmission operation may be altered or restricted.  The indicator is typically a lamp.  Distinctions...";
CM_ SG_ 2566755838 TrnsmssnOlFltrRstrtnSwth "Transmission Oil Filter Restriction Switch: This switch indicates whether the transmission oil filter is clogged.00b = No restriction01b = Restriction exists on oil filter10b = Error11b = Not available";
CM_ SG_ 2566755838 TrnsmssnOlLvl2CntdwnTmr "Transmission Oil Level 2 Countdown Timer: Countdown timer for the second instance of a transmission oil level indicator. Once all vehicle conditions (such as vehicle stopped, etc) are met, some transmissions may require a 'settling time' to allow the...";
CM_ SG_ 2566755838 TrnsmssnOlLvl2MsrmntStts "Transmission Oil Level 2 Measurement Status: Measurement status for the second instance of a transmission oil level indicator. Indicates if conditions are acceptable to obtain a valid transmission oil level measurement as conveyed in SPN 5914 Transmi...";
CM_ SG_ 2566755838 TrnsmssnTrqCnvrtrOlOtltTmprtr "Transmission Torque Converter Oil Outlet Temperature: Temperature of transmission torque converter outlet oil.";
CM_ BO_ 2566756094 "Fuel Information 2 (Liquid)";
CM_ SG_ 2566756094 EngineFuelReturnFlowRate "Engine Fuel Return Flow Rate: The rate of fuel flowing through a fuel return line carrying fuel from the engine back to fuel tank.";
CM_ SG_ 2566756094 EngineFuelSupplyFlowRate "Engine Fuel Supply Flow Rate: The rate of fuel flowing through a fuel supply line carrying fuel from the fuel tank to the engine.";
CM_ BO_ 2566756350 "Fuel Information 3 (Liquid)";
CM_ SG_ 2566756350 EngineFuelReturnTemperature "Engine Fuel Return Temperature: The temperature of the fuel flowing through a fuel return line from the engine back to the fuel tank.";
CM_ SG_ 2566756350 EngineFuelSupplyTemperature "Engine Fuel Supply Temperature: The temperature of the fuel flowing through a fuel supply line from the fuel tank to the engine.";
BA_DEF_ SG_  "SPN" INT 0 524287;
BA_DEF_ BO_  "VFrameFormat" ENUM  "StandardCAN","ExtendedCAN","reserved","J1939PG";
BA_DEF_DEF_  "SPN" 0;
BA_DEF_DEF_  "VFrameFormat" "J1939PG";
BA_ "SPN" SG_ 2566722302 GeneratorOverheatStatus 5000;
BA_ "SPN" SG_ 2566722302 GensetEnableActiveStatus 5005;
BA_ "SPN" SG_ 2566722302 GensetSoftstartActiveStatus 5004;
BA_ "SPN" SG_ 2566722302 GnrtrDtClExddStts 5007;
BA_ "SPN" SG_ 2566722302 GnstSstmOtptVltgRngStts 5001;
BA_ "SPN" SG_ 2566722302 GrappleMagnetSelectionSwitch 5003;
BA_ "SPN" SG_ 2566722302 ReverseCurrentRangeSetting 5002;
BA_ "SPN" SG_ 2566722302 VoltageMonitorActiveStatus 5006;
BA_ "SPN" SG_ 2566722558 MagnetBoostTime 4998;
BA_ "SPN" SG_ 2566722558 MagnetRatedPower 4999;
BA_ "SPN" SG_ 2566722814 BatteryCharger2OutputCurrent 4997;
BA_ "SPN" SG_ 2566722814 BatteryCharger2OutputVoltage 4996;
BA_ "SPN" SG_ 2566722814 BatteryCharger2PowerLineState 4995;
BA_ "SPN" SG_ 2566722814 BatteryCharger2State 4994;
BA_ "SPN" SG_ 2566723070 BatteryCharger1OutputCurrent 4993;
BA_ "SPN" SG_ 2566723070 BatteryCharger1OutputVoltage 4992;
BA_ "SPN" SG_ 2566723070 BatteryCharger1PowerLineState 4991;
BA_ "SPN" SG_ 2566723070 BatteryCharger1State 4990;
BA_ "SPN" SG_ 2566724350 Atttt1WUpDsOxdtCtstItTpt 4809;
BA_ "SPN" SG_ 2566724350 Atttt1WUpDsOxdtCtstOttTpt 4810;
BA_ "SPN" SG_ 2566724606 Aftrtrtmnt2DslPrtltFltrMnStSgnl 4788;
BA_ "SPN" SG_ 2566724606 Aftrtrtmnt2DslPrtltFltrStDnst 4787;
BA_ "SPN" SG_ 2566724606 Aftrtrtmnt2DslPrtltFltrStMss 4786;
BA_ "SPN" SG_ 2566724606 Atttt2DsPttFtMdStS 4789;
BA_ "SPN" SG_ 2566724606 Atttt2DsPttFtStSsPFMI 4790;
BA_ "SPN" SG_ 2566724606 DsPttFt2StSsECUItTpt 5570;
BA_ "SPN" SG_ 2566724862 Aftrtrtmnt1DslPrtltFltrMnStSgnl 4783;
BA_ "SPN" SG_ 2566724862 Aftrtrtmnt1DslPrtltFltrStDnst 4782;
BA_ "SPN" SG_ 2566724862 Aftrtrtmnt1DslPrtltFltrStMss 4781;
BA_ "SPN" SG_ 2566724862 Atttt1DsPttFtMdStS 4784;
BA_ "SPN" SG_ 2566724862 Atttt1DsPttFtStSsPFMI 4785;
BA_ "SPN" SG_ 2566724862 DsPttFt1StSsECUItTpt 5569;
BA_ "SPN" SG_ 2566725118 Atttt1TWCtstDtTpt 4779;
BA_ "SPN" SG_ 2566725118 Atttt2TWCtstDtTpt 4780;
BA_ "SPN" SG_ 2566725374 Atttt1GsOxdtCtstDtTpt 4777;
BA_ "SPN" SG_ 2566725374 Atttt2GsOxdtCtstDtTpt 4778;
BA_ "SPN" SG_ 2566725630 Atttt2DsOxdtCtstDtPss 4773;
BA_ "SPN" SG_ 2566725630 Atttt2DsOxdtCtstDtPssPFMI 4776;
BA_ "SPN" SG_ 2566725630 Atttt2DsOxdtCtstItTpt 4771;
BA_ "SPN" SG_ 2566725630 Atttt2DsOxdtCtstItTptPFMI 4774;
BA_ "SPN" SG_ 2566725630 Atttt2DsOxdtCtstOttTpt 4772;
BA_ "SPN" SG_ 2566725630 Atttt2DsOxdtCtstOttTptPFMI 4775;
BA_ "SPN" SG_ 2566725886 Atttt1DsOxdtCtstDtPss 4767;
BA_ "SPN" SG_ 2566725886 Atttt1DsOxdtCtstDtPssPFMI 4770;
BA_ "SPN" SG_ 2566725886 Atttt1DsOxdtCtstItTpt 4765;
BA_ "SPN" SG_ 2566725886 Atttt1DsOxdtCtstItTptPFMI 4768;
BA_ "SPN" SG_ 2566725886 Atttt1DsOxdtCtstOttTpt 4766;
BA_ "SPN" SG_ 2566725886 Atttt1DsOxdtCtstOttTptPFMI 4769;
BA_ "SPN" SG_ 2566726142 Atttt2GsOxdtCtstDtPss 4761;
BA_ "SPN" SG_ 2566726142 Atttt2GsOxdtCtstDtPssPFMI 4764;
BA_ "SPN" SG_ 2566726142 Atttt2GsOxdtCtstItTpt 4759;
BA_ "SPN" SG_ 2566726142 Atttt2GsOxdtCtstItTptPFMI 4762;
BA_ "SPN" SG_ 2566726142 Atttt2GsOxdtCtstOttTpt 4760;
BA_ "SPN" SG_ 2566726142 Atttt2GsOxdtCtstOttTptPFMI 4763;
BA_ "SPN" SG_ 2566726398 Atttt1GsOxdtCtstDtPss 4755;
BA_ "SPN" SG_ 2566726398 Atttt1GsOxdtCtstDtPssPFMI 4758;
BA_ "SPN" SG_ 2566726398 Atttt1GsOxdtCtstItTpt 4753;
BA_ "SPN" SG_ 2566726398 Atttt1GsOxdtCtstItTptPFMI 4756;
BA_ "SPN" SG_ 2566726398 Atttt1GsOxdtCtstOttTpt 4754;
BA_ "SPN" SG_ 2566726398 Atttt1GsOxdtCtstOttTptPFMI 4757;
BA_ "SPN" SG_ 2566730238 EstimatedPercentFan2Speed 1550;
BA_ "SPN" SG_ 2566730238 Fan2DriveBypassCommandStatus 1708;
BA_ "SPN" SG_ 2566730238 Fan2DriveState 1557;
BA_ "SPN" SG_ 2566730238 Fan2Speed 1598;
BA_ "SPN" SG_ 2566730238 HydraulicFan2MotorPressure 1707;
BA_ "SPN" SG_ 2566730750 Aftrtrtmnt2DslExhstFldPmp 7108;
BA_ "SPN" SG_ 2566730750 Aftrtrtmnt2DslExhstFldPmpPwrRl 8481;
BA_ "SPN" SG_ 2566730750 Aftrtrtmnt2DslExhstFldPmpStt 5438;
BA_ "SPN" SG_ 2566730750 Atttt2DsExstFdDsUt1DvtVv 4442;
BA_ "SPN" SG_ 2566730750 Atttt2DsExstFdDsUt2DvtVv 7537;
BA_ "SPN" SG_ 2566730750 Atttt2DsExstFdPp1MtSpd 4440;
BA_ "SPN" SG_ 2566730750 Atttt2DsExstFdPpDvPt 4441;
BA_ "SPN" SG_ 2566730750 Atttt2DsExstFdTDVvCd 5439;
BA_ "SPN" SG_ 2566730750 Atttt2DsExstFdTFVvCd 5437;
BA_ "SPN" SG_ 2566731006 Aftrtrtmnt2DslExhstFldQkThwHtr 4438;
BA_ "SPN" SG_ 2566731006 Atttt2DsExstFdQTwHtPFMI 4439;
BA_ "SPN" SG_ 2566731006 Atttt2DsExstFdQTwLvPFMI 4436;
BA_ "SPN" SG_ 2566731006 Atttt2DsExstFdQTwTLv 4435;
BA_ "SPN" SG_ 2566731006 Atttt2DsExstFdQTwTptPFMI 4437;
BA_ "SPN" SG_ 2566731006 Atttt2DsExstFdQTwTV 4433;
BA_ "SPN" SG_ 2566731006 Atttt2DsExstFdQTwTTpt 4434;
BA_ "SPN" SG_ 2566731262 Aftrtrtmnt2DslExhstFldTnkHtr 4431;
BA_ "SPN" SG_ 2566731262 Aftrtrtmnt2DslExhstFldTnkLvl 4428;
BA_ "SPN" SG_ 2566731262 Aftrtrtmnt2DslExhstFldTnkVlm 4426;
BA_ "SPN" SG_ 2566731262 Atttt2DsExstFdT1HtPFMI 4432;
BA_ "SPN" SG_ 2566731262 Atttt2DsExstFdT1TptPFMI 4430;
BA_ "SPN" SG_ 2566731262 Atttt2DsExstFdTLvVPFMI 4429;
BA_ "SPN" SG_ 2566731262 Atttt2DsExstFdTTpt1 4427;
BA_ "SPN" SG_ 2566731518 Aftrtrtmnt2DslExhstFldCndtvt 4422;
BA_ "SPN" SG_ 2566731518 Aftrtrtmnt2DslExhstFldCnntrtn 4421;
BA_ "SPN" SG_ 2566731518 Aftrtrtmnt2DslExhstFldTmprtr2 4420;
BA_ "SPN" SG_ 2566731518 Aftrtrtmnt2DslExhstFldTpPrprt 4425;
BA_ "SPN" SG_ 2566731518 Atttt2DsExstFdPptsPFMI 4424;
BA_ "SPN" SG_ 2566731518 Atttt2DsExstFdTpt2PFMI 4423;
BA_ "SPN" SG_ 2566731774 Aftrtrtmnt2SCRCnvrsnEffn 4419;
BA_ "SPN" SG_ 2566731774 Aftrtrtmnt2SCRSstmSlftnLvl 7849;
BA_ "SPN" SG_ 2566731774 Atttt2DsExstFdAvCspt 4417;
BA_ "SPN" SG_ 2566731774 Atttt2SCRCddDsExstFdCspt 4418;
BA_ "SPN" SG_ 2566732030 Aftrtrtmnt2SCRIntkTmprtr 4413;
BA_ "SPN" SG_ 2566732030 Aftrtrtmnt2SCROtltTmprtr 4415;
BA_ "SPN" SG_ 2566732030 Atttt2SCRItTptPFMI 4414;
BA_ "SPN" SG_ 2566732030 Atttt2SCROttTptPFMI 4416;
BA_ "SPN" SG_ 2566732286 Aftrtrtmnt2SCRDffrntlPrssr 4411;
BA_ "SPN" SG_ 2566732286 Aftrtrtmnt2SCRIntkAsltPrssr 6798;
BA_ "SPN" SG_ 2566732286 Aftrtrtmnt2SCRIntkPrssr 6587;
BA_ "SPN" SG_ 2566732286 Atttt2SCRDtPssPFMI 4412;
BA_ "SPN" SG_ 2566732542 Aftrtrtmnt2DslExhstFldLnHtr1 4407;
BA_ "SPN" SG_ 2566732542 Aftrtrtmnt2DslExhstFldLnHtr10 7571;
BA_ "SPN" SG_ 2566732542 Aftrtrtmnt2DslExhstFldLnHtr2 4408;
BA_ "SPN" SG_ 2566732542 Aftrtrtmnt2DslExhstFldLnHtr3 4409;
BA_ "SPN" SG_ 2566732542 Aftrtrtmnt2DslExhstFldLnHtr4 4410;
BA_ "SPN" SG_ 2566732542 Aftrtrtmnt2DslExhstFldLnHtr5 5490;
BA_ "SPN" SG_ 2566732542 Aftrtrtmnt2DslExhstFldLnHtr6 7567;
BA_ "SPN" SG_ 2566732542 Aftrtrtmnt2DslExhstFldLnHtr7 7568;
BA_ "SPN" SG_ 2566732542 Aftrtrtmnt2DslExhstFldLnHtr8 7569;
BA_ "SPN" SG_ 2566732542 Aftrtrtmnt2DslExhstFldLnHtr9 7570;
BA_ "SPN" SG_ 2566732542 Aftrtrtmnt2DslExhstFldLnHtrRl1 5973;
BA_ "SPN" SG_ 2566732542 Aftrtrtmnt2DslExhstFldLnHtrRl2 7526;
BA_ "SPN" SG_ 2566732542 Aftrtrtmnt2DslExhstFldLnHtrRl3 7527;
BA_ "SPN" SG_ 2566732542 Atttt2DsExstFdDsFtSppssRqst 4405;
BA_ "SPN" SG_ 2566732542 Atttt2DsExstFdDsHtMdRqst 4406;
BA_ "SPN" SG_ 2566732542 Atttt2DsExstFdQTwHtCd 5415;
BA_ "SPN" SG_ 2566732542 Atttt2DsExstFdTHtCd 5138;
BA_ "SPN" SG_ 2566732798 Aftrtrtmnt2DslExhstFldLnHtr1Stt 4393;
BA_ "SPN" SG_ 2566732798 Aftrtrtmnt2DslExhstFldLnHtr2Stt 4395;
BA_ "SPN" SG_ 2566732798 Aftrtrtmnt2DslExhstFldLnHtr3Stt 4397;
BA_ "SPN" SG_ 2566732798 Aftrtrtmnt2DslExhstFldLnHtr4Stt 4399;
BA_ "SPN" SG_ 2566732798 Aftrtrtmnt2SCRDsngArAssstVlv 4389;
BA_ "SPN" SG_ 2566732798 Aftrtrtmnt2SCRFdkCntrlStts 4392;
BA_ "SPN" SG_ 2566732798 Atttt2DsExstFdDs1Tpt 4390;
BA_ "SPN" SG_ 2566732798 Atttt2DsExstFdLHt1PFMI 4394;
BA_ "SPN" SG_ 2566732798 Atttt2DsExstFdLHt2PFMI 4396;
BA_ "SPN" SG_ 2566732798 Atttt2DsExstFdLHt3PFMI 4398;
BA_ "SPN" SG_ 2566732798 Atttt2DsExstFdLHt4PFMI 4400;
BA_ "SPN" SG_ 2566732798 Atttt2SCRDsAAssstAstPss 4388;
BA_ "SPN" SG_ 2566732798 Atttt2SCRDsVvExstTptRdtRqst 4391;
BA_ "SPN" SG_ 2566733054 Aftrtrtmnt1DslExhstFldPmp 7107;
BA_ "SPN" SG_ 2566733054 Aftrtrtmnt1DslExhstFldPmpPwrRl 7416;
BA_ "SPN" SG_ 2566733054 Aftrtrtmnt1DslExhstFldPmpStt 5435;
BA_ "SPN" SG_ 2566733054 Atttt1DsExstFdDsUt1DvtVv 4376;
BA_ "SPN" SG_ 2566733054 Atttt1DsExstFdDsUt2DvtVv 7536;
BA_ "SPN" SG_ 2566733054 Atttt1DsExstFdPp1MtSpd 4374;
BA_ "SPN" SG_ 2566733054 Atttt1DsExstFdPpDvPt 4375;
BA_ "SPN" SG_ 2566733054 Atttt1DsExstFdTDVvCd 5436;
BA_ "SPN" SG_ 2566733054 Atttt1DsExstFdTFVvCd 5434;
BA_ "SPN" SG_ 2566733310 Aftrtrtmnt1DslExhstFldQkThwHtr 4372;
BA_ "SPN" SG_ 2566733310 Atttt1DsExstFdQTwHtPFMI 4373;
BA_ "SPN" SG_ 2566733310 Atttt1DsExstFdQTwLvVPFMI 4370;
BA_ "SPN" SG_ 2566733310 Atttt1DsExstFdQTwTLv 4369;
BA_ "SPN" SG_ 2566733310 Atttt1DsExstFdQTwTptPFMI 4371;
BA_ "SPN" SG_ 2566733310 Atttt1DsExstFdQTwTV 4367;
BA_ "SPN" SG_ 2566733310 Atttt1DsExstFdQTwTTpt 4368;
BA_ "SPN" SG_ 2566733822 Aftrtrtmnt1SCRDffrntlPrssr 4358;
BA_ "SPN" SG_ 2566733822 Aftrtrtmnt1SCRIntkAsltPrssr 6797;
BA_ "SPN" SG_ 2566733822 Aftrtrtmnt1SCRIntkPrssr 6586;
BA_ "SPN" SG_ 2566733822 Atttt1SCRDtPssPFMI 4359;
BA_ "SPN" SG_ 2566734078 Aftrtrtmnt1DslExhstFldLnHtr1 4354;
BA_ "SPN" SG_ 2566734078 Aftrtrtmnt1DslExhstFldLnHtr10 7566;
BA_ "SPN" SG_ 2566734078 Aftrtrtmnt1DslExhstFldLnHtr2 4355;
BA_ "SPN" SG_ 2566734078 Aftrtrtmnt1DslExhstFldLnHtr3 4356;
BA_ "SPN" SG_ 2566734078 Aftrtrtmnt1DslExhstFldLnHtr4 4357;
BA_ "SPN" SG_ 2566734078 Aftrtrtmnt1DslExhstFldLnHtr5 7561;
BA_ "SPN" SG_ 2566734078 Aftrtrtmnt1DslExhstFldLnHtr6 7562;
BA_ "SPN" SG_ 2566734078 Aftrtrtmnt1DslExhstFldLnHtr7 7563;
BA_ "SPN" SG_ 2566734078 Aftrtrtmnt1DslExhstFldLnHtr8 7564;
BA_ "SPN" SG_ 2566734078 Aftrtrtmnt1DslExhstFldLnHtr9 7565;
BA_ "SPN" SG_ 2566734078 Aftrtrtmnt1DslExhstFldLnHtrRl1 5491;
BA_ "SPN" SG_ 2566734078 Aftrtrtmnt1DslExhstFldLnHtrRl2 7069;
BA_ "SPN" SG_ 2566734078 Aftrtrtmnt1DslExhstFldLnHtrRl3 7540;
BA_ "SPN" SG_ 2566734078 Atttt1DsExstFdDsFtSppssRqst 4352;
BA_ "SPN" SG_ 2566734078 Atttt1DsExstFdDsHtMdRqst 4353;
BA_ "SPN" SG_ 2566734078 Atttt1DsExstFdPpHtCd 5707;
BA_ "SPN" SG_ 2566734078 Atttt1DsExstFdQTwHtCd 5414;
BA_ "SPN" SG_ 2566734078 Atttt1DsExstFdTHtCd 5137;
BA_ "SPN" SG_ 2566734334 Aftrtrtmnt1DslExhstFldLnHtr1Stt 4340;
BA_ "SPN" SG_ 2566734334 Aftrtrtmnt1DslExhstFldLnHtr2Stt 4342;
BA_ "SPN" SG_ 2566734334 Aftrtrtmnt1DslExhstFldLnHtr3Stt 4344;
BA_ "SPN" SG_ 2566734334 Aftrtrtmnt1DslExhstFldLnHtr4Stt 4346;
BA_ "SPN" SG_ 2566734334 Aftrtrtmnt1SCRDsngArAssstVlv 4336;
BA_ "SPN" SG_ 2566734334 Aftrtrtmnt1SCRFdkCntrlStts 4339;
BA_ "SPN" SG_ 2566734334 Atttt1DsExstFdDs1Tpt 4337;
BA_ "SPN" SG_ 2566734334 Atttt1DsExstFdLHt1PFMI 4341;
BA_ "SPN" SG_ 2566734334 Atttt1DsExstFdLHt2PFMI 4343;
BA_ "SPN" SG_ 2566734334 Atttt1DsExstFdLHt3PFMI 4345;
BA_ "SPN" SG_ 2566734334 Atttt1DsExstFdLHt4PFMI 4347;
BA_ "SPN" SG_ 2566734334 Atttt1SCRDsAAssstAstPss 4335;
BA_ "SPN" SG_ 2566734334 Atttt1SCRDsVvExstTptRdtRqst 4338;
BA_ "SPN" SG_ 2566735102 Aftertreatment2FuelPressure2 4303;
BA_ "SPN" SG_ 2566735102 Aftrtrtmnt2FlFlwDvrtrVlvCntrl 5427;
BA_ "SPN" SG_ 2566735102 Aftrtrtmnt2FlPmpRlCntrl 5426;
BA_ "SPN" SG_ 2566735102 Aftrtrtmnt2FlPrssr2Cntrl 5428;
BA_ "SPN" SG_ 2566735358 Aftrtrtmnt2ThrWCtlstIntkTmprtr 4295;
BA_ "SPN" SG_ 2566735358 Aftrtrtmnt2ThrWCtlstOtltTmprtr 4296;
BA_ "SPN" SG_ 2566735358 Atttt2TWCtstDtPss 4297;
BA_ "SPN" SG_ 2566735358 Atttt2TWCtstItTptPFMI 4298;
BA_ "SPN" SG_ 2566735358 Atttt2TWCtstOttTptPFMI 4299;
BA_ "SPN" SG_ 2566735358 Atttt2TWCttCvtDtPssPFMI 4300;
BA_ "SPN" SG_ 2566735614 Aftrtrtmnt1ThrWCtlstIntkTmprtr 4289;
BA_ "SPN" SG_ 2566735614 Aftrtrtmnt1ThrWCtlstOtltTmprtr 4290;
BA_ "SPN" SG_ 2566735614 Atttt1TWCtstDtPss 4291;
BA_ "SPN" SG_ 2566735614 Atttt1TWCtstItTptPFMI 4292;
BA_ "SPN" SG_ 2566735614 Atttt1TWCtstOttTptPFMI 4293;
BA_ "SPN" SG_ 2566735614 Atttt1TWCttCvtDtPssPFMI 4294;
BA_ "SPN" SG_ 2566736126 EngnExhstBnk2O2SnsrClsdLpOprtn 4241;
BA_ "SPN" SG_ 2566736126 LongtermFuelTrimBank2 4239;
BA_ "SPN" SG_ 2566736126 ShorttermFuelTrimBank2 4238;
BA_ "SPN" SG_ 2566736382 EngnExhstBnk1O2SnsrClsdLpOprtn 4240;
BA_ "SPN" SG_ 2566736382 LongtermFuelTrimBank1 4237;
BA_ "SPN" SG_ 2566736382 ShorttermFuelTrimBank1 4236;
BA_ "SPN" SG_ 2566743550 Aftertreatment1FuelPressure2 4077;
BA_ "SPN" SG_ 2566743550 Aftrtrtmnt1FlFlwDvrtrVlvCntrl 5424;
BA_ "SPN" SG_ 2566743550 Aftrtrtmnt1FlPmpRlCntrl 5423;
BA_ "SPN" SG_ 2566743550 Aftrtrtmnt1HdrrnDsrIntkFlTmprtr 5456;
BA_ "SPN" SG_ 2566743550 Aftrtrtmnt1FlPrssr2Cntrl 5425;
BA_ "SPN" SG_ 2566743806 EngineCoolantTemperature2 4076;
BA_ "SPN" SG_ 2566743806 EngineCoolantTemperature3 6209;
BA_ "SPN" SG_ 2566743806 EngineCoolantThermostatOpening 4194;
BA_ "SPN" SG_ 2566743806 EngnClntPmpOtltTmprtr 4193;
BA_ "SPN" SG_ 2566743806 EngnExhstGsRrltn1MxrIntkTmprtr 5020;
BA_ "SPN" SG_ 2566743806 EngnExhstVlvAttnSstmOlTmprtr 4288;
BA_ "SPN" SG_ 2566744062 ZeroNetVehicleWeightChange 4075;
BA_ "SPN" SG_ 2566745086 AddtnlTrlrAxlGrpWghtAvll 4072;
BA_ "SPN" SG_ 2566745086 AddtnlTrtrAxlGrpWghtAvll 4063;
BA_ "SPN" SG_ 2566745086 LiftAxleGroupWeightAvailable 4060;
BA_ "SPN" SG_ 2566745086 RrDrvAxlGrpWghtAvll 5934;
BA_ "SPN" SG_ 2566745086 RrStrAxlGrpWghtAvll 5933;
BA_ "SPN" SG_ 2566745086 SlrFrwrdmstDrvAxlGrpWghtAvll 4061;
BA_ "SPN" SG_ 2566745086 SlrFrwrdmstStrAxlGrpWghtAvll 4059;
BA_ "SPN" SG_ 2566745086 TagAxleGroupWeightAvailable 4062;
BA_ "SPN" SG_ 2566745086 TrlrAAxlGrpWghtAvll 4064;
BA_ "SPN" SG_ 2566745086 TrlrBAxlGrpWghtAvll 4065;
BA_ "SPN" SG_ 2566745086 TrlrCAxlGrpWghtAvll 4066;
BA_ "SPN" SG_ 2566745086 TrlrDAxlGrpWghtAvll 4067;
BA_ "SPN" SG_ 2566745086 TrlrEAxlGrpWghtAvll 4068;
BA_ "SPN" SG_ 2566745086 TrlrFAxlGrpWghtAvll 4069;
BA_ "SPN" SG_ 2566745086 TrlrGAxlGrpWghtAvll 4070;
BA_ "SPN" SG_ 2566745086 TrlrHAxlGrpWghtAvll 4071;
BA_ "SPN" SG_ 2566745342 Aftrtrtmnt2SndrArDffrntlPrssr 3833;
BA_ "SPN" SG_ 2566745342 Aftrtrtmnt2SndrArMssFlwRt 3835;
BA_ "SPN" SG_ 2566745342 Aftrtrtmnt2SndrArPrssr 3838;
BA_ "SPN" SG_ 2566745342 Aftrtrtmnt2SndrArTmprtr 3834;
BA_ "SPN" SG_ 2566745598 Aftrtrtmnt1SndrArDffrntlPrssr 3830;
BA_ "SPN" SG_ 2566745598 Aftrtrtmnt1SndrArMssFlwRt 3832;
BA_ "SPN" SG_ 2566745598 Aftrtrtmnt1SndrArPrssr 3837;
BA_ "SPN" SG_ 2566745598 Aftrtrtmnt1SndrArTmprtr 3831;
BA_ "SPN" SG_ 2566745854 Aftrtrtmnt1SCRCnvrsnEffn 4364;
BA_ "SPN" SG_ 2566745854 Aftrtrtmnt1SCRSstmSlftnLvl 7504;
BA_ "SPN" SG_ 2566745854 Atttt1DsExstFdAvCspt 3826;
BA_ "SPN" SG_ 2566745854 Atttt1SCRCddDsExstFdCspt 3828;
BA_ "SPN" SG_ 2566745854 AttttSCROptIdtAtvTvdDst 5463;
BA_ "SPN" SG_ 2566746110 EExstGsRt1CItAstPss 4751;
BA_ "SPN" SG_ 2566746110 EngnExhstGsRrltn1ClrEffn 4752;
BA_ "SPN" SG_ 2566746110 EngnExhstGsRrltn1ClrIntkTmprtr 4750;
BA_ "SPN" SG_ 2566746110 EngnExhstGsRrltn1Vlv2Cntrl 3821;
BA_ "SPN" SG_ 2566746366 Enablestatusoframp1 3811;
BA_ "SPN" SG_ 2566746366 Enablestatusoframp2 3814;
BA_ "SPN" SG_ 2566746366 Enablestatusoframp3 3817;
BA_ "SPN" SG_ 2566746366 Enablestatusoframp4 4455;
BA_ "SPN" SG_ 2566746366 Enablestatusoframp5 4458;
BA_ "SPN" SG_ 2566746366 Movementstatusoframp1 3812;
BA_ "SPN" SG_ 2566746366 Movementstatusoframp2 3815;
BA_ "SPN" SG_ 2566746366 Movementstatusoframp3 3818;
BA_ "SPN" SG_ 2566746366 Movementstatusoframp4 4456;
BA_ "SPN" SG_ 2566746366 Movementstatusoframp5 4459;
BA_ "SPN" SG_ 2566746366 RetractStatusoframp1 3810;
BA_ "SPN" SG_ 2566746366 RetractStatusoframp2 3813;
BA_ "SPN" SG_ 2566746366 RetractStatusoframp3 3816;
BA_ "SPN" SG_ 2566746366 RetractStatusoframp4 4454;
BA_ "SPN" SG_ 2566746366 RetractStatusoframp5 4457;
BA_ "SPN" SG_ 2566746622 TractorBrakeStrokeAxle1Left 3785;
BA_ "SPN" SG_ 2566746622 TractorBrakeStrokeAxle1Right 3786;
BA_ "SPN" SG_ 2566746622 TractorBrakeStrokeAxle2Left 3787;
BA_ "SPN" SG_ 2566746622 TractorBrakeStrokeAxle2Right 3788;
BA_ "SPN" SG_ 2566746622 TractorBrakeStrokeAxle3Left 3789;
BA_ "SPN" SG_ 2566746622 TractorBrakeStrokeAxle3Right 3790;
BA_ "SPN" SG_ 2566746622 TractorBrakeStrokeAxle4Left 3791;
BA_ "SPN" SG_ 2566746622 TractorBrakeStrokeAxle4Right 3792;
BA_ "SPN" SG_ 2566746622 TractorBrakeStrokeAxle5Left 3793;
BA_ "SPN" SG_ 2566746622 TractorBrakeStrokeAxle5Right 3794;
BA_ "SPN" SG_ 2566746622 TrailerBrakeStrokeAxle1Left 3795;
BA_ "SPN" SG_ 2566746622 TrailerBrakeStrokeAxle1Right 3796;
BA_ "SPN" SG_ 2566746622 TrailerBrakeStrokeAxle2Left 3797;
BA_ "SPN" SG_ 2566746622 TrailerBrakeStrokeAxle2Right 3798;
BA_ "SPN" SG_ 2566746622 TrailerBrakeStrokeAxle3Left 3799;
BA_ "SPN" SG_ 2566746622 TrailerBrakeStrokeAxle3Right 3800;
BA_ "SPN" SG_ 2566746622 TrailerBrakeStrokeAxle4Left 3801;
BA_ "SPN" SG_ 2566746622 TrailerBrakeStrokeAxle4Right 3802;
BA_ "SPN" SG_ 2566746622 TrailerBrakeStrokeAxle5Left 3803;
BA_ "SPN" SG_ 2566746622 TrailerBrakeStrokeAxle5Right 3804;
BA_ "SPN" SG_ 2566746878 EngineSparkPlug21 1314;
BA_ "SPN" SG_ 2566746878 EngineSparkPlug22 1315;
BA_ "SPN" SG_ 2566746878 EngineSparkPlug23 1316;
BA_ "SPN" SG_ 2566746878 EngineSparkPlug24 1317;
BA_ "SPN" SG_ 2566747134 EngineSparkPlug17 1310;
BA_ "SPN" SG_ 2566747134 EngineSparkPlug18 1311;
BA_ "SPN" SG_ 2566747134 EngineSparkPlug19 1312;
BA_ "SPN" SG_ 2566747134 EngineSparkPlug20 1313;
BA_ "SPN" SG_ 2566747390 EngineSparkPlug13 1306;
BA_ "SPN" SG_ 2566747390 EngineSparkPlug14 1307;
BA_ "SPN" SG_ 2566747390 EngineSparkPlug15 1308;
BA_ "SPN" SG_ 2566747390 EngineSparkPlug16 1309;
BA_ "SPN" SG_ 2566747646 EngineSparkPlug10 1303;
BA_ "SPN" SG_ 2566747646 EngineSparkPlug11 1304;
BA_ "SPN" SG_ 2566747646 EngineSparkPlug12 1305;
BA_ "SPN" SG_ 2566747646 EngineSparkPlug9 1302;
BA_ "SPN" SG_ 2566747902 EngineSparkPlug5 1298;
BA_ "SPN" SG_ 2566747902 EngineSparkPlug6 1299;
BA_ "SPN" SG_ 2566747902 EngineSparkPlug7 1300;
BA_ "SPN" SG_ 2566747902 EngineSparkPlug8 1301;
BA_ "SPN" SG_ 2566748158 EngineSparkPlug1 1294;
BA_ "SPN" SG_ 2566748158 EngineSparkPlug2 1295;
BA_ "SPN" SG_ 2566748158 EngineSparkPlug3 1296;
BA_ "SPN" SG_ 2566748158 EngineSparkPlug4 1297;
BA_ "SPN" SG_ 2566748414 Aftrtrtmnt2DslPrtltFltrTrpFlUsd 3741;
BA_ "SPN" SG_ 2566748414 Atttt2DsPttFtTpAtvRtT 3742;
BA_ "SPN" SG_ 2566748414 Atttt2DsPttFtTpDsdT 3743;
BA_ "SPN" SG_ 2566748414 Atttt2DsPttFtTpNAtvRtItRqsts 3747;
BA_ "SPN" SG_ 2566748414 Atttt2DsPttFtTpNAtvRtMRqsts 3748;
BA_ "SPN" SG_ 2566748414 Atttt2DsPttFtTpNAtvRts 3744;
BA_ "SPN" SG_ 2566748414 Atttt2DsPttFtTpNPssvRts 3746;
BA_ "SPN" SG_ 2566748414 Atttt2DsPttFtTpPssvRtT 3745;
BA_ "SPN" SG_ 2566748670 Aftrtrtmnt1DslPrtltFltrTrpFlUsd 3733;
BA_ "SPN" SG_ 2566748670 Atttt1DsPttFtTpAtvRtT 3734;
BA_ "SPN" SG_ 2566748670 Atttt1DsPttFtTpDsdT 3735;
BA_ "SPN" SG_ 2566748670 Atttt1DsPttFtTpNAtvRtItRqsts 3739;
BA_ "SPN" SG_ 2566748670 Atttt1DsPttFtTpNAtvRtMRqsts 3740;
BA_ "SPN" SG_ 2566748670 Atttt1DsPttFtTpNAtvRts 3736;
BA_ "SPN" SG_ 2566748670 Atttt1DsPttFtTpNPssvRts 3738;
BA_ "SPN" SG_ 2566748670 Atttt1DsPttFtTpPssvRtT 3737;
BA_ "SPN" SG_ 2566748926 Aftrtrtmnt2DslPrtltFltrStLdPrnt 3722;
BA_ "SPN" SG_ 2566748926 Atttt2DsPttFtAsLdPt 3723;
BA_ "SPN" SG_ 2566748926 Atttt2DsPttFtStLdRtTsd 5467;
BA_ "SPN" SG_ 2566748926 Atttt2DsPttFtTSLstAtvRt 3724;
BA_ "SPN" SG_ 2566749182 Aftrtrtmnt1DslPrtltFltrStLdPrnt 3719;
BA_ "SPN" SG_ 2566749182 Atttt1DsPttFtAsLdPt 3720;
BA_ "SPN" SG_ 2566749182 Atttt1DsPttFtStLdRtTsd 5466;
BA_ "SPN" SG_ 2566749182 Atttt1DsPttFtTSLstAtvRt 3721;
BA_ "SPN" SG_ 2566749438 AftrtrtmntDslPrtltFltrStts 3701;
BA_ "SPN" SG_ 2566749438 Atttt1DsPttFtCdtsNtMtAtvRt 3750;
BA_ "SPN" SG_ 2566749438 AttttDsPttFtAtvRtStts 3700;
BA_ "SPN" SG_ 2566749438 AttttDsPttFtPssvRtStts 3699;
BA_ "SPN" SG_ 2566749438 DslPrtltFltrAtvRgnrtnAvlltStts 8857;
BA_ "SPN" SG_ 2566749438 DslPrtltFltrAtvRgnrtnFrdStts 4175;
BA_ "SPN" SG_ 2566749438 DslPrtltFltrAtvRgnrtnInhtdStts 3702;
BA_ "SPN" SG_ 2566749438 DslPrtltFltrLmpCmmnd 3697;
BA_ "SPN" SG_ 2566749438 DsPttFtAttAtvRtIttCt 3718;
BA_ "SPN" SG_ 2566749438 DsPttFtAtvRtItdDtAtPdOId 3707;
BA_ "SPN" SG_ 2566749438 DsPttFtAtvRtItdDtCtDsd 3704;
BA_ "SPN" SG_ 2566749438 DsPttFtAtvRtItdDtENtWdUp 3716;
BA_ "SPN" SG_ 2566749438 DsPttFtAtvRtItdDtItSwt 3703;
BA_ "SPN" SG_ 2566749438 DsPttFtAtvRtItdDtLwExstPss 5629;
BA_ "SPN" SG_ 2566749438 DsPttFtAtvRtItdDtLwExstTpt 3711;
BA_ "SPN" SG_ 2566749438 DsPttFtAtvRtItdDtOtNt 3708;
BA_ "SPN" SG_ 2566749438 DsPttFtAtvRtItdDtPBNtSt 3710;
BA_ "SPN" SG_ 2566749438 DsPttFtAtvRtItdDtPTOAtv 3706;
BA_ "SPN" SG_ 2566749438 DsPttFtAtvRtItdDtPtSstLt 3715;
BA_ "SPN" SG_ 2566749438 DsPttFtAtvRtItdDtSstFtAtv 3712;
BA_ "SPN" SG_ 2566749438 DsPttFtAtvRtItdDtSstTt 3713;
BA_ "SPN" SG_ 2566749438 DsPttFtAtvRtItdDtSvBAtv 3705;
BA_ "SPN" SG_ 2566749438 DsPttFtAtvRtItdDtTpSstLt 3714;
BA_ "SPN" SG_ 2566749438 DsPttFtAtvRtItdDtVSpdAvAwdSpd 3709;
BA_ "SPN" SG_ 2566749438 DsPttFtAtvRtItdDtVSpdBwAwdSpd 3717;
BA_ "SPN" SG_ 2566749438 ExhstSstmHghTmprtrLmpCmmnd 3698;
BA_ "SPN" SG_ 2566749438 HydrocarbonDoserPurgingEnable 5504;
BA_ "SPN" SG_ 2566749438 DsPttFtAtvRtItdDtTs 10153;
BA_ "SPN" SG_ 2566749950 LeftHeadlampDynamicBendingLight 3691;
BA_ "SPN" SG_ 2566749950 LeftHeadlampLightDistribution 3693;
BA_ "SPN" SG_ 2566749950 RghtHdlmpDnmBndngLght 3692;
BA_ "SPN" SG_ 2566749950 RightHeadlampLightDistribution 3694;
BA_ "SPN" SG_ 2566750206 EngnCnfgrtnIdntftn 6395;
BA_ "SPN" SG_ 2566750206 MxmmCrnkAttmptsprStrtAttmpt 3670;
BA_ "SPN" SG_ 2566750206 NmrfCmstnClsfrAvrgng 6394;
BA_ "SPN" SG_ 2566750206 TrnsmssnIdlGvrnrFlngInhtSpprt 7830;
BA_ "SPN" SG_ 2566751230 TransferCaseActualGearRatio 9170;
BA_ "SPN" SG_ 2566751230 TransferCaseDirectionStatus 8849;
BA_ "SPN" SG_ 2566751230 TransferCaseMessageChecksum 9172;
BA_ "SPN" SG_ 2566751230 TransferCaseMessageCounter 9171;
BA_ "SPN" SG_ 2566751230 Transfercasestatus 3645;
BA_ "SPN" SG_ 2566751486 EngnIntkVlvAttnOlPrssrfrClndr17 3640;
BA_ "SPN" SG_ 2566751486 EngnIntkVlvAttnOlPrssrfrClndr18 3641;
BA_ "SPN" SG_ 2566751486 EngnIntkVlvAttnOlPrssrfrClndr19 3642;
BA_ "SPN" SG_ 2566751486 EngnIntkVlvAttnOlPrssrfrClndr20 3643;
BA_ "SPN" SG_ 2566751742 EngnIntkVlvAttnOlPrssrfrClndr13 3636;
BA_ "SPN" SG_ 2566751742 EngnIntkVlvAttnOlPrssrfrClndr14 3637;
BA_ "SPN" SG_ 2566751742 EngnIntkVlvAttnOlPrssrfrClndr15 3638;
BA_ "SPN" SG_ 2566751742 EngnIntkVlvAttnOlPrssrfrClndr16 3639;
BA_ "SPN" SG_ 2566751998 EngnIntkVlvAttnOlPrssrfrClndr10 3633;
BA_ "SPN" SG_ 2566751998 EngnIntkVlvAttnOlPrssrfrClndr11 3634;
BA_ "SPN" SG_ 2566751998 EngnIntkVlvAttnOlPrssrfrClndr12 3635;
BA_ "SPN" SG_ 2566751998 EngnIntkVlvAttnOlPrssrfrClndr9 3632;
BA_ "SPN" SG_ 2566752254 EngnIntkVlvAttnOlPrssrfrClndr5 3628;
BA_ "SPN" SG_ 2566752254 EngnIntkVlvAttnOlPrssrfrClndr6 3629;
BA_ "SPN" SG_ 2566752254 EngnIntkVlvAttnOlPrssrfrClndr7 3630;
BA_ "SPN" SG_ 2566752254 EngnIntkVlvAttnOlPrssrfrClndr8 3631;
BA_ "SPN" SG_ 2566752510 EngnIntkVlvAttnOlPrssrfrClndr1 3624;
BA_ "SPN" SG_ 2566752510 EngnIntkVlvAttnOlPrssrfrClndr2 3625;
BA_ "SPN" SG_ 2566752510 EngnIntkVlvAttnOlPrssrfrClndr3 3626;
BA_ "SPN" SG_ 2566752510 EngnIntkVlvAttnOlPrssrfrClndr4 3627;
BA_ "SPN" SG_ 2566752766 VehicleRoll 3623;
BA_ "SPN" SG_ 2566753278 Atttt2DsPttFtItPss 3611;
BA_ "SPN" SG_ 2566753278 Atttt2DsPttFtOttPss 3612;
BA_ "SPN" SG_ 2566753534 Atttt1DsPttFtItPss 3609;
BA_ "SPN" SG_ 2566753534 Atttt1DsPttFtOttPss 3610;
BA_ "SPN" SG_ 2566753790 UtilityTotalkVArHoursExport 3595;
BA_ "SPN" SG_ 2566753790 UtilityTotalkVArHoursImport 3596;
BA_ "SPN" SG_ 2566754046 GeneratorTotalkVArHoursExport 3593;
BA_ "SPN" SG_ 2566754046 GeneratorTotalkVArHoursImport 3594;
BA_ "SPN" SG_ 2566754302 GeneratorTotalPercentkVA 3591;
BA_ "SPN" SG_ 2566754302 GeneratorTotalPercentkVAr 3592;
BA_ "SPN" SG_ 2566754302 GeneratorTotalPercentkW 3590;
BA_ "SPN" SG_ 2566754814 AutomaticTransferSwitchStatus 3547;
BA_ "SPN" SG_ 2566754814 BusTieBreaker1 7841;
BA_ "SPN" SG_ 2566754814 BusTieBreaker2 7842;
BA_ "SPN" SG_ 2566754814 EngineLoadGroup 7843;
BA_ "SPN" SG_ 2566754814 EngineSpeedGovernorMode 7840;
BA_ "SPN" SG_ 2566754814 GeneratorCircuitBreakerStatus 3545;
BA_ "SPN" SG_ 2566754814 UtilityCircuitBreakerStatus 3546;
BA_ "SPN" SG_ 2566754814 PackageCircuitBreakerStatus 9792;
BA_ "SPN" SG_ 2566754814 SttnrInvrtrCrtBrkrStts 9793;
BA_ "SPN" SG_ 2566755582 EngnCrnksBrthrOlSprtrSpd 5444;
BA_ "SPN" SG_ 2566755582 EngnExhstGsRrltn1Vlv2Pstn 3822;
BA_ "SPN" SG_ 2566755582 EngnExhstGsRrltn1VlvPstn 27;
BA_ "SPN" SG_ 2566755582 EngnIntkMnfldCmmnddPrssr 5312;
BA_ "SPN" SG_ 2566755838 TransmissionOilLevel2HighLow 5914;
BA_ "SPN" SG_ 2566755838 TransmissionOilLevelSwitch 3533;
BA_ "SPN" SG_ 2566755838 TransmissionOilLifeRemaining 4177;
BA_ "SPN" SG_ 2566755838 TransmissionOilTemperature2 5913;
BA_ "SPN" SG_ 2566755838 TransmissionOverheatIndicator 5345;
BA_ "SPN" SG_ 2566755838 TrnsmssnOlFltrRstrtnSwth 3359;
BA_ "SPN" SG_ 2566755838 TrnsmssnOlLvl2CntdwnTmr 5915;
BA_ "SPN" SG_ 2566755838 TrnsmssnOlLvl2MsrmntStts 5916;
BA_ "SPN" SG_ 2566755838 TrnsmssnTrqCnvrtrOlOtltTmprtr 3823;
BA_ "SPN" SG_ 2566756094 EngineFuelReturnFlowRate 2774;
BA_ "SPN" SG_ 2566756094 EngineFuelSupplyFlowRate 2773;
BA_ "SPN" SG_ 2566756350 EngineFuelReturnTemperature 2776;
BA_ "SPN" SG_ 2566756350 EngineFuelSupplyTemperature 2775;
VAL_ 2566722302 GeneratorOverheatStatus 3 "NotAvailable" 2 "Error" 1 "Overheat" 0 "NotOverheat" ;
VAL_ 2566722302 GensetEnableActiveStatus 3 "NotAvaialble" 2 "Error" 1 "Enabled" 0 "NotEnabled" ;
VAL_ 2566722302 GensetSoftstartActiveStatus 3 "NotAvailable" 2 "Error" 1 "On" 0 "Off" ;
VAL_ 2566722302 ReverseCurrentRangeSetting 31 "NotAvailable" 30 "Error" 16 "11101NotUsed" 15 "16" 14 "15" 13 "14" 12 "13" 11 "12" 10 "11" 9 "10" 8 "9" 7 "8" 6 "7" 5 "6" 4 "5" 3 "4" 2 "3" 1 "2" 0 "1" ;
VAL_ 2566722302 VoltageMonitorActiveStatus 3 "NotAvailable" 2 "Error" 1 "MonitorIsOn" 0 "MonitorIsOff" ;
VAL_ 2566722814 BatteryCharger2PowerLineState 1 "CnnctdPwrLnIsCnnctdToTheCharger" 0 "DscnnctdPwrLnIsDscnnctdFrmThChr" ;
VAL_ 2566722814 BatteryCharger2State 1 "ChargingBattery" 0 "IdlngPwrLnThBttryIsDscnnctdFrmT" ;
VAL_ 2566723070 BatteryCharger1PowerLineState 1 "CnnctdPwrLnIsCnnctdToTheCharger" 0 "DscnnctdPwrLnIsDscnnctdFrmThChr" ;
VAL_ 2566723070 BatteryCharger1State 1 "ChargingBattery" 0 "IdlngPwrLnThBttryIsDscnnctdFrmT" ;
VAL_ 2566744062 ZeroNetVehicleWeightChange 3 "NotAvailable_NotApplicable" 2 "Reserved" 1 "ZeroNetVehicleWeightChange" 0 "NChangeToNetVehicleWeightChange" ;
VAL_ 2566745086 LiftAxleGroupWeightAvailable 3 "NotAvailable_NotApplicable" 2 "Reserved" 1 "LiftAxleGroupPresent" 0 "LiftAxleGroupNotPresent" ;
VAL_ 2566745086 TagAxleGroupWeightAvailable 3 "NotAvailable_NotApplicable" 2 "Reserved" 1 "TagAxleGroupPresent" 0 "TagAxleGroupNotPresent" ;
VAL_ 2566746366 Enablestatusoframp1 3 "notAvailable" 2 "error" 1 "rampEnabled" 0 "rampDisabled" ;
VAL_ 2566746366 Enablestatusoframp2 3 "notAvailable" 2 "error" 1 "rampEnabled" 0 "rampDisabled" ;
VAL_ 2566746366 Enablestatusoframp3 3 "notAvailable" 2 "error" 1 "rampEnabled" 0 "rampDisabled" ;
VAL_ 2566746366 Enablestatusoframp4 3 "notAvailable" 2 "error" 1 "rampEnabled" 0 "rampDisabled" ;
VAL_ 2566746366 Enablestatusoframp5 3 "notAvailable" 2 "error" 1 "rampEnabled" 0 "rampDisabled" ;
VAL_ 2566746366 Movementstatusoframp1 3 "notAvailable" 2 "error" 1 "rampBeingMoved" 0 "rampNotBeingMoved" ;
VAL_ 2566746366 Movementstatusoframp2 3 "notAvailable" 2 "error" 1 "rampBeingMoved" 0 "rampNotBeingMoved" ;
VAL_ 2566746366 Movementstatusoframp3 3 "notAvailable" 2 "error" 1 "rampBeingMoved" 0 "rampNotBeingMoved" ;
VAL_ 2566746366 Movementstatusoframp4 3 "notAvailable" 2 "error" 1 "rampBeingMoved" 0 "rampNotBeingMoved" ;
VAL_ 2566746366 Movementstatusoframp5 3 "notAvailable" 2 "error" 1 "rampBeingMoved" 0 "rampNotBeingMoved" ;
VAL_ 2566746366 RetractStatusoframp1 3 "notAvailable" 2 "error" 1 "rampEx" 0 "rampRetracted" ;
VAL_ 2566746366 RetractStatusoframp2 3 "notAvailable" 2 "error" 1 "rampEx" 0 "rampRetracted" ;
VAL_ 2566746366 RetractStatusoframp3 3 "notAvailable" 2 "error" 1 "rampEx" 0 "rampRetracted" ;
VAL_ 2566746366 RetractStatusoframp4 3 "notAvailable" 2 "error" 1 "rampEx" 0 "rampRetracted" ;
VAL_ 2566746366 RetractStatusoframp5 2 "error" 1 "rampEx" 0 "rampRetracted" 3 "notAvailable" ;
VAL_ 2566746622 TractorBrakeStrokeAxle1Left 7 "NotAvailable" 6 "SensorError" 5 "Reserved" 3 "DraggingBrake" 2 "Overstroke" 1 "Nonfunctioning" 0 "OK" ;
VAL_ 2566746622 TractorBrakeStrokeAxle1Right 7 "NotAvailable" 6 "SensorError" 5 "Reserved" 3 "DraggingBrake" 2 "Overstroke" 1 "Nonfunctioning" 0 "OK" ;
VAL_ 2566746622 TractorBrakeStrokeAxle2Left 7 "NotAvailable" 6 "SensorError" 5 "Reserved" 3 "DraggingBrake" 2 "Overstroke" 1 "Nonfunctioning" 0 "OK" ;
VAL_ 2566746622 TractorBrakeStrokeAxle2Right 7 "NotAvailable" 6 "SensorError" 5 "Reserved" 3 "DraggingBrake" 2 "Overstroke" 1 "Nonfunctioning" 0 "OK" ;
VAL_ 2566746622 TractorBrakeStrokeAxle3Left 7 "NotAvailable" 6 "SensorError" 5 "Reserved" 3 "DraggingBrake" 2 "Overstroke" 1 "Nonfunctioning" 0 "OK" ;
VAL_ 2566746622 TractorBrakeStrokeAxle3Right 7 "NotAvailable" 6 "SensorError" 5 "Reserved" 3 "DraggingBrake" 2 "Overstroke" 1 "Nonfunctioning" 0 "OK" ;
VAL_ 2566746622 TractorBrakeStrokeAxle4Left 7 "NotAvailable" 6 "SensorError" 5 "Reserved" 3 "DraggingBrake" 2 "Overstroke" 1 "Nonfunctioning" 0 "OK" ;
VAL_ 2566746622 TractorBrakeStrokeAxle4Right 7 "NotAvailable" 6 "SensorError" 5 "Reserved" 3 "DraggingBrake" 2 "Overstroke" 1 "Nonfunctioning" 0 "OK" ;
VAL_ 2566746622 TractorBrakeStrokeAxle5Left 7 "NotAvailable" 6 "SensorError" 5 "Reserved" 3 "DraggingBrake" 2 "Overstroke" 1 "Nonfunctioning" 0 "OK" ;
VAL_ 2566746622 TractorBrakeStrokeAxle5Right 7 "NotAvailable" 6 "SensorError" 5 "Reserved" 3 "DraggingBrake" 2 "Overstroke" 1 "Nonfunctioning" 0 "OK" ;
VAL_ 2566746622 TrailerBrakeStrokeAxle1Left 7 "NotAvailable" 6 "SensorError" 5 "Reserved" 3 "DraggingBrake" 2 "Overstroke" 1 "Nonfunctioning" 0 "OK" ;
VAL_ 2566746622 TrailerBrakeStrokeAxle1Right 7 "NotAvailable" 6 "SensorError" 5 "Reserved" 3 "DraggingBrake" 2 "Overstroke" 1 "Nonfunctioning" 0 "OK" ;
VAL_ 2566746622 TrailerBrakeStrokeAxle2Left 7 "NotAvailable" 6 "SensorError" 5 "Reserved" 3 "DraggingBrake" 2 "Overstroke" 1 "Nonfunctioning" 0 "OK" ;
VAL_ 2566746622 TrailerBrakeStrokeAxle2Right 7 "NotAvailable" 6 "SensorError" 5 "Reserved" 3 "DraggingBrake" 2 "Overstroke" 1 "Nonfunctioning" 0 "OK" ;
VAL_ 2566746622 TrailerBrakeStrokeAxle3Left 7 "NotAvailable" 6 "SensorError" 5 "Reserved" 3 "DraggingBrake" 2 "Overstroke" 1 "Nonfunctioning" 0 "OK" ;
VAL_ 2566746622 TrailerBrakeStrokeAxle3Right 7 "NotAvailable" 6 "SensorError" 5 "Reserved" 3 "DraggingBrake" 2 "Overstroke" 1 "Nonfunctioning" 0 "OK" ;
VAL_ 2566746622 TrailerBrakeStrokeAxle4Left 7 "NotAvailable" 6 "SensorError" 5 "Reserved" 3 "DraggingBrake" 2 "Overstroke" 1 "Nonfunctioning" 0 "OK" ;
VAL_ 2566746622 TrailerBrakeStrokeAxle4Right 7 "NotAvailable" 6 "SensorError" 5 "Reserved" 3 "DraggingBrake" 2 "Overstroke" 1 "Nonfunctioning" 0 "OK" ;
VAL_ 2566746622 TrailerBrakeStrokeAxle5Left 7 "NotAvailable" 6 "SensorError" 5 "Reserved" 3 "DraggingBrake" 2 "Overstroke" 1 "Nonfunctioning" 0 "OK" ;
VAL_ 2566746622 TrailerBrakeStrokeAxle5Right 7 "NotAvailable" 6 "SensorError" 5 "Reserved" 3 "DraggingBrake" 2 "Overstroke" 1 "Nonfunctioning" 0 "OK" ;
VAL_ 2566749950 LeftHeadlampDynamicBendingLight 7 "NotAvailable" 4 "110Reserved" 3 "DynmcBndngLghtFlrBndngLghtDsNtW" 2 "DynmcBndngLghtFlSfPsBndngLghtIs" 1 "DynmcBndngLghtIsWrkngPrprlyNrml" 0 "DynmcBndngLghtDctvtdThrIsNPrblm" ;
VAL_ 2566749950 LeftHeadlampLightDistribution 15 "NotAvailable" 8 "1110Reserved" 7 "DffrntLghtDstrbtnsNtAvlblNAFSDs" 6 "LghtDstrbtnFlrMdlIsDmgdCrrntPsM" 5 "LghtDstrbtnFlSfPsMdlIsDmgdCrrnt" 4 "LghtDstrbtnAdvrsWthrAdvrsWthrLg" 3 "LghtDstrbtnHghBmHghBmDstrbtnOfT" 2 "LghtDstrbtnMtrwyTskOfMtrwyLghtI" 1 "LghtDstrbtnCntryCntryLghtIsMstl" 0 "LghtDstrbtnTwnBscLghtDstrbtnFrT" ;
VAL_ 2566749950 RightHeadlampLightDistribution 15 "NotAvailable" 8 "1110Reserved" 7 "DffrntLghtDstrbtnsNtAvlblNAFSDs" 6 "LghtDstrbtnFlrMdlIsDmgdCrrntPsM" 5 "LghtDstrbtnFlSfPsMdlIsDmgdCrrnt" 4 "LghtDstrbtnAdvrsWthrAdvrsWthrLg" 3 "LghtDstrbtnHghBmHghBmDstrbtnOfT" 2 "LghtDstrbtnMtrwyTskOfMtrwyLghtI" 1 "LghtDstrbtnCntryCntryLghtIsMstl" 0 "LghtDstrbtnTwnBscLghtDstrbtnFrT" ;
VAL_ 2566751230 Transfercasestatus 7 "notAvailable" 6 "error" 5 "TrnsfrCsShftInPrgrssGrNtCnfrmed" 4 "WheelLow" 2 "neutral" 1 "WheelHigh" ;
VAL_ 2566722302 GnstSstmOtptVltgRngStts 3 "NotAvailable" 2 "Error" 1 "InRange" 0 "OutOfRange" ;
VAL_ 2566722302 GrappleMagnetSelectionSwitch 3 "NotAvailable" 2 "Error" 1 "MagnetSelected" 0 "GrappleSelected" ;
VAL_ 2566722302 GnrtrDtClExddStts 3 "NotAvaiable" 2 "Error" 1 "DutyCycleExceed" 0 "DutyCycleNotExceed" ;
VAL_ 2566730750 Aftrtrtmnt2DslExhstFldPmpStt 3 "notAvailable" 2 "reservedForSAEAssignment" 1 "pumpError" 0 "pumpOperational" ;
VAL_ 2566731518 Aftrtrtmnt2DslExhstFldTpPrprt 15 "NotAvailable" 14 "ErrrDtctdWthUrRgntTypeDetection" 13 "NtAblTDtrmneCatalystReagentType" 5 "to1100ReservedForSAEAssignment" 3 "CatalystReagentIsProperMixture" 2 "CatalystReagentIsDiesel" 1 "CtlystRgntIsUrCncntrationTooLow" 0 "CtlystRgntIsUrCncntrtionTooHigh" ;
VAL_ 2566732542 Atttt2DsExstFdDsFtSppssRqst 3 "NotAvailable" 2 "Reserved" 1 "ErrorSuppressionOn" 0 "ErrorSuppressionOff" ;
VAL_ 2566732542 Atttt2DsExstFdDsHtMdRqst 7 "NotAvailable" 4 "110Reserved" 3 "HeaterOn" 2 "HeaterAutomaticMode" 1 "HeaterEconomyMode" 0 "HeaterOff" ;
VAL_ 2566732542 Aftrtrtmnt2DslExhstFldLnHtr1 3 "notAvailable" 2 "rservedForFutureAssignmentBySAE" 1 "RqForHeaterToBeActive" 0 "RqForHeaterToBeInactive" ;
VAL_ 2566732542 Aftrtrtmnt2DslExhstFldLnHtr2 3 "notAvailable" 2 "rservedForFutureAssignmentBySAE" 1 "RqForHeaterToBeActive" 0 "RqForHeaterToBeInactive" ;
VAL_ 2566732542 Aftrtrtmnt2DslExhstFldLnHtr3 3 "notAvailable" 2 "rservedForFutureAssignmentBySAE" 1 "RqForHeaterToBeActive" 0 "RqForHeaterToBeInactive" ;
VAL_ 2566732542 Aftrtrtmnt2DslExhstFldLnHtr4 3 "notAvailable" 2 "rservedForFutureAssignmentBySAE" 1 "RqForHeaterToBeActive" 0 "RqForHeaterToBeInactive" ;
VAL_ 2566732798 Atttt2SCRDsVvExstTptRdtRqst 7 "NotAvailable" 6 "Error" 5 "RservedForFutureAssignmentBySAE" 2 "ReductionRqStage2" 1 "ReductionRqStage1" 0 "NoRq" ;
VAL_ 2566732798 Aftrtrtmnt2SCRFdkCntrlStts 7 "notAvailable" 6 "error" 5 "rservedForFutureAssignmentBySAE" 1 "closedLoopCtrlActive" 0 "openLoopCtrlActive" ;
VAL_ 2566732798 Aftrtrtmnt2DslExhstFldLnHtr1Stt 3 "notAvailable" 2 "error" 1 "heaterActive" 0 "heaterInactive" ;
VAL_ 2566732798 Aftrtrtmnt2DslExhstFldLnHtr2Stt 3 "notAvailable" 2 "error" 1 "heaterActive" 0 "heaterInactive" ;
VAL_ 2566732798 Aftrtrtmnt2DslExhstFldLnHtr3Stt 3 "notAvailable" 2 "error" 1 "heaterActive" 0 "heaterInactive" ;
VAL_ 2566732798 Aftrtrtmnt2DslExhstFldLnHtr4Stt 3 "notAvailable" 2 "error" 1 "heaterActive" 0 "heaterInactive" ;
VAL_ 2566733054 Aftrtrtmnt1DslExhstFldPmpStt 3 "notAvailable" 2 "reservedForSAEAssignment" 1 "pumpError" 0 "pumpOperational" ;
VAL_ 2566734078 Atttt1DsExstFdDsFtSppssRqst 3 "NotAvailable" 2 "Reserved" 1 "ErrorSuppressionOn" 0 "ErrorSuppressionOff" ;
VAL_ 2566734078 Atttt1DsExstFdDsHtMdRqst 7 "NotAvailable" 4 "110Reserved" 3 "HeaterOn" 2 "HeaterAutomaticMode" 1 "HeaterEconomyMode" 0 "HeaterOff" ;
VAL_ 2566734078 Aftrtrtmnt1DslExhstFldLnHtr1 3 "notAvailable" 2 "rservedForFutureAssignmentBySAE" 1 "RqForHeaterToBeActive" 0 "RqForHeaterToBeInactive" ;
VAL_ 2566734078 Aftrtrtmnt1DslExhstFldLnHtr2 3 "notAvailable" 2 "rservedForFutureAssignmentBySAE" 1 "RqForHeaterToBeActive" 0 "RqForHeaterToBeInactive" ;
VAL_ 2566734078 Aftrtrtmnt1DslExhstFldLnHtr3 3 "notAvailable" 2 "rservedForFutureAssignmentBySAE" 1 "RqForHeaterToBeActive" 0 "RqForHeaterToBeInactive" ;
VAL_ 2566734078 Aftrtrtmnt1DslExhstFldLnHtr4 3 "notAvailable" 2 "rservedForFutureAssignmentBySAE" 1 "RqForHeaterToBeActive" 0 "RqForHeaterToBeInactive" ;
VAL_ 2566734334 Atttt1SCRDsVvExstTptRdtRqst 7 "NotAvailable" 6 "Error" 5 "RservedForFutureAssignmentBySAE" 2 "ReductionRqStage2" 1 "ReductionRqStage1" 0 "NoRq" ;
VAL_ 2566734334 Aftrtrtmnt1SCRFdkCntrlStts 7 "notAvailable" 6 "error" 5 "rservedForFutureAssignmentBySAE" 1 "closedLoopCtrlActive" 0 "openLoopCtrlActive" ;
VAL_ 2566734334 Aftrtrtmnt1DslExhstFldLnHtr1Stt 3 "notAvailable" 2 "error" 1 "heaterActive" 0 "heaterInactive" ;
VAL_ 2566734334 Aftrtrtmnt1DslExhstFldLnHtr2Stt 3 "notAvailable" 2 "error" 1 "heaterActive" 0 "heaterInactive" ;
VAL_ 2566734334 Aftrtrtmnt1DslExhstFldLnHtr3Stt 3 "notAvailable" 2 "error" 1 "heaterActive" 0 "heaterInactive" ;
VAL_ 2566734334 Aftrtrtmnt1DslExhstFldLnHtr4Stt 3 "notAvailable" 2 "error" 1 "heaterActive" 0 "heaterInactive" ;
VAL_ 2566735102 Aftrtrtmnt2FlPmpRlCntrl 3 "notAvailable" 2 "reservedForSAEAssignment" 1 "on" 0 "off" ;
VAL_ 2566735102 Aftrtrtmnt2FlFlwDvrtrVlvCntrl 3 "notAvailable" 2 "reservedForSAEAssignment" 1 "on" 0 "off" ;
VAL_ 2566736126 EngnExhstBnk2O2SnsrClsdLpOprtn 15 "NotSupported" 5 "1110Reserved" 4 "ClsdLpBtFltWthAtLstOnOxygnSnsrM" 3 "OpnLoopDueToDetectedSystemFault" 2 "OpenLoopDueToDrivingConditions" 1 "ClsdLpUsngOxygnSnsrAsFdbckFrFlC" 0 "OpnLpHsNtYtStsfdCndtnsTGClsdLop" ;
VAL_ 2566736382 EngnExhstBnk1O2SnsrClsdLpOprtn 15 "NotSupported" 5 "1110Reserved" 4 "ClsdLpBtFltWthAtLstOnOxygnSnsrM" 3 "OpnLoopDueToDetectedSystemFault" 2 "OpenLoopDueToDrivingConditions" 1 "ClsdLpUsngOxygnSnsrAsFdbckFrFlC" 0 "OpnLpHsNtYtStsfdCndtnsTGClsdLop" ;
VAL_ 2566743550 Aftrtrtmnt1FlPmpRlCntrl 3 "notAvailable" 2 "reservedForSAEAssignment" 1 "on" 0 "off" ;
VAL_ 2566743550 Aftrtrtmnt1FlFlwDvrtrVlvCntrl 3 "notAvailable" 2 "reservedForSAEAssignment" 1 "on" 0 "off" ;
VAL_ 2566745086 SlrFrwrdmstStrAxlGrpWghtAvll 3 "NotAvailable_NotApplicable" 2 "Reserved" 1 "SteerAxleGroupPresent" 0 "SteerAxleGroupNotPresent" ;
VAL_ 2566745086 SlrFrwrdmstDrvAxlGrpWghtAvll 3 "NotAvailable_NotApplicable" 2 "Reserved" 1 "DriveAxleGroupPresent" 0 "DriveAxleGroupNotPresent" ;
VAL_ 2566745086 AddtnlTrtrAxlGrpWghtAvll 3 "NotAvailable_NotApplicable" 2 "Reserved" 1 "AddtonalTractorAxleGroupPresent" 0 "AddtnlTrctorAxleGroupNotPresent" ;
VAL_ 2566745086 TrlrAAxlGrpWghtAvll 3 "NotAvailable_NotApplicable" 2 "Reserved" 1 "TrailerAAxleGroupPresent" 0 "TrailerAAxleGroupNotPresent" ;
VAL_ 2566745086 TrlrBAxlGrpWghtAvll 3 "NotAvailable_NotApplicable" 2 "Reserved" 1 "TrailerBAxleGroupPresent" 0 "TrailerBAxleGroupNotPresent" ;
VAL_ 2566745086 TrlrCAxlGrpWghtAvll 3 "NotAvailable_NotApplicable" 2 "Reserved" 1 "TrailerCAxleGroupPresent" 0 "TrailerCAxleGroupNotPresent" ;
VAL_ 2566745086 TrlrDAxlGrpWghtAvll 3 "NotAvailable_NotApplicable" 2 "Reserved" 1 "TrailerDAxleGroupPresent" 0 "TrailerDAxleGroupNotPresent" ;
VAL_ 2566745086 TrlrEAxlGrpWghtAvll 3 "NotAvailable_NotApplicable" 2 "Reserved" 1 "TrailerEAxleGroupPresent" 0 "TrailerEAxleGroupNotPresent" ;
VAL_ 2566745086 TrlrFAxlGrpWghtAvll 3 "NotAvailable_NotApplicable" 2 "Reserved" 1 "TrailerFAxleGroupPresent" 0 "TrailerFAxleGroupNotPresent" ;
VAL_ 2566745086 TrlrGAxlGrpWghtAvll 3 "NotAvailable_NotApplicable" 2 "Reserved" 1 "TrailerGAxleGroupPresent" 0 "TrailerGAxleGroupNotPresent" ;
VAL_ 2566745086 TrlrHAxlGrpWghtAvll 3 "NotAvailable_NotApplicable" 2 "Reserved" 1 "TrailerHAxleGroupPresent" 0 "TrailerHAxleGroupNotPresent" ;
VAL_ 2566745086 AddtnlTrlrAxlGrpWghtAvll 3 "NotAvailable_NotApplicable" 2 "Reserved" 1 "AddtonalTrailerAxleGroupPresent" 0 "AddtnlTrilerAxleGroupNotPresent" ;
VAL_ 2566749438 DslPrtltFltrLmpCmmnd 7 "notAvailable" 4 "OnFastBlink" 6 "reservedForSAEAssignment" 1 "OnSolid" 0 "Off" ;
VAL_ 2566749438 AttttDsPttFtPssvRtStts 3 "notAvailable" 2 "reservedForSAEAssignment" 1 "active" 0 "notActive" ;
VAL_ 2566749438 AttttDsPttFtAtvRtStts 3 "notAvailable" 2 "rgnrtnNddAtmtcllyInttdActvRgnrt" 1 "active" 0 "notActive" ;
VAL_ 2566749438 AftrtrtmntDslPrtltFltrStts 7 "notAvailable" 6 "reservedForSAEAssignment" 3 "RegenerationNeededHighestLevel" 2 "RegenerationNeededModerateLevel" 1 "RegenerationNeededLowestLevel" 0 "RegenerationNotNeeded" ;
VAL_ 2566749438 DslPrtltFltrAtvRgnrtnInhtdStts 3 "notAvailable" 2 "reservedForSAEAssignment" 1 "inhibited" 0 "notInhibited" ;
VAL_ 2566749438 DsPttFtAtvRtItdDtItSwt 3 "notAvailable" 2 "reservedForSAEAssignment" 1 "inhibited" 0 "notInhibited" ;
VAL_ 2566749438 DsPttFtAtvRtItdDtCtDsd 3 "notAvailable" 2 "reservedForSAEAssignment" 1 "inhibited" 0 "notInhibited" ;
VAL_ 2566749438 DsPttFtAtvRtItdDtSvBAtv 3 "notAvailable" 2 "reservedForSAEAssignment" 1 "inhibited" 0 "notInhibited" ;
VAL_ 2566749438 DsPttFtAtvRtItdDtPTOAtv 3 "notAvailable" 2 "reservedForSAEAssignment" 1 "inhibited" 0 "notInhibited" ;
VAL_ 2566749438 DsPttFtAtvRtItdDtAtPdOId 3 "notAvailable" 2 "reservedForSAEAssignment" 1 "inhibited" 0 "notInhibited" ;
VAL_ 2566749438 DsPttFtAtvRtItdDtOtNt 3 "notAvailable" 2 "reservedForSAEAssignment" 1 "inhibited" 0 "notInhibited" ;
VAL_ 2566749438 DsPttFtAtvRtItdDtVSpdAvAwdSpd 3 "notAvailable" 2 "reservedForSAEAssignment" 1 "inhibited" 0 "notInhibited" ;
VAL_ 2566749438 DsPttFtAtvRtItdDtPBNtSt 3 "notAvailable" 2 "reservedForSAEAssignment" 1 "inhibited" 0 "notInhibited" ;
VAL_ 2566749438 DsPttFtAtvRtItdDtLwExstTpt 3 "notAvailable" 2 "reservedForSAEAssignment" 1 "inhibited" 0 "notInhibited" ;
VAL_ 2566749438 DsPttFtAtvRtItdDtSstFtAtv 3 "notAvailable" 2 "reservedForSAEAssignment" 1 "inhibited" 0 "notInhibited" ;
VAL_ 2566749438 DsPttFtAtvRtItdDtSstTt 3 "notAvailable" 2 "reservedForSAEAssignment" 1 "inhibited" 0 "notInhibited" ;
VAL_ 2566749438 DsPttFtAtvRtItdDtTpSstLt 3 "notAvailable" 2 "reservedForSAEAssignment" 1 "inhibited" 0 "notInhibited" ;
VAL_ 2566749438 DsPttFtAtvRtItdDtPtSstLt 3 "notAvailable" 2 "reservedForSAEAssignment" 1 "inhibited" 0 "notInhibited" ;
VAL_ 2566749438 DsPttFtAtvRtItdDtENtWdUp 3 "notAvailable" 2 "reservedForSAEAssignment" 1 "inhibited" 0 "notInhibited" ;
VAL_ 2566749438 DsPttFtAtvRtItdDtVSpdBwAwdSpd 3 "notAvailable" 2 "reservedForSAEAssignment" 1 "inhibited" 0 "notInhibited" ;
VAL_ 2566749438 DsPttFtAttAtvRtIttCt 3 "notAvailable" 2 "reservedForSAEAssignment" 1 "enabled" 0 "notEnabled" ;
VAL_ 2566749438 ExhstSstmHghTmprtrLmpCmmnd 7 "notAvailable" 6 "reservedForSAEAssignment" 1 "OnSolid" 0 "Off" ;
VAL_ 2566749438 DslPrtltFltrAtvRgnrtnFrdStts 7 "notAvailable" 6 "ReservedForSAEAssignment" 2 "ActiveForcedByServiceTool" 1 "ActiveForcedBySwitch" 0 "NotActive" ;
VAL_ 2566749950 RghtHdlmpDnmBndngLght 7 "NotAvailable" 4 "110Reserved" 3 "DynmcBndngLghtFlrBndngLghtDsNtW" 2 "DynmcBndngLghtFlSfPsBndngLghtIs" 1 "DynmcBndngLghtIsWrkngPrprlyNrml" 0 "DynmcBndngLghtDctvtdThrIsNPrblm" ;
VAL_ 2566755838 TrnsmssnOlFltrRstrtnSwth 3 "NotAvailable" 2 "Error" 1 "RestrictionExistsOnOilFilter" 0 "NoRestriction" ;
VAL_ 2566755838 TransmissionOilLevelSwitch 3 "NotAvailable" 2 "Error" 1 "FullNotEmpty" 0 "Empty" ;
VAL_ 2566755838 TransmissionOverheatIndicator 3 "NotAvailable" 2 "TrnsOverheatIndicatorIsFlashing" 1 "TrnsOvrhtIndctrIsOnContinuously" 0 "TransOverheatIndicatorIsOff" ;
